VERSION ""

NS_ :

BS_:

BU_: PowertrainControlModule AtmosphericSensor SafetyRestraintSystem2 Aftertreatment_2_GasOutlet Aftertreatment_2_GasIntake DieselParticulateFilterControl Turbocharger SafetyRestraintSystem1 CabDisplay2 Aftertreatment_1_GasOutlet Aftertreatment_1_GasIntake OnBoardDataLogger OffBoardDiagnosticTool2 OffBoardDiagnosticTool1 FileServer ParkingBrakeController SeatController2 FanDriveController SteeringColumnUnit CommunicationUnitRadio CommunicationUnitSatellite CommunicationUnitCellular PropulsionBatteryCharger ChassisController2 ChassisController1 EngineValveControl AuxiliaryHeater2 AuxiliaryHeater1 ClutchUnit RampControl InformationSystem1 SuspensionSystemController2 OilSensor VehicleDynamicStability ExhaustEmissionController TransmissionDisplay2 TransmissionDisplay1 ClimateControl2 WaterPumpController RearAxleSteeringController LightingOperatorControl SeatController1 IgnitionController2 IgnitionController1 TirePressureController CabController2 CabController1 PneumaticSystemController SuspensionSystemController1 HydraulicPumpController EnduranceBrakingSystem RetarderExhaustEngine2 OnBoardDiagnosticUnit HeadwayController RetarderExhaustEngine1 CabDisplay1 ManagementComputer VirtualTerminal OffVehicleGateway PowerTakeOffFront HitchControl AuxiliaryValveControl BodyController TractorTrailerBridge1 StarterSystem ElectricalSystem VehicleSecurity VehicleNavigation AerodynamicControl ElectricalChargingSystem ClimateControl1 TripRecorder InstrumentCluster SuspensionDriveAxle2 SuspensionDriveAxle1 SuspensionSteerAxle SteeringController FuelSystem CruiseControl RetarderDriveline RetarderEngine BrakesDriveAxle2 BrakesDriveAxle1 BrakesSystemController BrakesSteerAxle AxleDrive2 AxleDrive1 AxleSteering PowerTakeOff ShiftConsoleSecondary ShiftConsolePrimary Transmission2 Transmission1 Engine2 Engine1

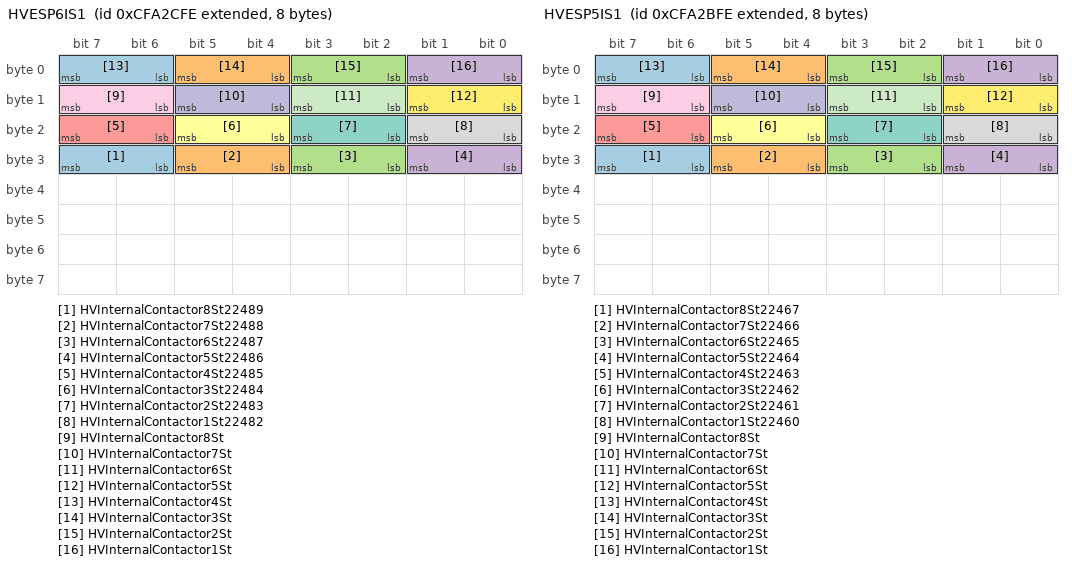
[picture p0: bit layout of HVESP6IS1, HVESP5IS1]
BO_ 2365205758 HVESP6IS1: 8 Vector__XXX
 SG_ HVInternalContactor8St22489 : 30|2@1+ (1,0) [0|3] "" Vector__XXX
 SG_ HVInternalContactor7St22488 : 28|2@1+ (1,0) [0|3] "" Vector__XXX
 SG_ HVInternalContactor6St22487 : 26|2@1+ (1,0) [0|3] "" Vector__XXX
 SG_ HVInternalContactor5St22486 : 24|2@1+ (1,0) [0|3] "" Vector__XXX
 SG_ HVInternalContactor4St22485 : 22|2@1+ (1,0) [0|3] "" Vector__XXX
 SG_ HVInternalContactor3St22484 : 20|2@1+ (1,0) [0|3] "" Vector__XXX
 SG_ HVInternalContactor2St22483 : 18|2@1+ (1,0) [0|3] "" Vector__XXX
 SG_ HVInternalContactor1St22482 : 16|2@1+ (1,0) [0|3] "" Vector__XXX
 SG_ HVInternalContactor8St : 14|2@1+ (1,0) [0|3] "" Vector__XXX
 SG_ HVInternalContactor7St : 12|2@1+ (1,0) [0|3] "" Vector__XXX
 SG_ HVInternalContactor6St : 10|2@1+ (1,0) [0|3] "" Vector__XXX
 SG_ HVInternalContactor5St : 8|2@1+ (1,0) [0|3] "" Vector__XXX
 SG_ HVInternalContactor4St : 6|2@1+ (1,0) [0|3] "" Vector__XXX
 SG_ HVInternalContactor3St : 4|2@1+ (1,0) [0|3] "" Vector__XXX
 SG_ HVInternalContactor2St : 2|2@1+ (1,0) [0|3] "" Vector__XXX
 SG_ HVInternalContactor1St : 0|2@1+ (1,0) [0|3] "" Vector__XXX

BO_ 2365205502 HVESP5IS1: 8 Vector__XXX
 SG_ HVInternalContactor8St22467 : 30|2@1+ (1,0) [0|3] "" Vector__XXX
 SG_ HVInternalContactor7St22466 : 28|2@1+ (1,0) [0|3] "" Vector__XXX
 SG_ HVInternalContactor6St22465 : 26|2@1+ (1,0) [0|3] "" Vector__XXX
 SG_ HVInternalContactor5St22464 : 24|2@1+ (1,0) [0|3] "" Vector__XXX
 SG_ HVInternalContactor4St22463 : 22|2@1+ (1,0) [0|3] "" Vector__XXX
 SG_ HVInternalContactor3St22462 : 20|2@1+ (1,0) [0|3] "" Vector__XXX
 SG_ HVInternalContactor2St22461 : 18|2@1+ (1,0) [0|3] "" Vector__XXX
 SG_ HVInternalContactor1St22460 : 16|2@1+ (1,0) [0|3] "" Vector__XXX
 SG_ HVInternalContactor8St : 14|2@1+ (1,0) [0|3] "" Vector__XXX
 SG_ HVInternalContactor7St : 12|2@1+ (1,0) [0|3] "" Vector__XXX
 SG_ HVInternalContactor6St : 10|2@1+ (1,0) [0|3] "" Vector__XXX
 SG_ HVInternalContactor5St : 8|2@1+ (1,0) [0|3] "" Vector__XXX
 SG_ HVInternalContactor4St : 6|2@1+ (1,0) [0|3] "" Vector__XXX
 SG_ HVInternalContactor3St : 4|2@1+ (1,0) [0|3] "" Vector__XXX
 SG_ HVInternalContactor2St : 2|2@1+ (1,0) [0|3] "" Vector__XXX
 SG_ HVInternalContactor1St : 0|2@1+ (1,0) [0|3] "" Vector__XXX

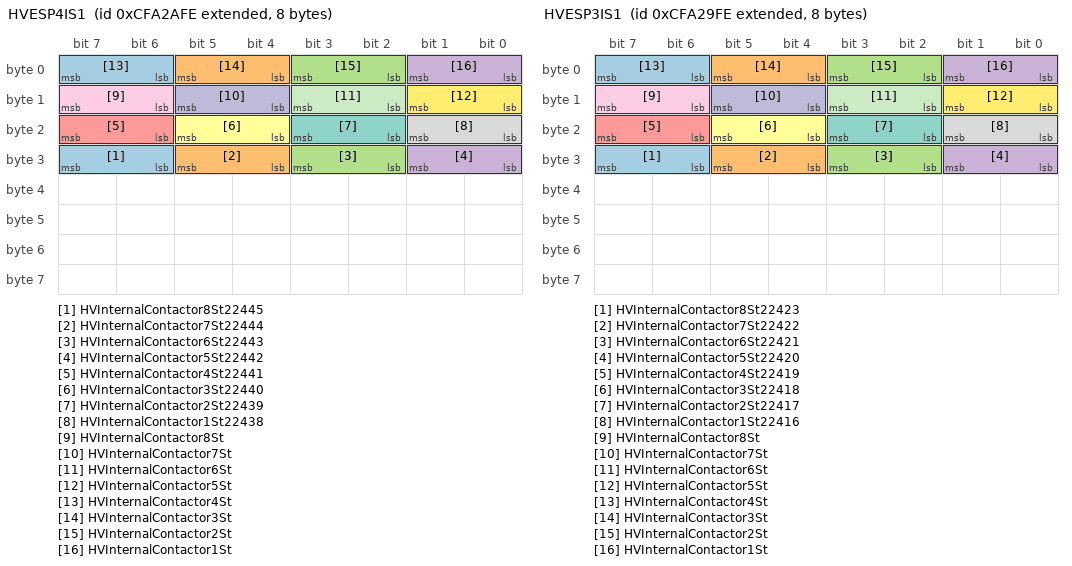
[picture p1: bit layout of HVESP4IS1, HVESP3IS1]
BO_ 2365205246 HVESP4IS1: 8 Vector__XXX
 SG_ HVInternalContactor8St22445 : 30|2@1+ (1,0) [0|3] "" Vector__XXX
 SG_ HVInternalContactor7St22444 : 28|2@1+ (1,0) [0|3] "" Vector__XXX
 SG_ HVInternalContactor6St22443 : 26|2@1+ (1,0) [0|3] "" Vector__XXX
 SG_ HVInternalContactor5St22442 : 24|2@1+ (1,0) [0|3] "" Vector__XXX
 SG_ HVInternalContactor4St22441 : 22|2@1+ (1,0) [0|3] "" Vector__XXX
 SG_ HVInternalContactor3St22440 : 20|2@1+ (1,0) [0|3] "" Vector__XXX
 SG_ HVInternalContactor2St22439 : 18|2@1+ (1,0) [0|3] "" Vector__XXX
 SG_ HVInternalContactor1St22438 : 16|2@1+ (1,0) [0|3] "" Vector__XXX
 SG_ HVInternalContactor8St : 14|2@1+ (1,0) [0|3] "" Vector__XXX
 SG_ HVInternalContactor7St : 12|2@1+ (1,0) [0|3] "" Vector__XXX
 SG_ HVInternalContactor6St : 10|2@1+ (1,0) [0|3] "" Vector__XXX
 SG_ HVInternalContactor5St : 8|2@1+ (1,0) [0|3] "" Vector__XXX
 SG_ HVInternalContactor4St : 6|2@1+ (1,0) [0|3] "" Vector__XXX
 SG_ HVInternalContactor3St : 4|2@1+ (1,0) [0|3] "" Vector__XXX
 SG_ HVInternalContactor2St : 2|2@1+ (1,0) [0|3] "" Vector__XXX
 SG_ HVInternalContactor1St : 0|2@1+ (1,0) [0|3] "" Vector__XXX

BO_ 2365204990 HVESP3IS1: 8 Vector__XXX
 SG_ HVInternalContactor8St22423 : 30|2@1+ (1,0) [0|3] "" Vector__XXX
 SG_ HVInternalContactor7St22422 : 28|2@1+ (1,0) [0|3] "" Vector__XXX
 SG_ HVInternalContactor6St22421 : 26|2@1+ (1,0) [0|3] "" Vector__XXX
 SG_ HVInternalContactor5St22420 : 24|2@1+ (1,0) [0|3] "" Vector__XXX
 SG_ HVInternalContactor4St22419 : 22|2@1+ (1,0) [0|3] "" Vector__XXX
 SG_ HVInternalContactor3St22418 : 20|2@1+ (1,0) [0|3] "" Vector__XXX
 SG_ HVInternalContactor2St22417 : 18|2@1+ (1,0) [0|3] "" Vector__XXX
 SG_ HVInternalContactor1St22416 : 16|2@1+ (1,0) [0|3] "" Vector__XXX
 SG_ HVInternalContactor8St : 14|2@1+ (1,0) [0|3] "" Vector__XXX
 SG_ HVInternalContactor7St : 12|2@1+ (1,0) [0|3] "" Vector__XXX
 SG_ HVInternalContactor6St : 10|2@1+ (1,0) [0|3] "" Vector__XXX
 SG_ HVInternalContactor5St : 8|2@1+ (1,0) [0|3] "" Vector__XXX
 SG_ HVInternalContactor4St : 6|2@1+ (1,0) [0|3] "" Vector__XXX
 SG_ HVInternalContactor3St : 4|2@1+ (1,0) [0|3] "" Vector__XXX
 SG_ HVInternalContactor2St : 2|2@1+ (1,0) [0|3] "" Vector__XXX
 SG_ HVInternalContactor1St : 0|2@1+ (1,0) [0|3] "" Vector__XXX

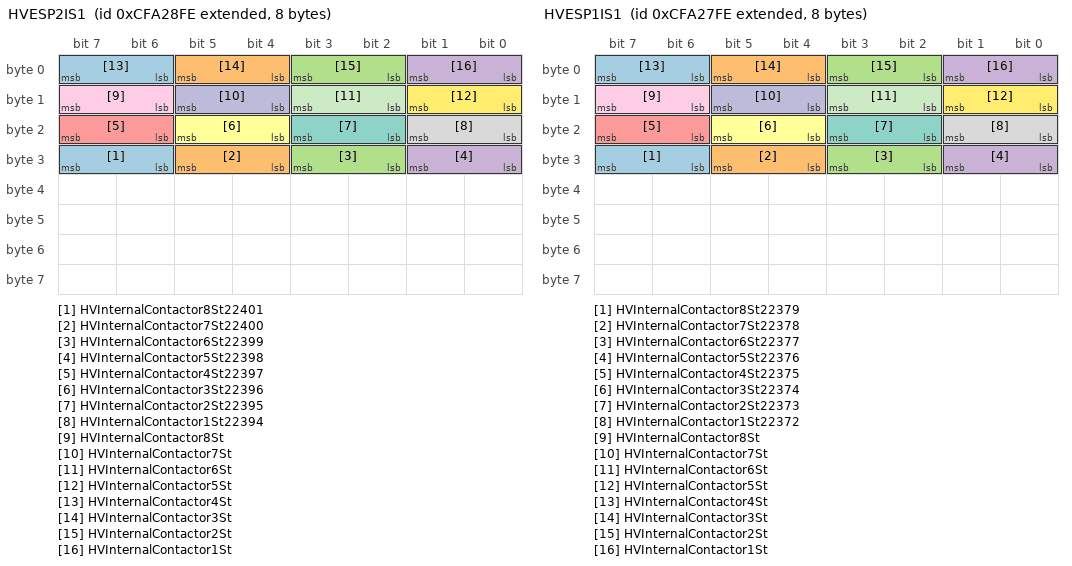
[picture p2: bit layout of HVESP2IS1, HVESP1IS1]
BO_ 2365204734 HVESP2IS1: 8 Vector__XXX
 SG_ HVInternalContactor8St22401 : 30|2@1+ (1,0) [0|3] "" Vector__XXX
 SG_ HVInternalContactor7St22400 : 28|2@1+ (1,0) [0|3] "" Vector__XXX
 SG_ HVInternalContactor6St22399 : 26|2@1+ (1,0) [0|3] "" Vector__XXX
 SG_ HVInternalContactor5St22398 : 24|2@1+ (1,0) [0|3] "" Vector__XXX
 SG_ HVInternalContactor4St22397 : 22|2@1+ (1,0) [0|3] "" Vector__XXX
 SG_ HVInternalContactor3St22396 : 20|2@1+ (1,0) [0|3] "" Vector__XXX
 SG_ HVInternalContactor2St22395 : 18|2@1+ (1,0) [0|3] "" Vector__XXX
 SG_ HVInternalContactor1St22394 : 16|2@1+ (1,0) [0|3] "" Vector__XXX
 SG_ HVInternalContactor8St : 14|2@1+ (1,0) [0|3] "" Vector__XXX
 SG_ HVInternalContactor7St : 12|2@1+ (1,0) [0|3] "" Vector__XXX
 SG_ HVInternalContactor6St : 10|2@1+ (1,0) [0|3] "" Vector__XXX
 SG_ HVInternalContactor5St : 8|2@1+ (1,0) [0|3] "" Vector__XXX
 SG_ HVInternalContactor4St : 6|2@1+ (1,0) [0|3] "" Vector__XXX
 SG_ HVInternalContactor3St : 4|2@1+ (1,0) [0|3] "" Vector__XXX
 SG_ HVInternalContactor2St : 2|2@1+ (1,0) [0|3] "" Vector__XXX
 SG_ HVInternalContactor1St : 0|2@1+ (1,0) [0|3] "" Vector__XXX

BO_ 2365204478 HVESP1IS1: 8 Vector__XXX
 SG_ HVInternalContactor8St22379 : 30|2@1+ (1,0) [0|3] "" Vector__XXX
 SG_ HVInternalContactor7St22378 : 28|2@1+ (1,0) [0|3] "" Vector__XXX
 SG_ HVInternalContactor6St22377 : 26|2@1+ (1,0) [0|3] "" Vector__XXX
 SG_ HVInternalContactor5St22376 : 24|2@1+ (1,0) [0|3] "" Vector__XXX
 SG_ HVInternalContactor4St22375 : 22|2@1+ (1,0) [0|3] "" Vector__XXX
 SG_ HVInternalContactor3St22374 : 20|2@1+ (1,0) [0|3] "" Vector__XXX
 SG_ HVInternalContactor2St22373 : 18|2@1+ (1,0) [0|3] "" Vector__XXX
 SG_ HVInternalContactor1St22372 : 16|2@1+ (1,0) [0|3] "" Vector__XXX
 SG_ HVInternalContactor8St : 14|2@1+ (1,0) [0|3] "" Vector__XXX
 SG_ HVInternalContactor7St : 12|2@1+ (1,0) [0|3] "" Vector__XXX
 SG_ HVInternalContactor6St : 10|2@1+ (1,0) [0|3] "" Vector__XXX
 SG_ HVInternalContactor5St : 8|2@1+ (1,0) [0|3] "" Vector__XXX
 SG_ HVInternalContactor4St : 6|2@1+ (1,0) [0|3] "" Vector__XXX
 SG_ HVInternalContactor3St : 4|2@1+ (1,0) [0|3] "" Vector__XXX
 SG_ HVInternalContactor2St : 2|2@1+ (1,0) [0|3] "" Vector__XXX
 SG_ HVInternalContactor1St : 0|2@1+ (1,0) [0|3] "" Vector__XXX

BO_ 2365204222 HVESSD14: 8 Vector__XXX
 SG_ BusV : 32|16@1+ (0.125,0) [0|8031.875] "V" Vector__XXX
 SG_ MaxCurChargeCurLmt : 16|16@1+ (0.125,-4000) [0|4031.875] "A" Vector__XXX
 SG_ MaxCurDisCurLmt : 0|16@1+ (0.125,-4000) [-4000|0] "A" Vector__XXX

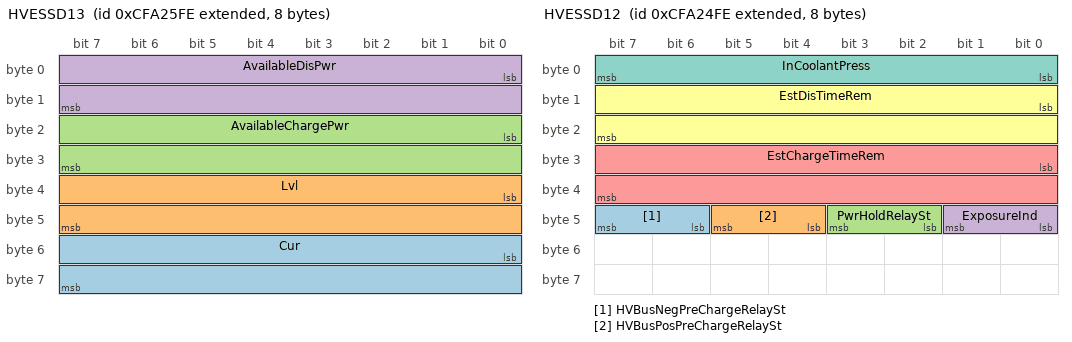
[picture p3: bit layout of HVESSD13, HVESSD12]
BO_ 2365203966 HVESSD13: 8 Vector__XXX
 SG_ Cur : 48|16@1+ (0.125,-4000) [-4000|4031.875] "A" Vector__XXX
 SG_ Lvl : 32|16@1+ (0.125,0) [0|8031.875] "V" Vector__XXX
 SG_ AvailableChargePwr : 16|16@1+ (0.25,0) [0|16063.75] "kW" Vector__XXX
 SG_ AvailableDisPwr : 0|16@1+ (0.25,0) [0|16063.75] "kW" Vector__XXX

BO_ 2365203710 HVESSD12: 8 Vector__XXX
 SG_ HVBusNegPreChargeRelaySt : 46|2@1+ (1,0) [0|3] "" Vector__XXX
 SG_ HVBusPosPreChargeRelaySt : 44|2@1+ (1,0) [0|3] "" Vector__XXX
 SG_ PwrHoldRelaySt : 42|2@1+ (1,0) [0|3] "" Vector__XXX
 SG_ ExposureInd : 40|2@1+ (1,0) [0|3] "" Vector__XXX
 SG_ EstChargeTimeRem : 24|16@1+ (0.1,0) [0|6425.5] "min" Vector__XXX
 SG_ EstDisTimeRem : 8|16@1+ (0.1,0) [0|6425.5] "min" Vector__XXX
 SG_ InCoolantPress : 0|8@1+ (2,0) [0|500] "kPa" Vector__XXX

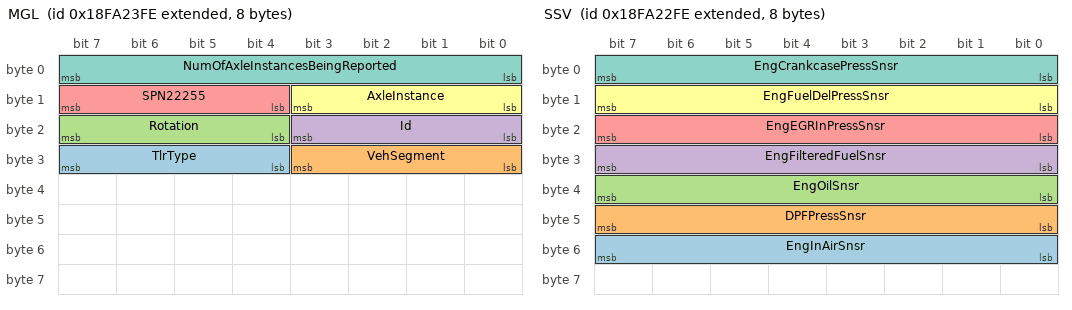
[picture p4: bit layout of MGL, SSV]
BO_ 2566530046 MGL: 8 Vector__XXX
 SG_ TlrType : 28|4@1+ (1,0) [0|15] "" Vector__XXX
 SG_ VehSegment : 24|4@1+ (1,0) [0|15] "" Vector__XXX
 SG_ Rotation : 20|4@1+ (1,0) [0|15] "" Vector__XXX
 SG_ Id : 16|4@1+ (1,0) [0|15] "" Vector__XXX
 SG_ SPN22255 : 12|4@1+ (1,0) [0|15] "" Vector__XXX
 SG_ AxleInstance : 8|4@1+ (1,0) [0|15] "" Vector__XXX
 SG_ NumOfAxleInstancesBeingReported : 0|8@1+ (1,0) [0|255] "" Vector__XXX

BO_ 2566529790 SSV: 8 Vector__XXX
 SG_ EngInAirSnsr : 48|8@1+ (0.05,0) [0|12.5] "V" Vector__XXX
 SG_ DPFPressSnsr : 40|8@1+ (0.05,0) [0|12.5] "V" Vector__XXX
 SG_ EngOilSnsr : 32|8@1+ (0.05,0) [0|12.5] "V" Vector__XXX
 SG_ EngFilteredFuelSnsr : 24|8@1+ (0.05,0) [0|12.5] "V" Vector__XXX
 SG_ EngEGRInPressSnsr : 16|8@1+ (0.05,0) [0|12.5] "V" Vector__XXX
 SG_ EngFuelDelPressSnsr : 8|8@1+ (0.05,0) [0|12.5] "V" Vector__XXX
 SG_ EngCrankcasePressSnsr : 0|8@1+ (0.05,0) [0|12.5] "V" Vector__XXX

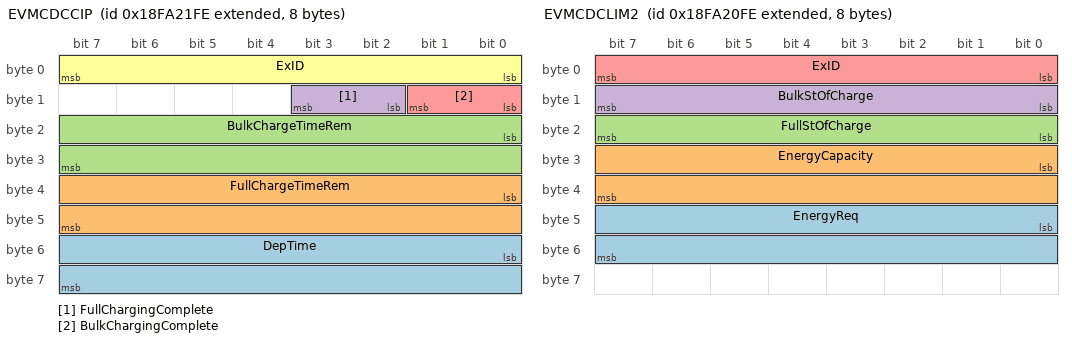
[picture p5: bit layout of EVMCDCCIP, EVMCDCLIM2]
BO_ 2566529534 EVMCDCCIP: 8 Vector__XXX
 SG_ DepTime : 48|16@1+ (10,0) [0|642550] "s" Vector__XXX
 SG_ FullChargeTimeRem : 32|16@1+ (10,0) [0|642550] "s" Vector__XXX
 SG_ BulkChargeTimeRem : 16|16@1+ (10,0) [0|642550] "s" Vector__XXX
 SG_ FullChargingComplete : 10|2@1+ (1,0) [0|3] "" Vector__XXX
 SG_ BulkChargingComplete : 8|2@1+ (1,0) [0|3] "" Vector__XXX
 SG_ ExID : 0|8@1+ (1,0) [0|255] "" Vector__XXX

BO_ 2566529278 EVMCDCLIM2: 8 Vector__XXX
 SG_ EnergyReq : 40|16@1+ (1,0) [0|64255] "kWh" Vector__XXX
 SG_ EnergyCapacity : 24|16@1+ (1,0) [0|64255] "kWh" Vector__XXX
 SG_ FullStOfCharge : 16|8@1+ (0.5,0) [0|125] "%" Vector__XXX
 SG_ BulkStOfCharge : 8|8@1+ (0.5,0) [0|125] "%" Vector__XXX
 SG_ ExID : 0|8@1+ (1,0) [0|255] "" Vector__XXX

BO_ 2633637886 ASI6: 8 Vector__XXX
 SG_ TwoDEFDosingMode : 0|8@1+ (1,0) [0|250] "" Vector__XXX

BO_ 2365202174 HVBCS: 8 Vector__XXX
 SG_ CRC : 56|8@1+ (1,0) [0|255] "" Vector__XXX
 SG_ Counter : 52|4@1+ (1,0) [0|15] "" Vector__XXX
 SG_ EmbeddedIntegritySupport : 50|2@1+ (1,0) [0|3] "" Vector__XXX
 SG_ HVBusInterface8NegContactorSt : 30|2@1+ (1,0) [0|3] "" Vector__XXX
 SG_ HVBusInterface8PosContactorSt : 28|2@1+ (1,0) [0|3] "" Vector__XXX
 SG_ HVBusInterface7NegContactorSt : 26|2@1+ (1,0) [0|3] "" Vector__XXX
 SG_ HVBusInterface7PosContactorSt : 24|2@1+ (1,0) [0|3] "" Vector__XXX
 SG_ HVBusInterface6NegContactorSt : 22|2@1+ (1,0) [0|3] "" Vector__XXX
 SG_ HVBusInterface6PosContactorSt : 20|2@1+ (1,0) [0|3] "" Vector__XXX
 SG_ HVBusInterface5NegContactorSt : 18|2@1+ (1,0) [0|3] "" Vector__XXX
 SG_ HVBusInterface5PosContactorSt : 16|2@1+ (1,0) [0|3] "" Vector__XXX
 SG_ HVBusInterface4NegContactorSt : 14|2@1+ (1,0) [0|3] "" Vector__XXX
 SG_ HVBusInterface4PosContactorSt : 12|2@1+ (1,0) [0|3] "" Vector__XXX
 SG_ HVBusInterface3NegContactorSt : 10|2@1+ (1,0) [0|3] "" Vector__XXX
 SG_ HVBusInterface3PosContactorSt : 8|2@1+ (1,0) [0|3] "" Vector__XXX
 SG_ HVBusInterface2NegContactorSt : 6|2@1+ (1,0) [0|3] "" Vector__XXX
 SG_ HVBusInterface2PosContactorSt : 4|2@1+ (1,0) [0|3] "" Vector__XXX
 SG_ HVBusInterface1NegContactorSt : 2|2@1+ (1,0) [0|3] "" Vector__XXX
 SG_ HVBusInterface1PosContactorSt : 0|2@1+ (1,0) [0|3] "" Vector__XXX

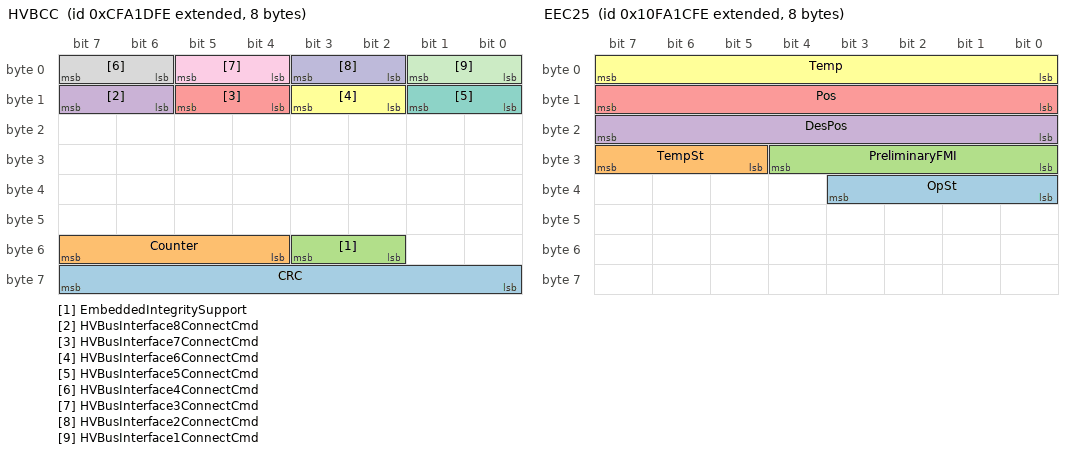
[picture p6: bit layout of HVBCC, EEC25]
BO_ 2365201918 HVBCC: 8 Vector__XXX
 SG_ CRC : 56|8@1+ (1,0) [0|255] "" Vector__XXX
 SG_ Counter : 52|4@1+ (1,0) [0|15] "" Vector__XXX
 SG_ EmbeddedIntegritySupport : 50|2@1+ (1,0) [0|3] "" Vector__XXX
 SG_ HVBusInterface8ConnectCmd : 14|2@1+ (1,0) [0|3] "" Vector__XXX
 SG_ HVBusInterface7ConnectCmd : 12|2@1+ (1,0) [0|3] "" Vector__XXX
 SG_ HVBusInterface6ConnectCmd : 10|2@1+ (1,0) [0|3] "" Vector__XXX
 SG_ HVBusInterface5ConnectCmd : 8|2@1+ (1,0) [0|3] "" Vector__XXX
 SG_ HVBusInterface4ConnectCmd : 6|2@1+ (1,0) [0|3] "" Vector__XXX
 SG_ HVBusInterface3ConnectCmd : 4|2@1+ (1,0) [0|3] "" Vector__XXX
 SG_ HVBusInterface2ConnectCmd : 2|2@1+ (1,0) [0|3] "" Vector__XXX
 SG_ HVBusInterface1ConnectCmd : 0|2@1+ (1,0) [0|3] "" Vector__XXX

BO_ 2432310526 EEC25: 8 Vector__XXX
 SG_ OpSt : 32|4@1+ (1,0) [0|15] "" Vector__XXX
 SG_ TempSt : 29|3@1+ (1,0) [0|7] "" Vector__XXX
 SG_ PreliminaryFMI : 24|5@1+ (1,0) [0|31] "" Vector__XXX
 SG_ DesPos : 16|8@1+ (0.4,0) [0|100] "%" Vector__XXX
 SG_ Pos : 8|8@1+ (0.4,0) [0|100] "%" Vector__XXX
 SG_ Temp : 0|8@1+ (1,-40) [-40|210] "°C" Vector__XXX

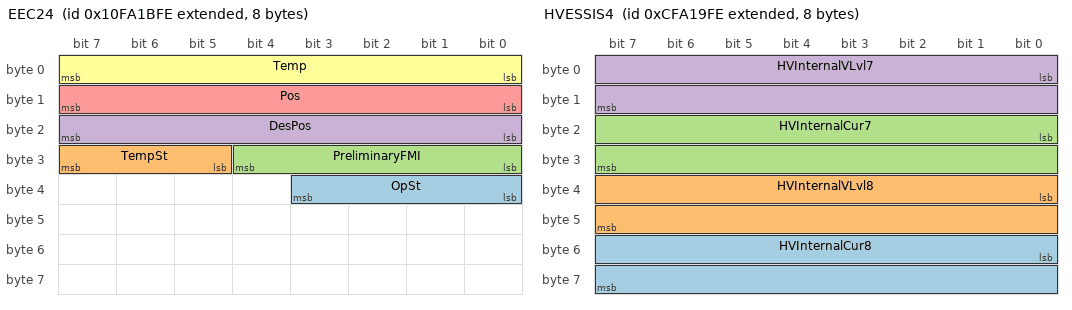
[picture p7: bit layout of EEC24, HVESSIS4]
BO_ 2432310270 EEC24: 8 Vector__XXX
 SG_ OpSt : 32|4@1+ (1,0) [0|15] "" Vector__XXX
 SG_ TempSt : 29|3@1+ (1,0) [0|7] "" Vector__XXX
 SG_ PreliminaryFMI : 24|5@1+ (1,0) [0|31] "" Vector__XXX
 SG_ DesPos : 16|8@1+ (0.4,0) [0|100] "%" Vector__XXX
 SG_ Pos : 8|8@1+ (0.4,0) [0|100] "%" Vector__XXX
 SG_ Temp : 0|8@1+ (1,-40) [-40|210] "°C" Vector__XXX

BO_ 2432310014 EEC23: 8 Vector__XXX
 SG_ Cmd2 : 16|16@1+ (0.0025,0) [0|160.6375] "%" Vector__XXX
 SG_ Cmd1 : 0|16@1+ (0.0025,0) [0|160.6375] "%" Vector__XXX

BO_ 2365200894 HVESSIS4: 8 Vector__XXX
 SG_ HVInternalCur8 : 48|16@1+ (0.125,-4000) [-4000|4031.875] "A" Vector__XXX
 SG_ HVInternalVLvl8 : 32|16@1+ (0.125,0) [0|8031.875] "V" Vector__XXX
 SG_ HVInternalCur7 : 16|16@1+ (0.125,-4000) [-4000|4031.875] "A" Vector__XXX
 SG_ HVInternalVLvl7 : 0|16@1+ (0.125,0) [0|8031.875] "V" Vector__XXX

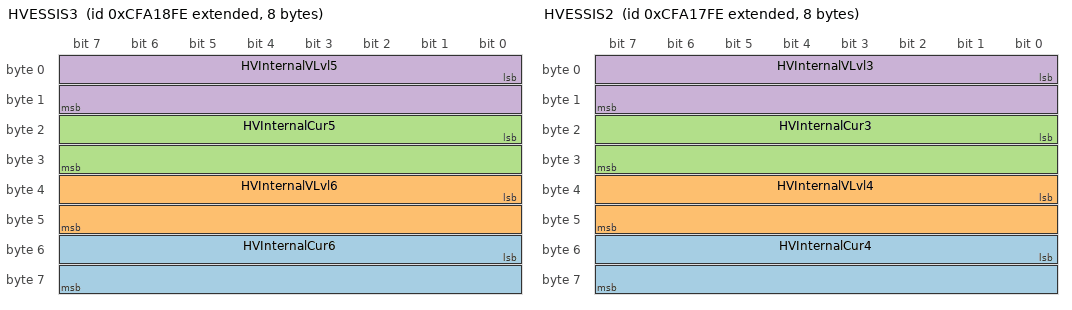
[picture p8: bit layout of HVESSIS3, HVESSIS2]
BO_ 2365200638 HVESSIS3: 8 Vector__XXX
 SG_ HVInternalCur6 : 48|16@1+ (0.125,-4000) [-4000|4031.875] "A" Vector__XXX
 SG_ HVInternalVLvl6 : 32|16@1+ (0.125,0) [0|8031.875] "V" Vector__XXX
 SG_ HVInternalCur5 : 16|16@1+ (0.125,-4000) [-4000|4031.875] "A" Vector__XXX
 SG_ HVInternalVLvl5 : 0|16@1+ (0.125,0) [0|8031.875] "V" Vector__XXX

BO_ 2365200382 HVESSIS2: 8 Vector__XXX
 SG_ HVInternalCur4 : 48|16@1+ (0.125,-4000) [-4000|4031.875] "A" Vector__XXX
 SG_ HVInternalVLvl4 : 32|16@1+ (0.125,0) [0|8031.875] "V" Vector__XXX
 SG_ HVInternalCur3 : 16|16@1+ (0.125,-4000) [-4000|4031.875] "A" Vector__XXX
 SG_ HVInternalVLvl3 : 0|16@1+ (0.125,0) [0|8031.875] "V" Vector__XXX

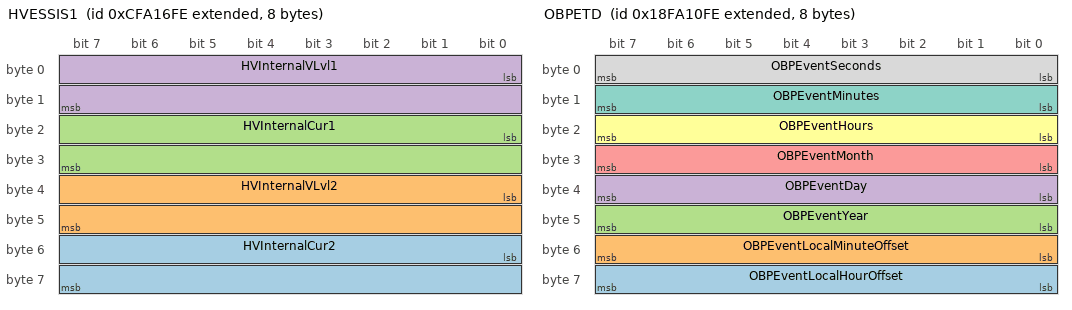
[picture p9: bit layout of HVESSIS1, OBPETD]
BO_ 2365200126 HVESSIS1: 8 Vector__XXX
 SG_ HVInternalCur2 : 48|16@1+ (0.125,-4000) [-4000|4031.875] "A" Vector__XXX
 SG_ HVInternalVLvl2 : 32|16@1+ (0.125,0) [0|8031.875] "V" Vector__XXX
 SG_ HVInternalCur1 : 16|16@1+ (0.125,-4000) [-4000|4031.875] "A" Vector__XXX
 SG_ HVInternalVLvl1 : 0|16@1+ (0.125,0) [0|8031.875] "V" Vector__XXX

BO_ 2499417598 GSF: 8 Vector__XXX
 SG_ GenSimulatedUtilFreqDeactTimer : 16|16@1+ (0.01,0) [0|642.55] "ms" Vector__XXX
 SG_ GenSimulatedUtilFreqResult : 0|16@1+ (0.01,-321.28) [-321.28|321.27] "Hz" Vector__XXX

BO_ 2566526206 CSERSA: 20 Vector__XXX
 SG_ AvgTimeUntilCatColdStartTrkTemp : 144|16@1+ (1,0) [0|64255] "s" Vector__XXX
 SG_ AvgTimeUntilEngOutput : 128|16@1+ (1,0) [0|64255] "s" Vector__XXX
 SG_ AvgEGRMassUntilFtpTemp : 112|16@1+ (5,0) [0|321275] "g" Vector__XXX
 SG_ AvgEGRMassAtEngOutput : 96|16@1+ (5,0) [0|321275] "g" Vector__XXX
 SG_ AvgEGRMassAtColdStart : 80|16@1+ (5,0) [0|321275] "g" Vector__XXX
 SG_ EngEtilCatTempThld : 64|16@1+ (5,0) [0|321275] "kJ" Vector__XXX
 SG_ EngEtilColdStart : 48|16@1+ (5,0) [0|321275] "kJ" Vector__XXX
 SG_ CatEtilCatTempThld : 32|16@1+ (1,0) [0|64255] "kJ" Vector__XXX
 SG_ CatEtilEngOutput : 16|16@1+ (1,0) [0|64255] "kJ" Vector__XXX
 SG_ CatEtilColdStart : 0|16@1+ (1,0) [0|64255] "kJ" Vector__XXX

BO_ 2566525950 CSERSC: 20 Vector__XXX
 SG_ TimeUntilCatTempThld : 144|16@1+ (1,0) [0|64255] "s" Vector__XXX
 SG_ TimeUntilEngOutput : 128|16@1+ (1,0) [0|64255] "s" Vector__XXX
 SG_ EgrMassUntilCatTempThld : 112|16@1+ (5,0) [0|321275] "g" Vector__XXX
 SG_ EgrMassUntilEngOutput : 96|16@1+ (5,0) [0|321275] "g" Vector__XXX
 SG_ EgrMassUntilColdStart : 80|16@1+ (5,0) [0|321275] "g" Vector__XXX
 SG_ EngOutEnergyUntilCatTempThld : 64|16@1+ (5,0) [0|321275] "kJ" Vector__XXX
 SG_ EngOutEnergyUntilColdStart : 48|16@1+ (5,0) [0|321275] "kJ" Vector__XXX
 SG_ CatHeatEnergyUntilCatTempThld : 32|16@1+ (1,0) [0|64255] "kJ" Vector__XXX
 SG_ CatHeatEnergyUntilEngOutput : 16|16@1+ (1,0) [0|64255] "kJ" Vector__XXX
 SG_ CatHeatEnergyUntilColdStart : 0|16@1+ (1,0) [0|64255] "kJ" Vector__XXX

BO_ 2566525694 MGLE: 8 Vector__XXX
 SG_ VehSegment_4 : 192|4@1+ (1,0) [0|15] "" Vector__XXX
 SG_ TrailerType_4 : 196|4@1+ (1,0) [0|15] "" Vector__XXX
 SG_ MotGenRotation_4 : 188|4@1+ (1,0) [0|15] "" Vector__XXX
 SG_ MotGenLocation_4 : 180|4@1+ (1,0) [0|15] "" Vector__XXX
 SG_ MotGenIdentification_4 : 184|4@1+ (1,0) [0|15] "" Vector__XXX
 SG_ AxleInstance_4 : 176|4@1+ (1,0) [0|15] "" Vector__XXX
 SG_ VehSegment_3 : 136|4@1+ (1,0) [0|15] "" Vector__XXX
 SG_ TrailerType_3 : 140|4@1+ (1,0) [0|15] "" Vector__XXX
 SG_ MotGenRotation_3 : 132|4@1+ (1,0) [0|15] "" Vector__XXX
 SG_ MotGenLocation_3 : 124|4@1+ (1,0) [0|15] "" Vector__XXX
 SG_ MotGenIdentification_3 : 128|4@1+ (1,0) [0|15] "" Vector__XXX
 SG_ AxleInstance_3 : 120|4@1+ (1,0) [0|15] "" Vector__XXX
 SG_ VehSegment_2 : 80|4@1+ (1,0) [0|15] "" Vector__XXX
 SG_ TrailerType_2 : 84|4@1+ (1,0) [0|15] "" Vector__XXX
 SG_ MotGenRotation_2 : 76|4@1+ (1,0) [0|15] "" Vector__XXX
 SG_ MotGenLocation_2 : 68|4@1+ (1,0) [0|15] "" Vector__XXX
 SG_ MotGenIdentification_2 : 72|4@1+ (1,0) [0|15] "" Vector__XXX
 SG_ AxleInstance_2 : 64|4@1+ (1,0) [0|15] "" Vector__XXX
 SG_ SA_4 : 200|8@1+ (1,0) [0|255] "" Vector__XXX
 SG_ SA_3 : 144|8@1+ (1,0) [0|255] "" Vector__XXX
 SG_ SA_2 : 88|8@1+ (1,0) [0|255] "" Vector__XXX
 SG_ SA_1 : 32|8@1+ (1,0) [0|255] "" Vector__XXX
 SG_ TrailerType_1 : 28|4@1+ (1,0) [0|15] "" Vector__XXX
 SG_ VehSegment_1 : 24|4@1+ (1,0) [0|15] "" Vector__XXX
 SG_ MotGenRotation_1 : 20|4@1+ (1,0) [0|15] "" Vector__XXX
 SG_ MotGenIdentification_1 : 16|4@1+ (1,0) [0|15] "" Vector__XXX
 SG_ MotGenLocation_1 : 12|4@1+ (1,0) [0|15] "" Vector__XXX
 SG_ AxleInstance_1 : 8|4@1+ (1,0) [0|15] "" Vector__XXX
 SG_ NumOfAxleInstancesBeingReported : 0|8@1+ (1,0) [0|255] "" Vector__XXX

BO_ 2566525438 A1LOSCRSI1: 8 Vector__XXX
 SG_ TripLightOffSCRDEF : 32|32@1+ (0.05,0) [0|210554060.75] "l" Vector__XXX
 SG_ TotalLightOffSCRDEFUsed : 0|32@1+ (0.05,0) [0|210554060.75] "l" Vector__XXX

BO_ 2566525182 OBPETD: 8 Vector__XXX
 SG_ OBPEventLocalHourOffset : 56|8@1+ (1,-125) [-23|23] "h" Vector__XXX
 SG_ OBPEventLocalMinuteOffset : 48|8@1+ (1,-125) [-59|59] "min" Vector__XXX
 SG_ OBPEventYear : 40|8@1+ (1,1985) [1985|2235] "year" Vector__XXX
 SG_ OBPEventDay : 32|8@1+ (0.25,0) [0.25|31.75] "days" Vector__XXX
 SG_ OBPEventMonth : 24|8@1+ (1,0) [1|12] "month" Vector__XXX
 SG_ OBPEventHours : 16|8@1+ (1,0) [0|23] "h" Vector__XXX
 SG_ OBPEventMinutes : 8|8@1+ (1,0) [0|59] "min" Vector__XXX
 SG_ OBPEventSeconds : 0|8@1+ (0.25,0) [0|59.75] "s" Vector__XXX

BO_ 2566524926 MG6TPS: 8 Vector__XXX
 SG_ CapLmt : 8|8@1+ (0.4,0) [0|100] "%" Vector__XXX
 SG_ CapUsed : 0|8@1+ (0.4,0) [0|100] "%" Vector__XXX

BO_ 2566524670 MG5TPS: 8 Vector__XXX
 SG_ CapLmt : 8|8@1+ (0.4,0) [0|100] "%" Vector__XXX
 SG_ CapUsed : 0|8@1+ (0.4,0) [0|100] "%" Vector__XXX

BO_ 2566524414 MG4TPS: 8 Vector__XXX
 SG_ CapLmt : 8|8@1+ (0.4,0) [0|100] "%" Vector__XXX
 SG_ CapUsed : 0|8@1+ (0.4,0) [0|100] "%" Vector__XXX

BO_ 2566524158 MG3TPS: 8 Vector__XXX
 SG_ CapLmt : 8|8@1+ (0.4,0) [0|100] "%" Vector__XXX
 SG_ CapUsed : 0|8@1+ (0.4,0) [0|100] "%" Vector__XXX

BO_ 2566523902 MG2TPS: 8 Vector__XXX
 SG_ CapLmt : 8|8@1+ (0.4,0) [0|100] "%" Vector__XXX
 SG_ CapUsed : 0|8@1+ (0.4,0) [0|100] "%" Vector__XXX

BO_ 2566523646 MG1TPS: 8 Vector__XXX
 SG_ CapLmt : 8|8@1+ (0.4,0) [0|100] "%" Vector__XXX
 SG_ CapUsed : 0|8@1+ (0.4,0) [0|100] "%" Vector__XXX

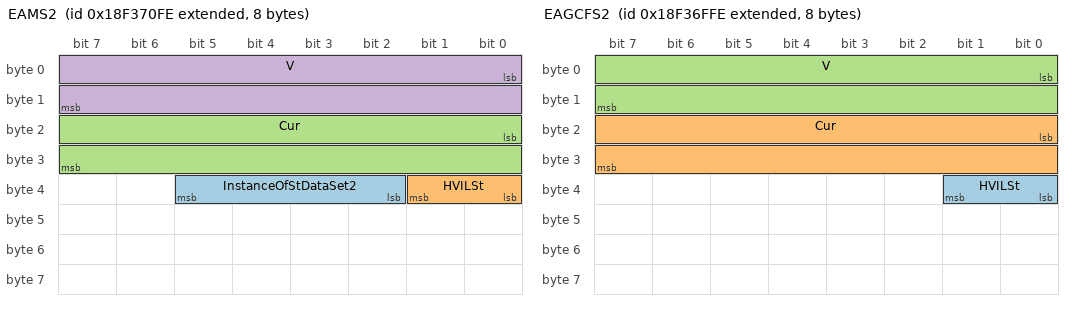
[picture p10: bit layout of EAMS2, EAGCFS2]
BO_ 2566091006 EAMS2: 8 Vector__XXX
 SG_ InstanceOfStDataSet2 : 34|4@1+ (1,0) [0|15] "" Vector__XXX
 SG_ HVILSt : 32|2@1+ (1,0) [0|3] "" Vector__XXX
 SG_ Cur : 16|16@1+ (0.05,-1600) [-1600|1612.75] "A" Vector__XXX
 SG_ V : 0|16@1+ (0.05,0) [0|3212.75] "V" Vector__XXX

BO_ 2566090750 EAGCFS2: 8 Vector__XXX
 SG_ HVILSt : 32|2@1+ (1,0) [0|3] "" Vector__XXX
 SG_ Cur : 16|16@1+ (0.05,-1600) [-1600|1612.75] "A" Vector__XXX
 SG_ V : 0|16@1+ (0.05,0) [0|3212.75] "V" Vector__XXX

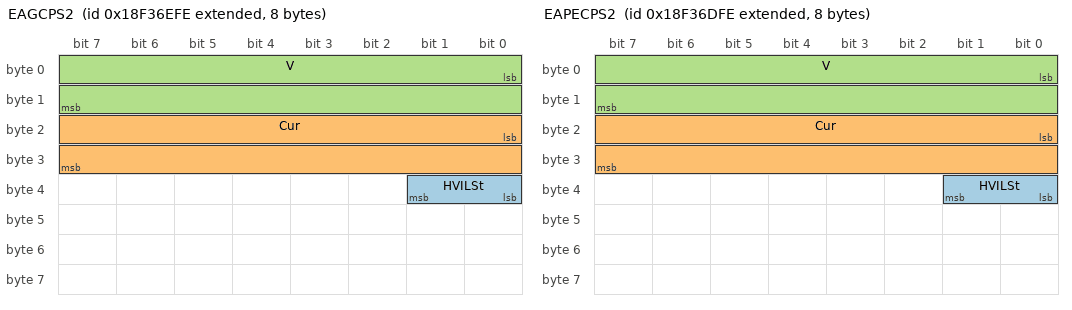
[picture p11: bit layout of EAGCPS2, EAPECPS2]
BO_ 2566090494 EAGCPS2: 8 Vector__XXX
 SG_ HVILSt : 32|2@1+ (1,0) [0|3] "" Vector__XXX
 SG_ Cur : 16|16@1+ (0.05,-1600) [-1600|1612.75] "A" Vector__XXX
 SG_ V : 0|16@1+ (0.05,0) [0|3212.75] "V" Vector__XXX

BO_ 2566090238 EAPECPS2: 8 Vector__XXX
 SG_ HVILSt : 32|2@1+ (1,0) [0|3] "" Vector__XXX
 SG_ Cur : 16|16@1+ (0.05,-1600) [-1600|1612.75] "A" Vector__XXX
 SG_ V : 0|16@1+ (0.05,0) [0|3212.75] "V" Vector__XXX

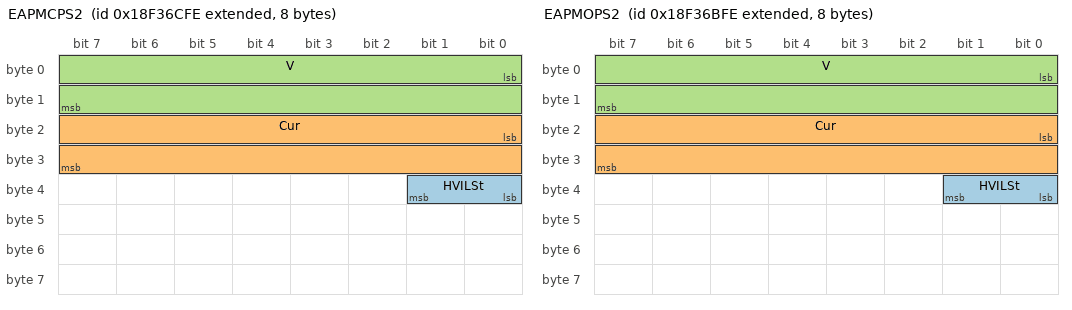
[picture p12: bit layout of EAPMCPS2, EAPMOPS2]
BO_ 2566089982 EAPMCPS2: 8 Vector__XXX
 SG_ HVILSt : 32|2@1+ (1,0) [0|3] "" Vector__XXX
 SG_ Cur : 16|16@1+ (0.05,-1600) [-1600|1612.75] "A" Vector__XXX
 SG_ V : 0|16@1+ (0.05,0) [0|3212.75] "V" Vector__XXX

BO_ 2566089726 EAPMOPS2: 8 Vector__XXX
 SG_ HVILSt : 32|2@1+ (1,0) [0|3] "" Vector__XXX
 SG_ Cur : 16|16@1+ (0.05,-1600) [-1600|1612.75] "A" Vector__XXX
 SG_ V : 0|16@1+ (0.05,0) [0|3212.75] "V" Vector__XXX

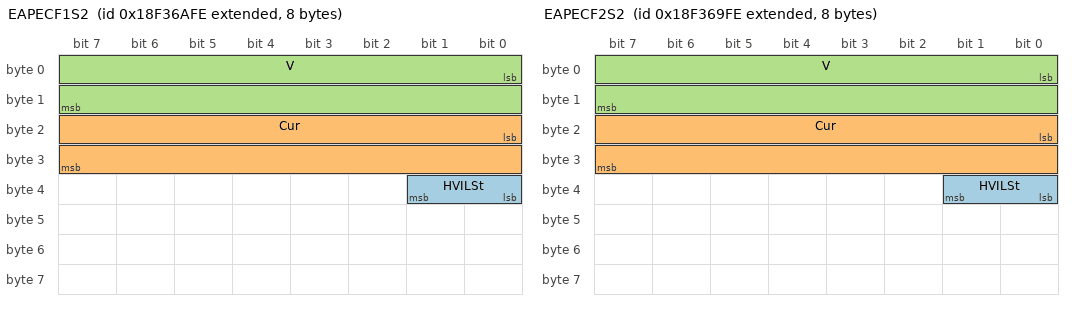
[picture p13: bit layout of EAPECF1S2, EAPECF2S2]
BO_ 2566089470 EAPECF1S2: 8 Vector__XXX
 SG_ HVILSt : 32|2@1+ (1,0) [0|3] "" Vector__XXX
 SG_ Cur : 16|16@1+ (0.05,-1600) [-1600|1612.75] "A" Vector__XXX
 SG_ V : 0|16@1+ (0.05,0) [0|3212.75] "V" Vector__XXX

BO_ 2566089214 EAPECF2S2: 8 Vector__XXX
 SG_ HVILSt : 32|2@1+ (1,0) [0|3] "" Vector__XXX
 SG_ Cur : 16|16@1+ (0.05,-1600) [-1600|1612.75] "A" Vector__XXX
 SG_ V : 0|16@1+ (0.05,0) [0|3212.75] "V" Vector__XXX

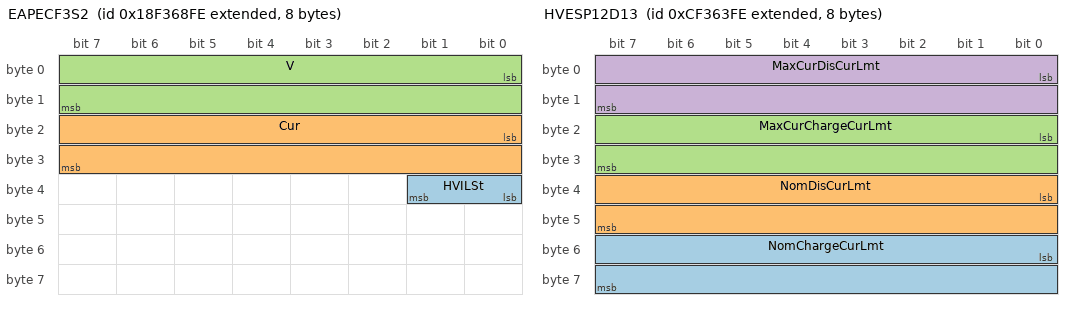
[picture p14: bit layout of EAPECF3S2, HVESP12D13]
BO_ 2566088958 EAPECF3S2: 8 Vector__XXX
 SG_ HVILSt : 32|2@1+ (1,0) [0|3] "" Vector__XXX
 SG_ Cur : 16|16@1+ (0.05,-1600) [-1600|1612.75] "A" Vector__XXX
 SG_ V : 0|16@1+ (0.05,0) [0|3212.75] "V" Vector__XXX

BO_ 2566088702 EAPMCF1S2: 8 Vector__XXX
 SG_ HVILSt : 32|2@1+ (1,0) [0|3] "" Vector__XXX
 SG_ Cur : 16|16@1+ (0.05,-1600) [-1600|1612.75] "A" Vector__XXX
 SG_ V : 0|16@1+ (0.05,0) [0|3212.75] "V" Vector__XXX

BO_ 2566088446 EAPMCF2S2: 8 Vector__XXX
 SG_ HVILSt : 32|2@1+ (1,0) [0|3] "" Vector__XXX
 SG_ Cur : 16|16@1+ (0.05,-1600) [-1600|1612.75] "A" Vector__XXX
 SG_ V : 0|16@1+ (0.05,0) [0|3212.75] "V" Vector__XXX

BO_ 2566088190 EAPMCF3S2: 8 Vector__XXX
 SG_ HVILSt : 32|2@1+ (1,0) [0|3] "" Vector__XXX
 SG_ Cur : 16|16@1+ (0.05,-1600) [-1600|1612.75] "A" Vector__XXX
 SG_ V : 0|16@1+ (0.05,0) [0|3212.75] "V" Vector__XXX

BO_ 2364761342 TVD: 8 Vector__XXX
 SG_ RightTransOutShaftDirSpd : 16|16@1+ (0.25,-8031.75) [-8031.75|8032] "rpm" Vector__XXX
 SG_ LeftTransOutShaftDirSpd : 0|16@1+ (0.25,-8031.75) [-8031.75|8032] "rpm" Vector__XXX

BO_ 2364761086 HVESP12D13: 8 Vector__XXX
 SG_ NomChargeCurLmt : 48|16@1+ (0.125,-4000) [0|4031.875] "A" Vector__XXX
 SG_ NomDisCurLmt : 32|16@1+ (0.125,-4000) [-4000|0] "A" Vector__XXX
 SG_ MaxCurChargeCurLmt : 16|16@1+ (0.125,-4000) [0|4031.875] "A" Vector__XXX
 SG_ MaxCurDisCurLmt : 0|16@1+ (0.125,-4000) [-4000|0] "A" Vector__XXX

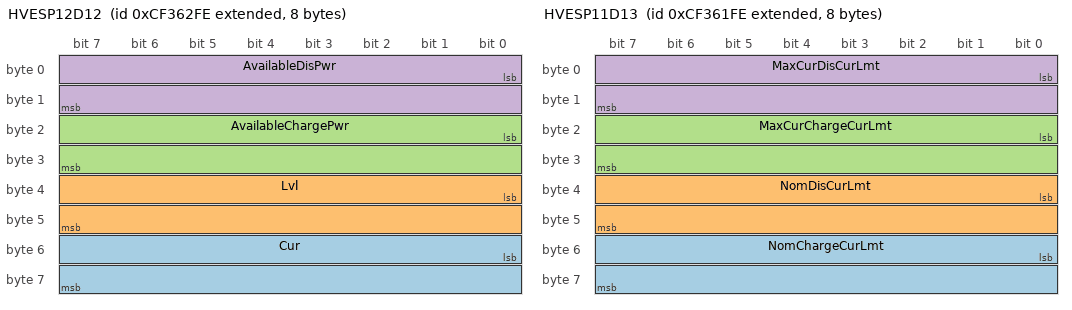
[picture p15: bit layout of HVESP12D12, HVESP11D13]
BO_ 2364760830 HVESP12D12: 8 Vector__XXX
 SG_ Cur : 48|16@1+ (0.125,-4000) [-4000|4031.875] "A" Vector__XXX
 SG_ Lvl : 32|16@1+ (0.125,0) [0|8031.875] "V" Vector__XXX
 SG_ AvailableChargePwr : 16|16@1+ (0.25,0) [0|16063.75] "kW" Vector__XXX
 SG_ AvailableDisPwr : 0|16@1+ (0.25,0) [0|16063.75] "kW" Vector__XXX

BO_ 2364760574 HVESP11D13: 8 Vector__XXX
 SG_ NomChargeCurLmt : 48|16@1+ (0.125,-4000) [0|4031.875] "A" Vector__XXX
 SG_ NomDisCurLmt : 32|16@1+ (0.125,-4000) [-4000|0] "A" Vector__XXX
 SG_ MaxCurChargeCurLmt : 16|16@1+ (0.125,-4000) [0|4031.875] "A" Vector__XXX
 SG_ MaxCurDisCurLmt : 0|16@1+ (0.125,-4000) [-4000|0] "A" Vector__XXX

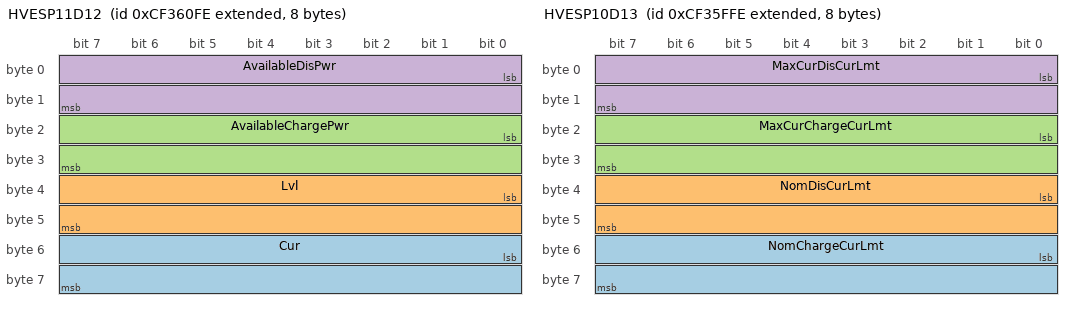
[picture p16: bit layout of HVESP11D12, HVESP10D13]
BO_ 2364760318 HVESP11D12: 8 Vector__XXX
 SG_ Cur : 48|16@1+ (0.125,-4000) [-4000|4031.875] "A" Vector__XXX
 SG_ Lvl : 32|16@1+ (0.125,0) [0|8031.875] "V" Vector__XXX
 SG_ AvailableChargePwr : 16|16@1+ (0.25,0) [0|16063.75] "kW" Vector__XXX
 SG_ AvailableDisPwr : 0|16@1+ (0.25,0) [0|16063.75] "kW" Vector__XXX

BO_ 2364760062 HVESP10D13: 8 Vector__XXX
 SG_ NomChargeCurLmt : 48|16@1+ (0.125,-4000) [0|4031.875] "A" Vector__XXX
 SG_ NomDisCurLmt : 32|16@1+ (0.125,-4000) [-4000|0] "A" Vector__XXX
 SG_ MaxCurChargeCurLmt : 16|16@1+ (0.125,-4000) [0|4031.875] "A" Vector__XXX
 SG_ MaxCurDisCurLmt : 0|16@1+ (0.125,-4000) [-4000|0] "A" Vector__XXX

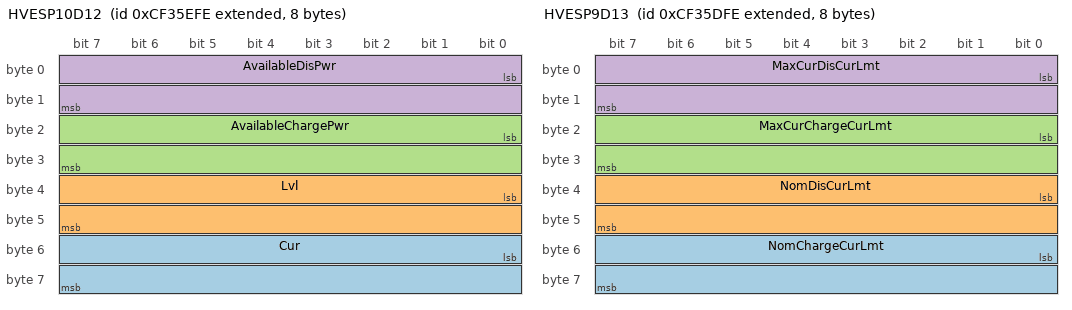
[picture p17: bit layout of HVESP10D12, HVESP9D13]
BO_ 2364759806 HVESP10D12: 8 Vector__XXX
 SG_ Cur : 48|16@1+ (0.125,-4000) [-4000|4031.875] "A" Vector__XXX
 SG_ Lvl : 32|16@1+ (0.125,0) [0|8031.875] "V" Vector__XXX
 SG_ AvailableChargePwr : 16|16@1+ (0.25,0) [0|16063.75] "kW" Vector__XXX
 SG_ AvailableDisPwr : 0|16@1+ (0.25,0) [0|16063.75] "kW" Vector__XXX

BO_ 2364759550 HVESP9D13: 8 Vector__XXX
 SG_ NomChargeCurLmt : 48|16@1+ (0.125,-4000) [0|4031.875] "A" Vector__XXX
 SG_ NomDisCurLmt : 32|16@1+ (0.125,-4000) [-4000|0] "A" Vector__XXX
 SG_ MaxCurChargeCurLmt : 16|16@1+ (0.125,-4000) [0|4031.875] "A" Vector__XXX
 SG_ MaxCurDisCurLmt : 0|16@1+ (0.125,-4000) [-4000|0] "A" Vector__XXX

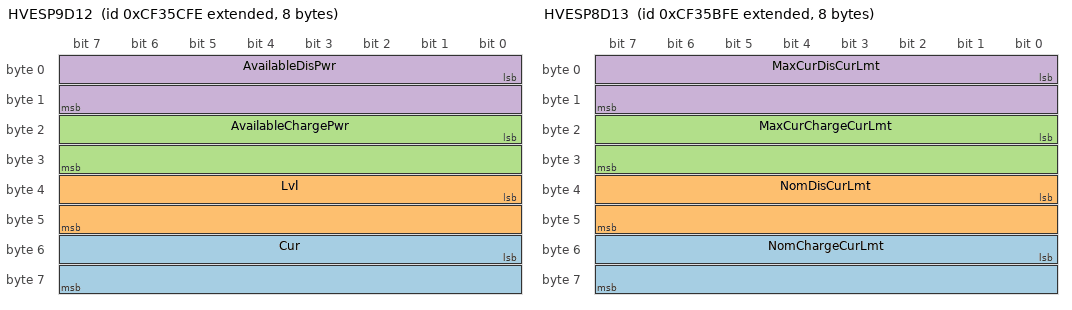
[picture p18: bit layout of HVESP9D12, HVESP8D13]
BO_ 2364759294 HVESP9D12: 8 Vector__XXX
 SG_ Cur : 48|16@1+ (0.125,-4000) [-4000|4031.875] "A" Vector__XXX
 SG_ Lvl : 32|16@1+ (0.125,0) [0|8031.875] "V" Vector__XXX
 SG_ AvailableChargePwr : 16|16@1+ (0.25,0) [0|16063.75] "kW" Vector__XXX
 SG_ AvailableDisPwr : 0|16@1+ (0.25,0) [0|16063.75] "kW" Vector__XXX

BO_ 2364759038 HVESP8D13: 8 Vector__XXX
 SG_ NomChargeCurLmt : 48|16@1+ (0.125,-4000) [0|4031.875] "A" Vector__XXX
 SG_ NomDisCurLmt : 32|16@1+ (0.125,-4000) [-4000|0] "A" Vector__XXX
 SG_ MaxCurChargeCurLmt : 16|16@1+ (0.125,-4000) [0|4031.875] "A" Vector__XXX
 SG_ MaxCurDisCurLmt : 0|16@1+ (0.125,-4000) [-4000|0] "A" Vector__XXX

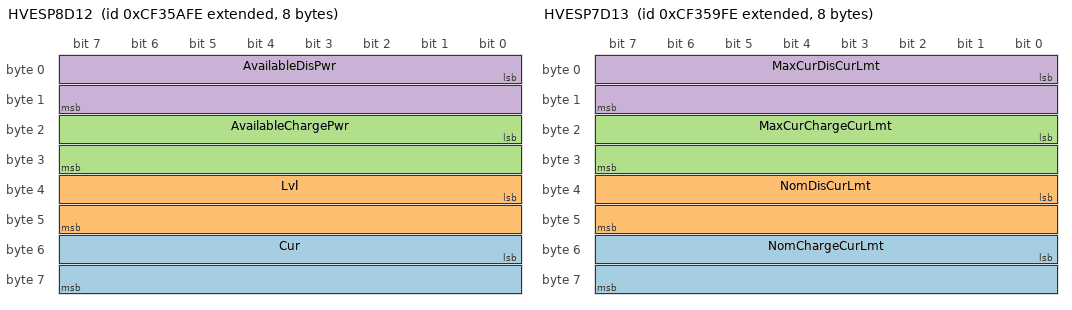
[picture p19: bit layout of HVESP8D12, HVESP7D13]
BO_ 2364758782 HVESP8D12: 8 Vector__XXX
 SG_ Cur : 48|16@1+ (0.125,-4000) [-4000|4031.875] "A" Vector__XXX
 SG_ Lvl : 32|16@1+ (0.125,0) [0|8031.875] "V" Vector__XXX
 SG_ AvailableChargePwr : 16|16@1+ (0.25,0) [0|16063.75] "kW" Vector__XXX
 SG_ AvailableDisPwr : 0|16@1+ (0.25,0) [0|16063.75] "kW" Vector__XXX

BO_ 2364758526 HVESP7D13: 8 Vector__XXX
 SG_ NomChargeCurLmt : 48|16@1+ (0.125,-4000) [0|4031.875] "A" Vector__XXX
 SG_ NomDisCurLmt : 32|16@1+ (0.125,-4000) [-4000|0] "A" Vector__XXX
 SG_ MaxCurChargeCurLmt : 16|16@1+ (0.125,-4000) [0|4031.875] "A" Vector__XXX
 SG_ MaxCurDisCurLmt : 0|16@1+ (0.125,-4000) [-4000|0] "A" Vector__XXX

CM_ BO_ 2365205758 "High Voltage Energy Storage Pack 6 Internal Status 1
Internal status data set 1 for High Voltage Energy Storage Pack 6.
The purpose of this PG is to assist in High Voltage Energy Storage Packs that require additional measurement and contactor ...";
CM_ SG_ 2365205758 HVInternalContactor8St22489 "Position of the High Voltage Energy Storage Pack 6 Internal 8 positive side bus contactor.
Refer to PGN description for usage of this SPN

00b = Contactor Open
01b = Contactor Closed
10b = Error
11b = Not Available";
CM_ SG_ 2365205758 HVInternalContactor7St22488 "Position of the High Voltage Energy Storage Pack 6 Internal 7 positive side bus contactor.
Refer to PGN description for usage of this SPN

00b = Contactor Open
01b = Contactor Closed
10b = Error
11b = Not Available";
CM_ SG_ 2365205758 HVInternalContactor6St22487 "Position of the High Voltage Energy Storage Pack 6 Internal 6 positive side bus contactor.
Refer to PGN description for usage of this SPN

00b = Contactor Open
01b = Contactor Closed
10b = Error
11b = Not Available";
CM_ SG_ 2365205758 HVInternalContactor5St22486 "Position of the High Voltage Energy Storage Pack 6 Internal 5 positive side bus contactor.
Refer to PGN description for usage of this SPN

00b = Contactor Open
01b = Contactor Closed
10b = Error
11b = Not Available";
CM_ SG_ 2365205758 HVInternalContactor4St22485 "Position of the High Voltage Energy Storage Pack 6 Internal 4 positive side bus contactor.
Refer to PGN description for usage of this SPN

00b = Contactor Open
01b = Contactor Closed
10b = Error
11b = Not Available";
CM_ SG_ 2365205758 HVInternalContactor3St22484 "Position of the High Voltage Energy Storage Pack 6 Internal 3 positive side bus contactor.
Refer to PGN description for usage of this SPN

00b = Contactor Open
01b = Contactor Closed
10b = Error
11b = Not Available";
CM_ SG_ 2365205758 HVInternalContactor2St22483 "Position of the High Voltage Energy Storage Pack 6 Internal 2 positive side bus contactor.
Refer to PGN description for usage of this SPN

00b = Contactor Open
01b = Contactor Closed
10b = Error
11b = Not Available";
CM_ SG_ 2365205758 HVInternalContactor1St22482 "Position of the High Voltage Energy Storage Pack 6 Internal 1 positive side bus contactor.
Refer to PGN description for usage of this SPN

00b = Contactor Open
01b = Contactor Closed
10b = Error
11b = Not Available";
CM_ SG_ 2365205758 HVInternalContactor8St "Position of the High Voltage Energy Storage  Pack 6 Internal 8 negative side bus contactor. 
Refer to PGN description for usage of this SPN

00b = Contactor Open
01b = Contactor Closed
10b = Error
11b = Not Available";
CM_ SG_ 2365205758 HVInternalContactor7St "Position of the High Voltage Energy Storage  Pack 6 Internal 7 negative side bus contactor. 
Refer to PGN description for usage of this SPN

00b = Contactor Open
01b = Contactor Closed
10b = Error
11b = Not Available";
CM_ SG_ 2365205758 HVInternalContactor6St "Position of the High Voltage Energy Storage  Pack 6 Internal 6 negative side bus contactor. 
Refer to PGN description for usage of this SPN

00b = Contactor Open
01b = Contactor Closed
10b = Error
11b = Not Available";
CM_ SG_ 2365205758 HVInternalContactor5St "Position of the High Voltage Energy Storage  Pack 6 Internal 5 negative side bus contactor. 
Refer to PGN description for usage of this SPN

00b = Contactor Open
01b = Contactor Closed
10b = Error
11b = Not Available";
CM_ SG_ 2365205758 HVInternalContactor4St "Position of the High Voltage Energy Storage  Pack 6 Internal 4 negative side bus contactor. 
Refer to PGN description for usage of this SPN

00b = Contactor Open
01b = Contactor Closed
10b = Error
11b = Not Available";
CM_ SG_ 2365205758 HVInternalContactor3St "Position of the High Voltage Energy Storage  Pack 6 Internal 3 negative side bus contactor. 
Refer to PGN description for usage of this SPN

00b = Contactor Open
01b = Contactor Closed
10b = Error
11b = Not Available";
CM_ SG_ 2365205758 HVInternalContactor2St "Position of the High Voltage Energy Storage  Pack 6 Internal 2 negative side bus contactor. 
Refer to PGN description for usage of this SPN

00b = Contactor Open
01b = Contactor Closed
10b = Error
11b = Not Available";
CM_ SG_ 2365205758 HVInternalContactor1St "Position of the High Voltage Energy Storage  Pack 6 Internal 1 negative side bus contactor. 
Refer to PGN description for usage of this SPN

00b = Contactor Open
01b = Contactor Closed
10b = Error
11b = Not Available";
CM_ BO_ 2365205502 "High Voltage Energy Storage Pack 5 Internal Status 1
Internal status data set 1 for High Voltage Energy Storage Pack 5.
The purpose of this PG is to assist in High Voltage Energy Storage Packs that require additional measurement and contactor ...";
CM_ SG_ 2365205502 HVInternalContactor8St22467 "Position of the High Voltage Energy Storage Pack 5 Internal 8 positive side bus contactor.
Refer to PGN description for usage of this SPN

00b = Contactor Open
01b = Contactor Closed
10b = Error
11b = Not Available";
CM_ SG_ 2365205502 HVInternalContactor7St22466 "Position of the High Voltage Energy Storage Pack 5 Internal 7 positive side bus contactor.
Refer to PGN description for usage of this SPN

00b = Contactor Open
01b = Contactor Closed
10b = Error
11b = Not Available";
CM_ SG_ 2365205502 HVInternalContactor6St22465 "Position of the High Voltage Energy Storage Pack 5 Internal 6 positive side bus contactor.
Refer to PGN description for usage of this SPN

00b = Contactor Open
01b = Contactor Closed
10b = Error
11b = Not Available";
CM_ SG_ 2365205502 HVInternalContactor5St22464 "Position of the High Voltage Energy Storage Pack 5 Internal 5 positive side bus contactor.
Refer to PGN description for usage of this SPN

00b = Contactor Open
01b = Contactor Closed
10b = Error
11b = Not Available";
CM_ SG_ 2365205502 HVInternalContactor4St22463 "Position of the High Voltage Energy Storage Pack 5 Internal 4 positive side bus contactor.
Refer to PGN description for usage of this SPN

00b = Contactor Open
01b = Contactor Closed
10b = Error
11b = Not Available";
CM_ SG_ 2365205502 HVInternalContactor3St22462 "Position of the High Voltage Energy Storage Pack 5 Internal 3 positive side bus contactor.
Refer to PGN description for usage of this SPN

00b = Contactor Open
01b = Contactor Closed
10b = Error
11b = Not Available";
CM_ SG_ 2365205502 HVInternalContactor2St22461 "Position of the High Voltage Energy Storage Pack 5 Internal 2 positive side bus contactor.
Refer to PGN description for usage of this SPN

00b = Contactor Open
01b = Contactor Closed
10b = Error
11b = Not Available";
CM_ SG_ 2365205502 HVInternalContactor1St22460 "Position of the High Voltage Energy Storage Pack 5 Internal 1 positive side bus contactor.
Refer to PGN description for usage of this SPN

00b = Contactor Open
01b = Contactor Closed
10b = Error
11b = Not Available";
CM_ SG_ 2365205502 HVInternalContactor8St "Position of the High Voltage Energy Storage  Pack 5 Internal 8 negative side bus contactor. 
Refer to PGN description for usage of this SPN

00b = Contactor Open
01b = Contactor Closed
10b = Error
11b = Not Available";
CM_ SG_ 2365205502 HVInternalContactor7St "Position of the High Voltage Energy Storage  Pack 5 Internal 7 negative side bus contactor. 
Refer to PGN description for usage of this SPN

00b = Contactor Open
01b = Contactor Closed
10b = Error
11b = Not Available";
CM_ SG_ 2365205502 HVInternalContactor6St "Position of the High Voltage Energy Storage  Pack 5 Internal 6 negative side bus contactor. 
Refer to PGN description for usage of this SPN

00b = Contactor Open
01b = Contactor Closed
10b = Error
11b = Not Available";
CM_ SG_ 2365205502 HVInternalContactor5St "Position of the High Voltage Energy Storage  Pack 5 Internal 5 negative side bus contactor. 
Refer to PGN description for usage of this SPN

00b = Contactor Open
01b = Contactor Closed
10b = Error
11b = Not Available";
CM_ SG_ 2365205502 HVInternalContactor4St "Position of the High Voltage Energy Storage  Pack 5 Internal 4 negative side bus contactor. 
Refer to PGN description for usage of this SPN

00b = Contactor Open
01b = Contactor Closed
10b = Error
11b = Not Available";
CM_ SG_ 2365205502 HVInternalContactor3St "Position of the High Voltage Energy Storage  Pack 5 Internal 3 negative side bus contactor. 
Refer to PGN description for usage of this SPN

00b = Contactor Open
01b = Contactor Closed
10b = Error
11b = Not Available";
CM_ SG_ 2365205502 HVInternalContactor2St "Position of the High Voltage Energy Storage  Pack 5 Internal 2 negative side bus contactor. 
Refer to PGN description for usage of this SPN

00b = Contactor Open
01b = Contactor Closed
10b = Error
11b = Not Available";
CM_ SG_ 2365205502 HVInternalContactor1St "Position of the High Voltage Energy Storage  Pack 5 Internal 1 negative side bus contactor. 
Refer to PGN description for usage of this SPN

00b = Contactor Open
01b = Contactor Closed
10b = Error
11b = Not Available";
CM_ BO_ 2365205246 "High Voltage Energy Storage Pack 4 Internal Status 1
Internal status data set 1 for High Voltage Energy Storage Pack 4.
The purpose of this PG is to assist in High Voltage Energy Storage Packs that require additional measurement and contactor ...";
CM_ SG_ 2365205246 HVInternalContactor8St22445 "Position of the High Voltage Energy Storage Pack 4 Internal 8 positive side bus contactor.
Refer to PGN description for usage of this SPN

00b = Contactor Open
01b = Contactor Closed
10b = Error
11b = Not Available";
CM_ SG_ 2365205246 HVInternalContactor7St22444 "Position of the High Voltage Energy Storage Pack 4 Internal 7 positive side bus contactor.
Refer to PGN description for usage of this SPN

00b = Contactor Open
01b = Contactor Closed
10b = Error
11b = Not Available";
CM_ SG_ 2365205246 HVInternalContactor6St22443 "Position of the High Voltage Energy Storage Pack 4 Internal 6 positive side bus contactor.
Refer to PGN description for usage of this SPN

00b = Contactor Open
01b = Contactor Closed
10b = Error
11b = Not Available";
CM_ SG_ 2365205246 HVInternalContactor5St22442 "Position of the High Voltage Energy Storage Pack 4 Internal 5 positive side bus contactor.
Refer to PGN description for usage of this SPN

00b = Contactor Open
01b = Contactor Closed
10b = Error
11b = Not Available";
CM_ SG_ 2365205246 HVInternalContactor4St22441 "Position of the High Voltage Energy Storage Pack 4 Internal 4 positive side bus contactor.
Refer to PGN description for usage of this SPN

00b = Contactor Open
01b = Contactor Closed
10b = Error
11b = Not Available";
CM_ SG_ 2365205246 HVInternalContactor3St22440 "Position of the High Voltage Energy Storage Pack 4 Internal 3 positive side bus contactor.
Refer to PGN description for usage of this SPN

00b = Contactor Open
01b = Contactor Closed
10b = Error
11b = Not Available";
CM_ SG_ 2365205246 HVInternalContactor2St22439 "Position of the High Voltage Energy Storage Pack 4 Internal 2 positive side bus contactor.
Refer to PGN description for usage of this SPN

00b = Contactor Open
01b = Contactor Closed
10b = Error
11b = Not Available";
CM_ SG_ 2365205246 HVInternalContactor1St22438 "Position of the High Voltage Energy Storage Pack 4 Internal 1 positive side bus contactor.
Refer to PGN description for usage of this SPN

00b = Contactor Open
01b = Contactor Closed
10b = Error
11b = Not Available";
CM_ SG_ 2365205246 HVInternalContactor8St "Position of the High Voltage Energy Storage  Pack 4 Internal 8 negative side bus contactor. 
Refer to PGN description for usage of this SPN

00b = Contactor Open
01b = Contactor Closed
10b = Error
11b = Not Available";
CM_ SG_ 2365205246 HVInternalContactor7St "Position of the High Voltage Energy Storage  Pack 4 Internal 7 negative side bus contactor. 
Refer to PGN description for usage of this SPN

00b = Contactor Open
01b = Contactor Closed
10b = Error
11b = Not Available";
CM_ SG_ 2365205246 HVInternalContactor6St "Position of the High Voltage Energy Storage  Pack 4 Internal 6 negative side bus contactor. 
Refer to PGN description for usage of this SPN

00b = Contactor Open
01b = Contactor Closed
10b = Error
11b = Not Available";
CM_ SG_ 2365205246 HVInternalContactor5St "Position of the High Voltage Energy Storage  Pack 4 Internal 5 negative side bus contactor. 
Refer to PGN description for usage of this SPN

00b = Contactor Open
01b = Contactor Closed
10b = Error
11b = Not Available";
CM_ SG_ 2365205246 HVInternalContactor4St "Position of the High Voltage Energy Storage  Pack 4 Internal 4 negative side bus contactor. 
Refer to PGN description for usage of this SPN

00b = Contactor Open
01b = Contactor Closed
10b = Error
11b = Not Available";
CM_ SG_ 2365205246 HVInternalContactor3St "Position of the High Voltage Energy Storage  Pack 4 Internal 3 negative side bus contactor. 
Refer to PGN description for usage of this SPN

00b = Contactor Open
01b = Contactor Closed
10b = Error
11b = Not Available";
CM_ SG_ 2365205246 HVInternalContactor2St "Position of the High Voltage Energy Storage  Pack 4 Internal 2 negative side bus contactor. 
Refer to PGN description for usage of this SPN

00b = Contactor Open
01b = Contactor Closed
10b = Error
11b = Not Available";
CM_ SG_ 2365205246 HVInternalContactor1St "Position of the High Voltage Energy Storage  Pack 4 Internal 1 negative side bus contactor. 
Refer to PGN description for usage of this SPN

00b = Contactor Open
01b = Contactor Closed
10b = Error
11b = Not Available";
CM_ BO_ 2365204990 "High Voltage Energy Storage Pack 3 Internal Status 1
Internal status data set 1 for High Voltage Energy Storage Pack 3.
The purpose of this PG is to assist in High Voltage Energy Storage Packs that require additional measurement and contactor ...";
CM_ SG_ 2365204990 HVInternalContactor8St22423 "Position of the High Voltage Energy Storage Pack 3 Internal 8 positive side bus contactor.
Refer to PGN description for usage of this SPN

00b = Contactor Open
01b = Contactor Closed
10b = Error
11b = Not Available";
CM_ SG_ 2365204990 HVInternalContactor7St22422 "Position of the High Voltage Energy Storage Pack 3 Internal 7 positive side bus contactor.
Refer to PGN description for usage of this SPN

00b = Contactor Open
01b = Contactor Closed
10b = Error
11b = Not Available";
CM_ SG_ 2365204990 HVInternalContactor6St22421 "Position of the High Voltage Energy Storage Pack 3 Internal 6 positive side bus contactor.
Refer to PGN description for usage of this SPN

00b = Contactor Open
01b = Contactor Closed
10b = Error
11b = Not Available";
CM_ SG_ 2365204990 HVInternalContactor5St22420 "Position of the High Voltage Energy Storage Pack 3 Internal 5 positive side bus contactor.
Refer to PGN description for usage of this SPN

00b = Contactor Open
01b = Contactor Closed
10b = Error
11b = Not Available";
CM_ SG_ 2365204990 HVInternalContactor4St22419 "Position of the High Voltage Energy Storage Pack 3 Internal 4 positive side bus contactor.
Refer to PGN description for usage of this SPN

00b = Contactor Open
01b = Contactor Closed
10b = Error
11b = Not Available";
CM_ SG_ 2365204990 HVInternalContactor3St22418 "Position of the High Voltage Energy Storage Pack 3 Internal 3 positive side bus contactor.
Refer to PGN description for usage of this SPN

00b = Contactor Open
01b = Contactor Closed
10b = Error
11b = Not Available";
CM_ SG_ 2365204990 HVInternalContactor2St22417 "Position of the High Voltage Energy Storage Pack 3 Internal 2 positive side bus contactor.
Refer to PGN description for usage of this SPN

00b = Contactor Open
01b = Contactor Closed
10b = Error
11b = Not Available";
CM_ SG_ 2365204990 HVInternalContactor1St22416 "Position of the High Voltage Energy Storage Pack 3 Internal 1 positive side bus contactor.
Refer to PGN description for usage of this SPN

00b = Contactor Open
01b = Contactor Closed
10b = Error
11b = Not Available";
CM_ SG_ 2365204990 HVInternalContactor8St "Position of the High Voltage Energy Storage  Pack 3 Internal 8 negative side bus contactor. 
Refer to PGN description for usage of this SPN

00b = Contactor Open
01b = Contactor Closed
10b = Error
11b = Not Available";
CM_ SG_ 2365204990 HVInternalContactor7St "Position of the High Voltage Energy Storage  Pack 3 Internal 7 negative side bus contactor. 
Refer to PGN description for usage of this SPN

00b = Contactor Open
01b = Contactor Closed
10b = Error
11b = Not Available";
CM_ SG_ 2365204990 HVInternalContactor6St "Position of the High Voltage Energy Storage  Pack 3 Internal 6 negative side bus contactor. 
Refer to PGN description for usage of this SPN

00b = Contactor Open
01b = Contactor Closed
10b = Error
11b = Not Available";
CM_ SG_ 2365204990 HVInternalContactor5St "Position of the High Voltage Energy Storage  Pack 3 Internal 5 negative side bus contactor. 
Refer to PGN description for usage of this SPN

00b = Contactor Open
01b = Contactor Closed
10b = Error
11b = Not Available";
CM_ SG_ 2365204990 HVInternalContactor4St "Position of the High Voltage Energy Storage  Pack 3 Internal 4 negative side bus contactor. 
Refer to PGN description for usage of this SPN

00b = Contactor Open
01b = Contactor Closed
10b = Error
11b = Not Available";
CM_ SG_ 2365204990 HVInternalContactor3St "Position of the High Voltage Energy Storage  Pack 3 Internal 3 negative side bus contactor. 
Refer to PGN description for usage of this SPN

00b = Contactor Open
01b = Contactor Closed
10b = Error
11b = Not Available";
CM_ SG_ 2365204990 HVInternalContactor2St "Position of the High Voltage Energy Storage  Pack 3 Internal 2 negative side bus contactor. 
Refer to PGN description for usage of this SPN

00b = Contactor Open
01b = Contactor Closed
10b = Error
11b = Not Available";
CM_ SG_ 2365204990 HVInternalContactor1St "Position of the High Voltage Energy Storage  Pack 3 Internal 1 negative side bus contactor. 
Refer to PGN description for usage of this SPN

00b = Contactor Open
01b = Contactor Closed
10b = Error
11b = Not Available";
CM_ BO_ 2365204734 "High Voltage Energy Storage Pack 2 Internal Status 1
Internal status data set 1 for High Voltage Energy Storage Pack 2.
The purpose of this PG is to assist in High Voltage Energy Storage Packs that require additional measurement and contactor ...";
CM_ SG_ 2365204734 HVInternalContactor8St22401 "Position of the High Voltage Energy Storage Pack 2 Internal 8 positive side bus contactor.
Refer to PGN description for usage of this SPN

00b = Contactor Open
01b = Contactor Closed
10b = Error
11b = Not Available";
CM_ SG_ 2365204734 HVInternalContactor7St22400 "Position of the High Voltage Energy Storage Pack 2 Internal 7 positive side bus contactor.
Refer to PGN description for usage of this SPN

00b = Contactor Open
01b = Contactor Closed
10b = Error
11b = Not Available";
CM_ SG_ 2365204734 HVInternalContactor6St22399 "Position of the High Voltage Energy Storage Pack 2 Internal 6 positive side bus contactor.
Refer to PGN description for usage of this SPN

00b = Contactor Open
01b = Contactor Closed
10b = Error
11b = Not Available";
CM_ SG_ 2365204734 HVInternalContactor5St22398 "Position of the High Voltage Energy Storage Pack 2 Internal 5 positive side bus contactor.
Refer to PGN description for usage of this SPN

00b = Contactor Open
01b = Contactor Closed
10b = Error
11b = Not Available";
CM_ SG_ 2365204734 HVInternalContactor4St22397 "Position of the High Voltage Energy Storage Pack 2 Internal 4 positive side bus contactor.
Refer to PGN description for usage of this SPN

00b = Contactor Open
01b = Contactor Closed
10b = Error
11b = Not Available";
CM_ SG_ 2365204734 HVInternalContactor3St22396 "Position of the High Voltage Energy Storage Pack 2 Internal 3 positive side bus contactor.
Refer to PGN description for usage of this SPN

00b = Contactor Open
01b = Contactor Closed
10b = Error
11b = Not Available";
CM_ SG_ 2365204734 HVInternalContactor2St22395 "Position of the High Voltage Energy Storage Pack 2 Internal 2 positive side bus contactor.
Refer to PGN description for usage of this SPN

00b = Contactor Open
01b = Contactor Closed
10b = Error
11b = Not Available";
CM_ SG_ 2365204734 HVInternalContactor1St22394 "Position of the High Voltage Energy Storage Pack 2 Internal 1 positive side bus contactor.
Refer to PGN description for usage of this SPN

00b = Contactor Open
01b = Contactor Closed
10b = Error
11b = Not Available";
CM_ SG_ 2365204734 HVInternalContactor8St "Position of the High Voltage Energy Storage  Pack 2 Internal 8 negative side bus contactor. 
Refer to PGN description for usage of this SPN

00b = Contactor Open
01b = Contactor Closed
10b = Error
11b = Not Available";
CM_ SG_ 2365204734 HVInternalContactor7St "Position of the High Voltage Energy Storage  Pack 2 Internal 7 negative side bus contactor. 
Refer to PGN description for usage of this SPN

00b = Contactor Open
01b = Contactor Closed
10b = Error
11b = Not Available";
CM_ SG_ 2365204734 HVInternalContactor6St "Position of the High Voltage Energy Storage  Pack 2 Internal 6 negative side bus contactor. 
Refer to PGN description for usage of this SPN

00b = Contactor Open
01b = Contactor Closed
10b = Error
11b = Not Available";
CM_ SG_ 2365204734 HVInternalContactor5St "Position of the High Voltage Energy Storage  Pack 2 Internal 5 negative side bus contactor. 
Refer to PGN description for usage of this SPN

00b = Contactor Open
01b = Contactor Closed
10b = Error
11b = Not Available";
CM_ SG_ 2365204734 HVInternalContactor4St "Position of the High Voltage Energy Storage  Pack 2 Internal 4 negative side bus contactor. 
Refer to PGN description for usage of this SPN

00b = Contactor Open
01b = Contactor Closed
10b = Error
11b = Not Available";
CM_ SG_ 2365204734 HVInternalContactor3St "Position of the High Voltage Energy Storage  Pack 2 Internal 3 negative side bus contactor. 
Refer to PGN description for usage of this SPN

00b = Contactor Open
01b = Contactor Closed
10b = Error
11b = Not Available";
CM_ SG_ 2365204734 HVInternalContactor2St "Position of the High Voltage Energy Storage  Pack 2 Internal 2 negative side bus contactor. 
Refer to PGN description for usage of this SPN

00b = Contactor Open
01b = Contactor Closed
10b = Error
11b = Not Available";
CM_ SG_ 2365204734 HVInternalContactor1St "Position of the High Voltage Energy Storage  Pack 2 Internal 1 negative side bus contactor. 
Refer to PGN description for usage of this SPN

00b = Contactor Open
01b = Contactor Closed
10b = Error
11b = Not Available";
CM_ BO_ 2365204478 "High Voltage Energy Storage Pack 1 Internal Status 1
Internal status data set 1 for High Voltage Energy Storage Pack 1.
The purpose of this PG is to assist in High Voltage Energy Storage Packs that require additional measurement and contactor ...";
CM_ SG_ 2365204478 HVInternalContactor8St22379 "Position of the High Voltage Energy Storage Pack 1 Internal 8 positive side bus contactor.
Refer to PGN description for usage of this SPN

00b = Contactor Open
01b = Contactor Closed
10b = Error
11b = Not Available";
CM_ SG_ 2365204478 HVInternalContactor7St22378 "Position of the High Voltage Energy Storage Pack 1 Internal 7 positive side bus contactor.
Refer to PGN description for usage of this SPN

00b = Contactor Open
01b = Contactor Closed
10b = Error
11b = Not Available";
CM_ SG_ 2365204478 HVInternalContactor6St22377 "Position of the High Voltage Energy Storage Pack 1 Internal 6 positive side bus contactor.
Refer to PGN description for usage of this SPN

00b = Contactor Open
01b = Contactor Closed
10b = Error
11b = Not Available";
CM_ SG_ 2365204478 HVInternalContactor5St22376 "Position of the High Voltage Energy Storage Pack 1 Internal 5 positive side bus contactor.
Refer to PGN description for usage of this SPN

00b = Contactor Open
01b = Contactor Closed
10b = Error
11b = Not Available";
CM_ SG_ 2365204478 HVInternalContactor4St22375 "Position of the High Voltage Energy Storage Pack 1 Internal 4 positive side bus contactor.
Refer to PGN description for usage of this SPN

00b = Contactor Open
01b = Contactor Closed
10b = Error
11b = Not Available";
CM_ SG_ 2365204478 HVInternalContactor3St22374 "Position of the High Voltage Energy Storage Pack 1 Internal 3 positive side bus contactor.
Refer to PGN description for usage of this SPN

00b = Contactor Open
01b = Contactor Closed
10b = Error
11b = Not Available";
CM_ SG_ 2365204478 HVInternalContactor2St22373 "Position of the High Voltage Energy Storage Pack 1 Internal 2 positive side bus contactor.
Refer to PGN description for usage of this SPN

00b = Contactor Open
01b = Contactor Closed
10b = Error
11b = Not Available";
CM_ SG_ 2365204478 HVInternalContactor1St22372 "Position of the High Voltage Energy Storage Pack 1 Internal 1 positive side bus contactor.
Refer to PGN description for usage of this SPN

00b = Contactor Open
01b = Contactor Closed
10b = Error
11b = Not Available";
CM_ SG_ 2365204478 HVInternalContactor8St "Position of the High Voltage Energy Storage  Pack 1 Internal 8 negative side bus contactor. 
Refer to PGN description for usage of this SPN

00b = Contactor Open
01b = Contactor Closed
10b = Error
11b = Not Available";
CM_ SG_ 2365204478 HVInternalContactor7St "Position of the High Voltage Energy Storage  Pack 1 Internal 7 negative side bus contactor. 
Refer to PGN description for usage of this SPN

00b = Contactor Open
01b = Contactor Closed
10b = Error
11b = Not Available";
CM_ SG_ 2365204478 HVInternalContactor6St "Position of the High Voltage Energy Storage  Pack 1 Internal 6 negative side bus contactor. 
Refer to PGN description for usage of this SPN

00b = Contactor Open
01b = Contactor Closed
10b = Error
11b = Not Available";
CM_ SG_ 2365204478 HVInternalContactor5St "Position of the High Voltage Energy Storage  Pack 1 Internal 5 negative side bus contactor. 
Refer to PGN description for usage of this SPN

00b = Contactor Open
01b = Contactor Closed
10b = Error
11b = Not Available";
CM_ SG_ 2365204478 HVInternalContactor4St "Position of the High Voltage Energy Storage  Pack 1 Internal 4 negative side bus contactor. 
Refer to PGN description for usage of this SPN

00b = Contactor Open
01b = Contactor Closed
10b = Error
11b = Not Available";
CM_ SG_ 2365204478 HVInternalContactor3St "Position of the High Voltage Energy Storage  Pack 1 Internal 3 negative side bus contactor. 
Refer to PGN description for usage of this SPN

00b = Contactor Open
01b = Contactor Closed
10b = Error
11b = Not Available";
CM_ SG_ 2365204478 HVInternalContactor2St "Position of the High Voltage Energy Storage  Pack 1 Internal 2 negative side bus contactor. 
Refer to PGN description for usage of this SPN

00b = Contactor Open
01b = Contactor Closed
10b = Error
11b = Not Available";
CM_ SG_ 2365204478 HVInternalContactor1St "Position of the High Voltage Energy Storage  Pack 1 Internal 1 negative side bus contactor. 
Refer to PGN description for usage of this SPN

00b = Contactor Open
01b = Contactor Closed
10b = Error
11b = Not Available";
CM_ BO_ 2365204222 "High Voltage Energy Storage System Data 14
Data set 14 (electrical data) for High Voltage Energy Storage System (or Pack 1 in systems with only one pack).";
CM_ SG_ 2365204222 BusV "The voltage level of the high voltage bus, as measured by the High Voltage Energy Storage System (or Pack 1 in systems with only one pack) on the bus side (not the battery side) of its contactors.
This parameter provides HVES system level ...";
CM_ SG_ 2365204222 MaxCurChargeCurLmt "The maximum instantaneous current flow limit into the High Voltage Energy Storage System (or Pack 1 in systems with only one pack). This parameter is defined from the high voltage energy storage system's point of view and should reflect the ...";
CM_ SG_ 2365204222 MaxCurDisCurLmt "The maximum instantaneous current flow limit out of the High Voltage Energy Storage System (or Pack 1 in systems with only one pack). This parameter is defined from the high voltage energy storage system's point of view and should reflect the ...";
CM_ BO_ 2365203966 "High Voltage Energy Storage System Data 13
Data set 13 (electrical data) for High Voltage Energy Storage System (or Pack 1 in systems with only one pack).";
CM_ SG_ 2365203966 Cur "The current in or out of the High Voltage Energy Storage System (or Pack 1 in systems with only one pack). This parameter should be synchronized with SPN 22352 (HVESS Voltage Level (Extended Range)) such that a realized power value can be ...";
CM_ SG_ 2365203966 Lvl "The voltage level of the High Voltage Energy Storage System (or Pack 1 in systems with only one pack). This parameter should be synchronized with SPN 22351 (HVESS Current (Extended Range)) such that a realized power value can be calculated. If the ...";
CM_ SG_ 2365203966 AvailableChargePwr "The rate at which the High Voltage Energy Storage System (or Pack 1 in systems with only one
pack) can currently receive energy from a regenerative or recharging system.
This parameter provides HVES system level information. If there are multiple ...";
CM_ SG_ 2365203966 AvailableDisPwr "The rate at which the High Voltage Energy Storage System (or Pack 1 in systems with only one
pack) can currently provide energy for propulsion or other uses.
This parameter provides HVES system level information. If there are multiple packs in the ...";
CM_ BO_ 2365203710 "High Voltage Energy Storage System Data 12
Data set 12 (electrical data) for High Voltage Energy Storage System (or Pack 1 in systems with only one pack).";
CM_ SG_ 2365203710 HVBusNegPreChargeRelaySt "Position of the high-voltage bus contactor negative pre-charge relay. When this relay is closed, the High Voltage Energy Storage System (or Pack 1 in systems with only one pack) is bringing the high-voltage bus up to its operating level when the ...";
CM_ SG_ 2365203710 HVBusPosPreChargeRelaySt "Position of the high-voltage bus contactor positive pre-charge relay. When this relay is closed, the High Voltage Energy Storage System (or Pack 1 in systems with only one pack) is bringing the high-voltage bus up to its operating level when the ...";
CM_ SG_ 2365203710 PwrHoldRelaySt "Status of the relay for keep alive power in the HVESS independent of the enable input to the HVESS.  For example, this could allow continued device operation after the keyswitch has turned off.

00b = Off
01b = On
10b = Error
11b = Not Available";
CM_ SG_ 2365203710 ExposureInd "This signal indicates the condition and state of the HVESS high voltage exposure detection system (e.g. High Voltage Interlock Loop [HVIL], welded contactor etc.,). The high voltage exposure detection system is used to detect situations on a vehicle ...";
CM_ SG_ 2365203710 EstChargeTimeRem "The HVESS charge time remaining with the current battery state of charge and the average charging of the HVESS.";
CM_ SG_ 2365203710 EstDisTimeRem "The HVESS discharge time remaining with the current battery state of charge and the average usage of the HVESS.";
CM_ SG_ 2365203710 InCoolantPress "Gage pressure of coolant entering as it enters the High Voltage Energy Storage System.";
CM_ BO_ 2566530046 "Motor/Generator Location (obsolete, use PGN 64018)
This message captures the instances and locations of electric motors on the towing vehicle and associated trailer(s) in the vehicle system. The number of axles and Motor/Generator instances will ...";
CM_ SG_ 2566530046 TlrType "Describes the axle topology of a given trailer segment. These types of trailers are taken from ISO7641 and ISO13052. See Appendix D for additional information on trailer types
0000b = Not applicable; segment is not a trailer
0001b = Semi (e.g ...";
CM_ SG_ 2566530046 VehSegment "Conveys the vehicle segment where the given axle is located. The definition of the trailer (i.e. Trailer 1, Trailer 2,3,4,5) follows the ISO11992-2 specification (Section 6.3 Address Assignment) for the order of the trailer assigment.
0000b = ...";
CM_ SG_ 2566530046 Rotation "Direction of Motor/Generator (MG) rotation with respect to forward gear and forward vehicle direction. Positive and negative speeds directly correlate with the signs of the speed used to control, or as reported from, a Motor/Generator, e.g. MG1IC ...";
CM_ SG_ 2566530046 Id "Identifies the Motor/Generator instance assigned to a given axle and location. The instance number correlates to the Motor/Generator (MG) messages being used, e.g. MG1IC, MG2IC, MG3IC, MG4IC, MG5IC, MG6IC, etc.
0000b = No Motor/Generator
0001b = ...";
CM_ SG_ 2566530046 SPN22255 "For the given SPN 22628 (Axle Instance), this is the location of a given Motor/Generator (MG) instance on that axle.
0000b = Not Driven
0001b = Left Side - MG located on the left side of the axle when facing forward in the driver’s seat. Includes ...";
CM_ SG_ 2566530046 AxleInstance "Number of the axle instances being reported on from this controller application for this vehicle segment. Axle 1 is at the front of the vehicle segment and the count will increase towards the rear. If the parameter is No Axle this indicates that the ...";
CM_ SG_ 2566530046 NumOfAxleInstancesBeingReported "The number of axles being reported on by this controller.";
CM_ BO_ 2566529790 "Sensor Supply Voltage
Voltage supplies for sensors";
CM_ SG_ 2566529790 EngInAirSnsr "Indicates the voltage being supplied to the intake air sensor module on the engine.";
CM_ SG_ 2566529790 DPFPressSnsr "Indicates the voltage being supplied to the diesel particulate filter pressure sensor module.";
CM_ SG_ 2566529790 EngOilSnsr "Indicates the voltage being supplied to the oil sensor module on the engine.";
CM_ SG_ 2566529790 EngFilteredFuelSnsr "Indicates the voltage being supplied to fuel sensor module on the engine after the pressure side fuel filter.";
CM_ SG_ 2566529790 EngEGRInPressSnsr "Indicates the voltage being supplied to exhaust gas recirculation intake pressure sensor module on the engine.";
CM_ SG_ 2566529790 EngFuelDelPressSnsr "Indicates the voltage being supplied to fuel delivery pressure sensor module on the engine";
CM_ SG_ 2566529790 EngCrankcasePressSnsr "Indicates the voltage being supplied to the crankcase pressure sensor module on the engine.";
CM_ BO_ 2566529534 "EV Multi-Connection Charging In Progress
Optional information on the present charge cycle that may be sent to the EVSE from the EV for display purposes.
The extended Id in this PDU2 PG can be used to indicate that the data contained is only ...";
CM_ SG_ 2566529534 DepTime "Time remaining until the vehicle's expected departure.

See ISO 15118-2/Figure 92 Ref. V2G2-371";
CM_ SG_ 2566529534 FullChargeTimeRem "Remaining time to complete full charging for this connection.

See SAE J2847-2 201504 Sect 4.2.77";
CM_ SG_ 2566529534 BulkChargeTimeRem "Remaining time to complete bulk charging for this connection.

See SAE J2847-2 201504 Sect 4.2.76";
CM_ SG_ 2566529534 FullChargingComplete "For EVSE display purposes, this parameter indicates if full charging is complete for this connection.

00b = Full charging not complete
01b = Full charging complete
10b = Error
11b = Not available

See SAE J2847-2 201504 Sect 4.2.5";
CM_ SG_ 2566529534 BulkChargingComplete "Optional, for EVSE display purposes, this parameter indicates if bulk charging is complete for this connection.

00b = Bulk charging not complete
01b = Bulk charging complete
10b = Error
11b = Not available

See SAE J2847-2 201504 Sect 4.2.2";
CM_ SG_ 2566529534 ExID "Single byte extended ID for this PG.
It is used to identify the contents of this PG as being specific to a particular EVCC /  EVSE connection.
Its numeric value shall be the same as the intended EVCC's J1939 bus address.
If a value of 255 is ...";
CM_ BO_ 2566529278 "EV Multi-Connection DC Charging Limits 2
Optional data used by the EVCC when initializing a new connection with an EVSE that supports DC charging.
The extended Id in this PDU2 PG can be used to indicate that the data contained is only applicable ...";
CM_ SG_ 2566529278 EnergyReq "Amount of energy the EV requests from the EVSE on this connection.

See SAE J2847-2 201504 Sect 4.2.25";
CM_ SG_ 2566529278 EnergyCapacity "Maximum energy capacity supported by the EV for this connection.

See SAE J2847-2 201504 Sect 4.2.24";
CM_ SG_ 2566529278 FullStOfCharge "State of charge value, as indicated by SPN 22710 (EV Multi-Connection State of Charge), where charging is considered to be complete. (Typically 100%)

See SAE J2847-2 201504 Sect. 4.2.57";
CM_ SG_ 2566529278 BulkStOfCharge "State of charge value, as indicated by SPN 22710 (EV Multi-Connection State of Charge), where \"bulk\" charging is considered to be complete. (For example 80%)

See SAE J2847-2 201504 Sect. 4.2.3";
CM_ SG_ 2566529278 ExID "Single byte extended ID for this PG.
It is used to identify the contents of this PG as being specific to a particular EVCC /  EVSE connection.
Its numeric value shall be the same as the intended EVCC's J1939 bus address.
If a value of 255 is ...";
CM_ BO_ 2633637886 "Aftertreatment System Information 6
The state of the aftertreatment system.";
CM_ SG_ 2633637886 TwoDEFDosingMode "The present operating state of the DEF doser for aftertreatment 2 (exhaust bank 2) as described by the appropriate regulatory body with the manufacturer.
00h = Off, not dosing
01h - FAh = Manufacturer Defined, assign from 1 up or from 250 down.
 ...";
CM_ BO_ 2365202174 "High Voltage Bus Contactor Status
Conveys the status of contactors that connect the main high-voltage bus to high-voltage device(s) or a sub-bus in an electric or hybrid vehicle.";
CM_ SG_ 2365202174 CRC "The CRC is defined as follows:
• Length: 8 bits
• Polynomial: x^8+x^5+x^3+x^2+x+1
• Initial Value: FFh
• Input Data Reflection: Not reflected
• Result Data Reflection: Not reflected
• XOR value: FFh
SAE makes no claim of the functional safety ...";
CM_ SG_ 2365202174 Counter "The message counter is used to detect situations where the transmitting ECU malfunction repeats the same frame all the time. The receiver of the information may use the counter parameter to detect this situation. The transmitting device will ...";
CM_ SG_ 2365202174 EmbeddedIntegritySupport "Indicates SPN 22788 (HVBCS CRC) and SPN 22787 (HVBCS Counter) are supported by the sender.
00b = HVBCS embedded CRC and Counter are supported by the sender
01b = HVBCS protection is supported using J1939-76 SHM
10b = Reserved
11b = HVBCS CRC and ...";
CM_ SG_ 2365202174 HVBusInterface8NegContactorSt "Negative contactor state for this High Voltage Bus (HV Bus) Interface instance.

00b = Contactor Open
01b = Contactor Closed
10b = Error
11b = Not Available";
CM_ SG_ 2365202174 HVBusInterface8PosContactorSt "Positive contactor state for this High Voltage Bus (HV Bus) Interface instance.

00b = Contactor Open
01b = Contactor Closed
10b = Error
11b = Not Available";
CM_ SG_ 2365202174 HVBusInterface7NegContactorSt "Negative contactor state for this High Voltage Bus (HV Bus) Interface instance.

00b = Contactor Open
01b = Contactor Closed
10b = Error
11b = Not Available";
CM_ SG_ 2365202174 HVBusInterface7PosContactorSt "Positive contactor state for this High Voltage Bus (HV Bus) Interface instance.

00b = Contactor Open
01b = Contactor Closed
10b = Error
11b = Not Available";
CM_ SG_ 2365202174 HVBusInterface6NegContactorSt "Negative contactor state for this High Voltage Bus (HV Bus) Interface instance.

00b = Contactor Open
01b = Contactor Closed
10b = Error
11b = Not Available";
CM_ SG_ 2365202174 HVBusInterface6PosContactorSt "Positive contactor state for this High Voltage Bus (HV Bus) Interface instance.

00b = Contactor Open
01b = Contactor Closed
10b = Error
11b = Not Available";
CM_ SG_ 2365202174 HVBusInterface5NegContactorSt "Negative contactor state for this High Voltage Bus (HV Bus) Interface instance.

00b = Contactor Open
01b = Contactor Closed
10b = Error
11b = Not Available";
CM_ SG_ 2365202174 HVBusInterface5PosContactorSt "Positive contactor state for this High Voltage Bus (HV Bus) Interface instance.

00b = Contactor Open
01b = Contactor Closed
10b = Error
11b = Not Available";
CM_ SG_ 2365202174 HVBusInterface4NegContactorSt "Negative contactor state for this High Voltage Bus (HV Bus) Interface instance.

00b = Contactor Open
01b = Contactor Closed
10b = Error
11b = Not Available";
CM_ SG_ 2365202174 HVBusInterface4PosContactorSt "Positive contactor state for this High Voltage Bus (HV Bus) Interface instance.

00b = Contactor Open
01b = Contactor Closed
10b = Error
11b = Not Available";
CM_ SG_ 2365202174 HVBusInterface3NegContactorSt "Negative contactor state for this High Voltage Bus (HV Bus) Interface instance.

00b = Contactor Open
01b = Contactor Closed
10b = Error
11b = Not Available";
CM_ SG_ 2365202174 HVBusInterface3PosContactorSt "Positive contactor state for this High Voltage Bus (HV Bus) Interface instance.

00b = Contactor Open
01b = Contactor Closed
10b = Error
11b = Not Available";
CM_ SG_ 2365202174 HVBusInterface2NegContactorSt "Negative contactor state for this High Voltage Bus (HV Bus) Interface instance.

00b = Contactor Open
01b = Contactor Closed
10b = Error
11b = Not Available";
CM_ SG_ 2365202174 HVBusInterface2PosContactorSt "Positive contactor state for this High Voltage Bus (HV Bus) Interface instance.

00b = Contactor Open
01b = Contactor Closed
10b = Error
11b = Not Available";
CM_ SG_ 2365202174 HVBusInterface1NegContactorSt "Negative contactor state for this High Voltage Bus (HV Bus) Interface instance.

00b = Contactor Open
01b = Contactor Closed
10b = Error
11b = Not Available";
CM_ SG_ 2365202174 HVBusInterface1PosContactorSt "Positive contactor state for this High Voltage Bus (HV Bus) Interface instance.

00b = Contactor Open
01b = Contactor Closed
10b = Error
11b = Not Available";
CM_ BO_ 2365201918 "High Voltage Bus Connection Command
Request opening or closing of contactors that connect the main high-voltage bus to high-voltage device(s) or a sub-bus in an electric or hybrid vehicle.";
CM_ SG_ 2365201918 CRC "The CRC is defined as follows:
• Length: 8 bits
• Polynomial: x^8+x^5+x^3+x^2+x+1
• Initial Value: FFh
• Input Data Reflection: Not reflected
• Result Data Reflection: Not reflected
• XOR value: FFh
SAE makes no claim of the functional safety ...";
CM_ SG_ 2365201918 Counter "The message counter is used to detect situations where the transmitting ECU malfunction repeats the same frame all the time. The receiver of the information may use the counter parameter to detect this situation. The transmitting device will ...";
CM_ SG_ 2365201918 EmbeddedIntegritySupport "Indicates SPN 22785 (HVBCC CRC) and SPN 22784 (HVBCC Counter) are supported by the sender.
00b = HVBCC embedded CRC and Counter are supported by the sender
01b = HVBCC protection is supported using J1939-76 SHM
10b = Reserved
11b = HVBCC CRC and ...";
CM_ SG_ 2365201918 HVBusInterface8ConnectCmd "Command to connect the main high-voltage bus to this high-voltage bus interface instance.  

00b = Open Contactor; Disconnect from high-voltage bus
01b = Close Contactor; Connect to high-voltage bus
10b = Reserved
11b = Don't care / Take no action";
CM_ SG_ 2365201918 HVBusInterface7ConnectCmd "Command to connect the main high-voltage bus to this high-voltage bus interface instance.  

00b = Open Contactor; Disconnect from high-voltage bus
01b = Close Contactor; Connect to high-voltage bus
10b = Reserved
11b = Don't care / Take no action";
CM_ SG_ 2365201918 HVBusInterface6ConnectCmd "Command to connect the main high-voltage bus to this high-voltage bus interface instance.  

00b = Open Contactor; Disconnect from high-voltage bus
01b = Close Contactor; Connect to high-voltage bus
10b = Reserved
11b = Don't care / Take no action";
CM_ SG_ 2365201918 HVBusInterface5ConnectCmd "Command to connect the main high-voltage bus to this high-voltage bus interface instance.  

00b = Open Contactor; Disconnect from high-voltage bus
01b = Close Contactor; Connect to high-voltage bus
10b = Reserved
11b = Don't care / Take no action";
CM_ SG_ 2365201918 HVBusInterface4ConnectCmd "Command to connect the main high-voltage bus to this high-voltage bus interface instance.  

00b = Open Contactor; Disconnect from high-voltage bus
01b = Close Contactor; Connect to high-voltage bus
10b = Reserved
11b = Don't care / Take no action";
CM_ SG_ 2365201918 HVBusInterface3ConnectCmd "Command to connect the main high-voltage bus to this high-voltage bus interface instance.  

00b = Open Contactor; Disconnect from high-voltage bus
01b = Close Contactor; Connect to high-voltage bus
10b = Reserved
11b = Don't care / Take no action";
CM_ SG_ 2365201918 HVBusInterface2ConnectCmd "Command to connect the main high-voltage bus to this high-voltage bus interface instance.  

00b = Open Contactor; Disconnect from high-voltage bus
01b = Close Contactor; Connect to high-voltage bus
10b = Reserved
11b = Don't care / Take no action";
CM_ SG_ 2365201918 HVBusInterface1ConnectCmd "Command to connect the main high-voltage bus to this high-voltage bus interface instance.  

00b = Open Contactor; Disconnect from high-voltage bus
01b = Close Contactor; Connect to high-voltage bus
10b = Reserved
11b = Don't care / Take no action";
CM_ BO_ 2432310526 "Electronic Engine Controller 25
Engine related parameters";
CM_ SG_ 2432310526 OpSt "Used to identify the status of engine crankcase pressure control Actuator 2.
0000b = Normal
0001b = Alarm (fully operational but needs service)
0010b = Alarm High Severity (functional but transient performance may be reduced)
0011b = Derate ...";
CM_ SG_ 2432310526 TempSt "Used to identify the status of the crankcase pressure control actuator 2 drive circuitry temperature.  Temperature excursions may affect the torque output.
000b = High Most severe
001b = High Least severe
010b = In Range
011b = Low Least severe
 ...";
CM_ SG_ 2432310526 PreliminaryFMI "Used to identify the applicable J1939-73 FMI detected in the crankcase pressure control actuator 2 by the manufacturers software. When there is multiple failures, the most severe is transmitted.
A value of 31 is sent to indicate that no failure has ...";
CM_ SG_ 2432310526 DesPos "The requested position of the Engine Crankcase Pressure Control Actuator 2 by the engine ECU, where 0% represents bypass fully closed and 100% represents bypass fully open. This is the position that the device is attempting to achieve.";
CM_ SG_ 2432310526 Pos "Measures the position of the engine crankcase pressure control actuator 2, where 0% represents actuator is fully closed and 100% represents actuator is fully open.";
CM_ SG_ 2432310526 Temp "Temperature of the engine crankcase pressure control actuator 2 drive circuitry.";
CM_ BO_ 2432310270 "Electronic Engine Controller 24
Engine related parameters";
CM_ SG_ 2432310270 OpSt "Used to identify the status of engine crankcase pressure control Actuator 1.
0000b = Normal
0001b = Alarm (fully operational but needs service)
0010b = Alarm High Severity (functional but transient performance may be reduced)
0011b = Derate ...";
CM_ SG_ 2432310270 TempSt "Used to identify the status of the crankcase pressure control actuator 1 drive circuitry temperature.  Temperature excursions may affect the torque output.
000b = High Most severe
001b = High Least severe
010b = In Range
011b = Low Least severe
 ...";
CM_ SG_ 2432310270 PreliminaryFMI "Used to identify the applicable J1939-73 FMI detected in the crankcase pressure control actuator 1 by the manufacturers software. When there is multiple failures, the most severe is transmitted.
A value of 31 is sent to indicate that no failure has ...";
CM_ SG_ 2432310270 DesPos "The requested position of the Engine Crankcase Pressure Control Actuator 1 by the engine ECU, where 0% represents bypass fully closed and 100% represents bypass fully open. This is the position that the device is attempting to achieve.";
CM_ SG_ 2432310270 Pos "Measures the position of the engine crankcase pressure control actuator 1, where 0% represents actuator is fully closed and 100% represents actuator is fully open.";
CM_ SG_ 2432310270 Temp "Temperature of the engine crankcase pressure control actuator 1 drive circuitry.";
CM_ BO_ 2432310014 "Electronic Engine Controller 23
Engine related parameters";
CM_ SG_ 2432310014 Cmd2 "The command to a crankcase pressure control actuator 2 on an engine, normalized to percent, where 0% nominally represents fully closed and 100% represents fully open.";
CM_ SG_ 2432310014 Cmd1 "The command to a crankcase pressure control actuator 1 on an engine, normalized to percent, where 0% nominally represents fully closed and 100% represents fully open.";
CM_ BO_ 2365200894 "High Voltage Energy Storage System Internal Status 4
Internal status data set 4 for High Voltage Energy Storage System.
The purpose of this PG is to assist in High Voltage Energy Storage System that require additional measurement and contactor ...";
CM_ SG_ 2365200894 HVInternalCur8 "The current in or out of the High Voltage Energy Storage System Internal Circuit 8 (or Pack 1 in systems with only one pack). This parameter should be synchronized with SPN 22929 (HVESS High-Voltage Internal Voltage Level 8) such that a realized ...";
CM_ SG_ 2365200894 HVInternalVLvl8 "The voltage level of the High Voltage Energy Storage System Internal circuit 8 (or Pack 1 in systems with only one pack). This parameter should be synchronized with SPN 22930 (HVESS High-Voltage Internal Current 8) such that a realized power value ...";
CM_ SG_ 2365200894 HVInternalCur7 "The current in or out of the High Voltage Energy Storage System Internal Circuit 7 (or Pack 1 in systems with only one pack). This parameter should be synchronized with SPN 22927 (HVESS High-Voltage Internal Voltage Level 7) such that a realized ...";
CM_ SG_ 2365200894 HVInternalVLvl7 "The voltage level of the High Voltage Energy Storage System Internal circuit 7 (or Pack 1 in systems with only one pack). This parameter should be synchronized with SPN 22928 (HVESS High-Voltage Internal Current 7) such that a realized power value ...";
CM_ BO_ 2365200638 "High Voltage Energy Storage System Internal Status 3
Internal status data set 3 for High Voltage Energy Storage System.
The purpose of this PG is to assist in High Voltage Energy Storage System that require additional measurement and contactor ...";
CM_ SG_ 2365200638 HVInternalCur6 "The current in or out of the High Voltage Energy Storage System Internal Circuit 6 (or Pack 1 in systems with only one pack). This parameter should be synchronized with SPN 22925 (HVESS High-Voltage Internal Voltage Level 6) such that a realized ...";
CM_ SG_ 2365200638 HVInternalVLvl6 "The voltage level of the High Voltage Energy Storage System Internal circuit 6 (or Pack 1 in systems with only one pack). This parameter should be synchronized with SPN 22926 (HVESS High-Voltage Internal Current 6) such that a realized power value ...";
CM_ SG_ 2365200638 HVInternalCur5 "The current in or out of the High Voltage Energy Storage System Internal Circuit 5 (or Pack 1 in systems with only one pack). This parameter should be synchronized with SPN 22923 (HVESS High-Voltage Internal Voltage Level 5) such that a realized ...";
CM_ SG_ 2365200638 HVInternalVLvl5 "The voltage level of the High Voltage Energy Storage System Internal circuit 5 (or Pack 1 in systems with only one pack). This parameter should be synchronized with SPN 22924 (HVESS High-Voltage Internal Current 5) such that a realized power value ...";
CM_ BO_ 2365200382 "High Voltage Energy Storage System Internal Status 2
Internal status data set 2 for High Voltage Energy Storage System.
The purpose of this PG is to assist in High Voltage Energy Storage System that require additional measurement and contactor ...";
CM_ SG_ 2365200382 HVInternalCur4 "The current in or out of the High Voltage Energy Storage System Internal Circuit 4 (or Pack 1 in systems with only one pack). This parameter should be synchronized with SPN 22921 (HVESS High-Voltage Internal Voltage Level 4) such that a realized ...";
CM_ SG_ 2365200382 HVInternalVLvl4 "The voltage level of the High Voltage Energy Storage System Internal circuit 4 (or Pack 1 in systems with only one pack). This parameter should be synchronized with SPN 22922 (HVESS High-Voltage Internal Current 4) such that a realized power value ...";
CM_ SG_ 2365200382 HVInternalCur3 "The current in or out of the High Voltage Energy Storage System Internal Circuit 3 (or Pack 1 in systems with only one pack). This parameter should be synchronized with SPN 22919 (HVESS High-Voltage Internal Voltage Level 3) such that a realized ...";
CM_ SG_ 2365200382 HVInternalVLvl3 "The voltage level of the High Voltage Energy Storage System Internal circuit 3 (or Pack 1 in systems with only one pack). This parameter should be synchronized with SPN 22920 (HVESS High-Voltage Internal Current 3) such that a realized power value ...";
CM_ BO_ 2365200126 "High Voltage Energy Storage System Internal Status 1 
Internal status data set 1 for High Voltage Energy Storage System.
The purpose of this PG is to assist in High Voltage Energy Storage System that require additional measurement and contactor ...";
CM_ SG_ 2365200126 HVInternalCur2 "The current in or out of the High Voltage Energy Storage System Internal Circuit 2 (or Pack 1 in systems with only one pack). This parameter should be synchronized with SPN 22917 (HVESS High-Voltage Internal Voltage Level 2) such that a realized ...";
CM_ SG_ 2365200126 HVInternalVLvl2 "The voltage level of the High Voltage Energy Storage System Internal circuit 2 (or Pack 1 in systems with only one pack). This parameter should be synchronized with SPN 22918 (HVESS High-Voltage Internal Current 2) such that a realized power value ...";
CM_ SG_ 2365200126 HVInternalCur1 "The current in or out of the High Voltage Energy Storage System Internal Circuit 1 (or Pack 1 in systems with only one pack). This parameter should be synchronized with SPN 22915 (HVESS High-Voltage Internal Voltage Level 1) such that a realized ...";
CM_ SG_ 2365200126 HVInternalVLvl1 "The voltage level of the High Voltage Energy Storage System Internal Circuit 1 (or Pack 1 in systems with only one pack). This parameter should be synchronized with SPN 22916 (HVESS High-Voltage Internal Current 1) such that a realized power value ...";
CM_ BO_ 2499417598 "Genset Supporting Functions
Contains control information for the status and supporting functions for generator grid code control functions.
These parameters are intended for stationary Generator/Engine components, not mobile applications.  See ...";
CM_ SG_ 2499417598 GenSimulatedUtilFreqDeactTimer "A timer after which the simulated utility frequency function will be deactivated.";
CM_ SG_ 2499417598 GenSimulatedUtilFreqResult "Simulated utility frequency result for test functionality for Grid Code functions. The simulated frequency result contains of the simulated frequency offset and the offset target.";
CM_ BO_ 2566526206 "Cold Start Emissions Reduction Strategy Average Data
Provides Cold Start Emissions Reduction Strategy (CSERS) Tracking Average Data";
CM_ SG_ 2566526206 AvgTimeUntilCatColdStartTrkTemp "Moving weighted average of (SPN 22236) Time until the catalyst cold start tracking temperature threshold, as defined in 13 CCR 1971.1 (h)(5.9.1)(A), is achieved. See 13 CCR 1971.1 (h)(5.9.3)(B) and (h)(5.9.2)(J) Timer #2 catalyst cold start tracking ...";
CM_ SG_ 2566526206 AvgTimeUntilEngOutput "Moving weighted average of (SPN 22235) Time until the specified FTP engine output energy, as defined in 13 CCR 1971.1 (h)(5.9.1)(D), is achieved. See 13 CCR 1971.1 (h)(5.9.3)(B) and (h)(5.9.2)(I) Timer #1 engine energy output accumulated time.";
CM_ SG_ 2566526206 AvgEGRMassUntilFtpTemp "Moving weighted average of (SPN 22234) EGR mass until the FTP catalyst cold start tracking temperature, as defined in 13 CCR 1971.1 (h)(5.9.1)(A), is achieved. See 13 CCR 1971.1 (h)(5.9.3)(B) and (h)(5.9.2)(H) EGR mass flow tracker #3.";
CM_ SG_ 2566526206 AvgEGRMassAtEngOutput "Moving weighted average of (SPN 22233) EGR mass until the specified FTP engine output energy, as defined in 13 CCR 1971.1 (h)(5.9.1)(D), is achieved. See 13 CCR 1971.1 (h)(5.9.3)(B) and (h)(5.9.2)(G) EGR mass flow tracker #2.";
CM_ SG_ 2566526206 AvgEGRMassAtColdStart "Moving weighted average of (SPN 22232) EGR mass until the FTP catalyst cold start tracking time, as defined in 13 CCR 1971.1 (h)(5.9.1)(B), is achieved. See 13 CCR 1971.1 (h)(5.9.3)(B) and (h)(5.9.2)(F) EGR mass flow tracker #1.";
CM_ SG_ 2566526206 EngEtilCatTempThld "Moving weighted average of (SPN 22231) Engine output energy until the catalyst cold start tracking temperature threshold, as defined in 13 CCR 1971.1 (h)(5.9.1)(A), is achieved. See 13 CCR 1971.1 (h)(5.9.3)(B) and (h)(5.9.2)(E) Engine output energy ...";
CM_ SG_ 2566526206 EngEtilColdStart "Moving weighted average of (SPN 22230) Engine output energy until the FTP catalyst cold start tracking time, as defined in 13 CCR 1971.1 (h)(5.9.1)(B), is achieved. See 13 CCR 1971.1 (h)(5.9.3)(B) and (h)(5.9.2)(D) Engine output energy tracker #1.";
CM_ SG_ 2566526206 CatEtilCatTempThld "Moving weighted average of (SPN 22229) Pre-SCR heat energy until the catalyst cold start tracking temperature threshold, as defined in 13 CCR 1971.1 (h)(5.9.1)(A), is achieved. See 13 CCR 1971.1 (h)(5.9.3)(B) and (h)(5.9.2)(C) Heat energy release ...";
CM_ SG_ 2566526206 CatEtilEngOutput "Moving weighted average of (SPN 22228) Pre-SCR heat energy until the specified FTP engine output energy, as defined in 13 CCR 1971.1 (h)(5.9.1)(D) is achieved. See 13 CCR 1971.1 (h)(5.9.3)(B) and (h)(5.9.2)(B) Engine output energy tracker #2.";
CM_ SG_ 2566526206 CatEtilColdStart "Moving weighted average of (SPN 22227) Pre-SCR heat energy (in units of kJ) until the FTP catalyst cold start tracking time, as defined in 13 CCR 1971.1 (h)(5.9.1)(B), is achieved. See 13 CCR 1971.1 (h)(5.9.3)(B) and (h)(5.9.2)(A) Heat energy ...";
CM_ BO_ 2566525950 "Cold Start Emissions Reduction Strategy Current Operating Cycle Data
Provides Cold Start Emissions Reduction Strategy (CSERS) Tracking Current Operating Cycle Data";
CM_ SG_ 2566525950 TimeUntilCatTempThld "Time until the catalyst cold start tracking temperature threshold, as defined in 13 CCR 1971.1 (h)(5.9.1)(A), is achieved for the current operating cycle. See 13 CCR 1971.1 (h)(5.9.2)(J) Timer #2 catalyst cold start tracking accumulated time ...";
CM_ SG_ 2566525950 TimeUntilEngOutput "Time until the specified FTP engine output energy, as defined in 13 CCR 1971.1 (h)(5.9.1)(D), is achieved for the current operating cycle. See 13 CCR 1971.1 (h)(5.9.2)(I) Timer #1 engine energy output accumulated time.";
CM_ SG_ 2566525950 EgrMassUntilCatTempThld "EGR mass until the catalyst cold start tracking temperature threshold, as defined in 13 CCR 1971.1 (h)(5.9.1)(A), is achieved for the current operating cycle. See 13 CCR 1971.1 (h)(5.9.2)(H) EGR mass flow tracker #3.";
CM_ SG_ 2566525950 EgrMassUntilEngOutput "EGR mass until the specified FTP engine output energy, as defined in 13 CCR 1971.1 (h)(5.9.1)(D), is achieved for the current operating cycle.  See 13 CCR 1971.1 (h)(5.9.2)(G) EGR mass flow tracker #2.";
CM_ SG_ 2566525950 EgrMassUntilColdStart "EGR mass until the FTP catalyst cold start tracking time, as defined in 13 CCR 1971.1 (h)(5.9.1)(B), is achieved for the current operating cycle. See 13 CCR 1971.1 (h)(5.9.2)(F) EGR mass flow tracker #1.";
CM_ SG_ 2566525950 EngOutEnergyUntilCatTempThld "Engine output energy until the catalyst cold start tracking light off temperature threshold, as defined in 13 CCR 1971.1 (h)(5.9.1)(A), is achieved for the current operating cycle. See 13 CCR 1971.1 (h)(5.9.2)(E) Engine output energy tracker #2.";
CM_ SG_ 2566525950 EngOutEnergyUntilColdStart "Engine output energy until the FTP catalyst cold start tracking time, as defined in 13 CCR 1971.1 (h)(5.9.1)(B), is achieved for the current operating cycle. See 13 CCR 1971.1 (h)(5.9.2)(D) Engine output energy tracker #1.";
CM_ SG_ 2566525950 CatHeatEnergyUntilCatTempThld "Pre-SCR heat energy until the catalyst cold start tracking temperature threshold, as defined in 13 CCR 1971.1 (h)(5.9.1)(A), is achieved. See 13 CCR 1971.1 (h)(5.9.2)(C) Heat energy release tracker #3.";
CM_ SG_ 2566525950 CatHeatEnergyUntilEngOutput "Pre-SCR heat energy until the specified FTP engine output energy, as defined in 13 CCR 1971.1 (h)(5.9.1)(D), is achieved for the current operating cycle. See 13 CCR 1971.1 (h)(5.9.2)(B) Heat energy release tracker #2.";
CM_ SG_ 2566525950 CatHeatEnergyUntilColdStart "Pre-SCR heat energy (in units of kJ) until the FTP catalyst cold start tracking time, as defined in 13 CCR 1971.1 (h)(5.9.1)(B), is achieved for the current operating cycle. See 13 CCR 1971.1 (h)(5.9.2)(A) Heat energy release tracker #1.";
CM_ BO_ 2566525694 "Motor/Generator Location Extended
This message captures the instances and locations of electric motors on the towing vehicle and associated trailer(s) in the vehicle system. The number of axles and Motor/Generator instances will vary as trailers ...";
CM_ SG_ 2566525694 VehSegment_4 "Conveys the vehicle segment where the given axle is located. The definition of the trailer (i.e. Trailer 1, Trailer 2,3,4,5) follows the ISO11992-2 specification (Section 6.3 Address Assignment) for the order of the trailer assigment.
0000b = ...";
CM_ SG_ 2566525694 TrailerType_4 "Describes the axle topology of a given trailer segment. These types of trailers are taken from ISO7641 and ISO13052. See Appendix D for additional information on trailer types
0000b = Not applicable; segment is not a trailer
0001b = Semi (e.g ...";
CM_ SG_ 2566525694 MotGenRotation_4 "Direction of Motor/Generator (MG) rotation with respect to forward gear and forward vehicle direction. Positive and negative speeds directly correlate with the signs of the speed used to control, or as reported from, a Motor/Generator, e.g. MG1IC ...";
CM_ SG_ 2566525694 MotGenLocation_4 "For the given SPN 22254 (Axle Instance), this is the location of a given Motor/Generator (MG) instance on that axle.
0000b = Not Driven
0001b = Left Side - MG located on the left side of the axle when facing forward in the driver’s seat. Includes ...";
CM_ SG_ 2566525694 MotGenIdentification_4 "Identifies the Motor/Generator instance assigned to a given axle and location. The instance number correlates to the Motor/Generator (MG) messages being used, e.g. MG1IC, MG2IC, MG3IC, MG4IC, MG5IC, MG6IC, etc.
0000b = No Motor/Generator
0001b = ...";
CM_ SG_ 2566525694 AxleInstance_4 "Number of the axle instances being reported on from this controller application for this vehicle segment. Axle 1 is at the front of the vehicle segment and the count will increase towards the rear. If the parameter is No Axle this indicates that the ...";
CM_ SG_ 2566525694 VehSegment_3 "Conveys the vehicle segment where the given axle is located. The definition of the trailer (i.e. Trailer 1, Trailer 2,3,4,5) follows the ISO11992-2 specification (Section 6.3 Address Assignment) for the order of the trailer assigment.
0000b = ...";
CM_ SG_ 2566525694 TrailerType_3 "Describes the axle topology of a given trailer segment. These types of trailers are taken from ISO7641 and ISO13052. See Appendix D for additional information on trailer types
0000b = Not applicable; segment is not a trailer
0001b = Semi (e.g ...";
CM_ SG_ 2566525694 MotGenRotation_3 "Direction of Motor/Generator (MG) rotation with respect to forward gear and forward vehicle direction. Positive and negative speeds directly correlate with the signs of the speed used to control, or as reported from, a Motor/Generator, e.g. MG1IC ...";
CM_ SG_ 2566525694 MotGenLocation_3 "For the given SPN 22254 (Axle Instance), this is the location of a given Motor/Generator (MG) instance on that axle.
0000b = Not Driven
0001b = Left Side - MG located on the left side of the axle when facing forward in the driver’s seat. Includes ...";
CM_ SG_ 2566525694 MotGenIdentification_3 "Identifies the Motor/Generator instance assigned to a given axle and location. The instance number correlates to the Motor/Generator (MG) messages being used, e.g. MG1IC, MG2IC, MG3IC, MG4IC, MG5IC, MG6IC, etc.
0000b = No Motor/Generator
0001b = ...";
CM_ SG_ 2566525694 AxleInstance_3 "Number of the axle instances being reported on from this controller application for this vehicle segment. Axle 1 is at the front of the vehicle segment and the count will increase towards the rear. If the parameter is No Axle this indicates that the ...";
CM_ SG_ 2566525694 VehSegment_2 "Conveys the vehicle segment where the given axle is located. The definition of the trailer (i.e. Trailer 1, Trailer 2,3,4,5) follows the ISO11992-2 specification (Section 6.3 Address Assignment) for the order of the trailer assigment.
0000b = ...";
CM_ SG_ 2566525694 TrailerType_2 "Describes the axle topology of a given trailer segment. These types of trailers are taken from ISO7641 and ISO13052. See Appendix D for additional information on trailer types
0000b = Not applicable; segment is not a trailer
0001b = Semi (e.g ...";
CM_ SG_ 2566525694 MotGenRotation_2 "Direction of Motor/Generator (MG) rotation with respect to forward gear and forward vehicle direction. Positive and negative speeds directly correlate with the signs of the speed used to control, or as reported from, a Motor/Generator, e.g. MG1IC ...";
CM_ SG_ 2566525694 MotGenLocation_2 "For the given SPN 22254 (Axle Instance), this is the location of a given Motor/Generator (MG) instance on that axle.
0000b = Not Driven
0001b = Left Side - MG located on the left side of the axle when facing forward in the driver’s seat. Includes ...";
CM_ SG_ 2566525694 MotGenIdentification_2 "Identifies the Motor/Generator instance assigned to a given axle and location. The instance number correlates to the Motor/Generator (MG) messages being used, e.g. MG1IC, MG2IC, MG3IC, MG4IC, MG5IC, MG6IC, etc.
0000b = No Motor/Generator
0001b = ...";
CM_ SG_ 2566525694 AxleInstance_2 "Number of the axle instances being reported on from this controller application for this vehicle segment. Axle 1 is at the front of the vehicle segment and the count will increase towards the rear. If the parameter is No Axle this indicates that the ...";
CM_ SG_ 2566525694 SA_4 "Indicates the source address of the Motor/Generator (MG) 

255 (FFh) indicates this parameter is not supported such as when there is no MG present on the given axle instance. I.e. SPN 22256 (Motor/Generator Identification) = 0000b.";
CM_ SG_ 2566525694 SA_3 "Indicates the source address of the Motor/Generator (MG) 

255 (FFh) indicates this parameter is not supported such as when there is no MG present on the given axle instance. I.e. SPN 22256 (Motor/Generator Identification) = 0000b.";
CM_ SG_ 2566525694 SA_2 "Indicates the source address of the Motor/Generator (MG) 

255 (FFh) indicates this parameter is not supported such as when there is no MG present on the given axle instance. I.e. SPN 22256 (Motor/Generator Identification) = 0000b.";
CM_ SG_ 2566525694 SA_1 "Indicates the source address of the Motor/Generator (MG) 

255 (FFh) indicates this parameter is not supported such as when there is no MG present on the given axle instance. I.e. SPN 22256 (Motor/Generator Identification) = 0000b.";
CM_ SG_ 2566525694 TrailerType_1 "Describes the axle topology of a given trailer segment. These types of trailers are taken from ISO7641 and ISO13052. See Appendix D for additional information on trailer types
0000b = Not applicable; segment is not a trailer
0001b = Semi (e.g ...";
CM_ SG_ 2566525694 VehSegment_1 "Conveys the vehicle segment where the given axle is located. The definition of the trailer (i.e. Trailer 1, Trailer 2,3,4,5) follows the ISO11992-2 specification (Section 6.3 Address Assignment) for the order of the trailer assigment.
0000b = ...";
CM_ SG_ 2566525694 MotGenRotation_1 "Direction of Motor/Generator (MG) rotation with respect to forward gear and forward vehicle direction. Positive and negative speeds directly correlate with the signs of the speed used to control, or as reported from, a Motor/Generator, e.g. MG1IC ...";
CM_ SG_ 2566525694 MotGenIdentification_1 "Identifies the Motor/Generator instance assigned to a given axle and location. The instance number correlates to the Motor/Generator (MG) messages being used, e.g. MG1IC, MG2IC, MG3IC, MG4IC, MG5IC, MG6IC, etc.
0000b = No Motor/Generator
0001b = ...";
CM_ SG_ 2566525694 MotGenLocation_1 "For the given SPN 22254 (Axle Instance), this is the location of a given Motor/Generator (MG) instance on that axle.
0000b = Not Driven
0001b = Left Side - MG located on the left side of the axle when facing forward in the driver’s seat. Includes ...";
CM_ SG_ 2566525694 AxleInstance_1 "Number of the axle instances being reported on from this controller application for this vehicle segment. Axle 1 is at the front of the vehicle segment and the count will increase towards the rear. If the parameter is No Axle this indicates that the ...";
CM_ SG_ 2566525694 NumOfAxleInstancesBeingReported "The number of axles being reported on by this controller.";
CM_ BO_ 2566525438 "Aftertreatment 1 Light Off SCR Service Information 1
This message contains Light Off SCR service information for aftertreatment system 1 (or bank 1).";
CM_ SG_ 2566525438 TripLightOffSCRDEF "DEF consumed by the light-off SCR device during all or part of a journey.

See SPN 6563 (Aftertreatment Trip Diesel Exhaust Fluid) for the accumulation of all DEF used.";
CM_ SG_ 2566525438 TotalLightOffSCRDEFUsed "Total amount of DEF used by the light off SCR device over the lifetime of the device.

See SPN 5963 (Aftertreatment 1 Total Diesel Exhaust Fluid Used) for the accumulation of all DEF used.";
CM_ BO_ 2566525182 "On Board Programming Event Time/Date 
On Board Programming Event Time and Date. This is the time when the target ECU will have its software updated.";
CM_ SG_ 2566525182 OBPEventLocalHourOffset "The hour component of the offset between the UTC (Universal Time Coordinate) time and date and a local time zone time and date.  This is the number of hours to add to UTC, a.k.a. GMT, time and date to convert to the time and date in the local time ...";
CM_ SG_ 2566525182 OBPEventLocalMinuteOffset "The minute component of the offset between the UTC time and date and a local time zone time and date.  This is the number of minutes to add to UTC (Universal Time Coordinate) time and date to convert to the time and date in the local time zone  ...";
CM_ SG_ 2566525182 OBPEventYear "The year component of the On Board Programming event date.  This should be reported as the year component of the On Board Programming event date at UTC (Universal Time Coordinate), a.k.a. GMT; however, it may be reported as the year component of the ...";
CM_ SG_ 2566525182 OBPEventDay "The day component of the On Board Programming event calendar date.  This should be reported as the day component of the On Board Programming event date at UTC (Universal Time Coordinate), a.k.a. GMT; however, it may be reported as the day component ...";
CM_ SG_ 2566525182 OBPEventMonth "The month component of the On Board Programming event calendar date. This should be reported as the month component of the On Board Programming event date at UTC (Universal Time Coordinate), a.k.a. GMT; however, it may be reported as the month ...";
CM_ SG_ 2566525182 OBPEventHours "The hour component of the On Board Programming event time. This should be reported as the hour component of the On Board Programming event time at UTC (Universal Time Coordinate), a.k.a. GMT; however, it may be reported as the hour component of the ...";
CM_ SG_ 2566525182 OBPEventMinutes "The minutes component of the On Board Programming event time. This should be reported as the minutes component of the On Board Programming event time at UTC (Universal Time Coordinate), a.k.a. GMT; however, it may be reported as the minutes ...";
CM_ SG_ 2566525182 OBPEventSeconds "The seconds component of the On Board Programming event time. This should be reported as the seconds component of the On Board Programming event time at UTC (Universal Time Coordinate), a.k.a. GMT; however, it may be reported as the seconds ...";
CM_ BO_ 2566524926 "Motor/Generator 6 Thermal Performance Status  
Motor Thermal Performance Status Information";
CM_ SG_ 2566524926 CapLmt "A manufacturer defined thermal threshold beyond which product life may be reduced. 
See also SPN 22963 (Motor/Generator 6 Thermal Capability Used).
Detailed description is attached in Appendix D figure SPNxxx_A.";
CM_ SG_ 2566524926 CapUsed "Thermal Capability Used of this Motor/Generator instance. The calculation method must be defined by the manufacturer.
Thermal Capability is an indicator of available motor power capability in relation to thermal conditions.
Detailed description is ...";
CM_ BO_ 2566524670 "Motor/Generator 5 Thermal Performance Status  
Motor Thermal Performance Status Information";
CM_ SG_ 2566524670 CapLmt "A manufacturer defined thermal threshold beyond which product life may be reduced. 
See also SPN 22959 (Motor/Generator 5 Thermal Capability Used).
Detailed description is attached in Appendix D figure SPNxxx_A.";
CM_ SG_ 2566524670 CapUsed "Thermal Capability Used of this Motor/Generator instance. The calculation method must be defined by the manufacturer.
Thermal Capability is an indicator of available motor power capability in relation to thermal conditions.
Detailed description is ...";
CM_ BO_ 2566524414 "Motor/Generator 4 Thermal Performance Status  
Motor Thermal Performance Status Information";
CM_ SG_ 2566524414 CapLmt "A manufacturer defined thermal threshold beyond which product life may be reduced. 
See also SPN 22955 (Motor/Generator 4 Thermal Capability Used).
Detailed description is attached in Appendix D figure SPNxxx_A.";
CM_ SG_ 2566524414 CapUsed "Thermal Capability Used of this Motor/Generator instance. The calculation method must be defined by the manufacturer.
Thermal Capability is an indicator of available motor power capability in relation to thermal conditions.
Detailed description is ...";
CM_ BO_ 2566524158 "Motor/Generator 3 Thermal Performance Status  
Motor Thermal Performance Status Information";
CM_ SG_ 2566524158 CapLmt "A manufacturer defined thermal threshold beyond which product life may be reduced. 
See also SPN 22951 (Motor/Generator 3 Thermal Capability Used).
Detailed description is attached in Appendix D figure SPNxxx_A.";
CM_ SG_ 2566524158 CapUsed "Thermal Capability Used of this Motor/Generator instance. The calculation method must be defined by the manufacturer.
Thermal Capability is an indicator of available motor power capability in relation to thermal conditions.
Detailed description is ...";
CM_ BO_ 2566523902 "Motor/Generator 2 Thermal Performance Status  
Motor Thermal Performance Status Information";
CM_ SG_ 2566523902 CapLmt "A manufacturer defined thermal threshold beyond which product life may be reduced. 
See also SPN 22947 (Motor/Generator 2 Thermal Capability Used).
Detailed description is attached in Appendix D figure SPNxxx_A.";
CM_ SG_ 2566523902 CapUsed "Thermal Capability Used of this Motor/Generator instance. The calculation method must be defined by the manufacturer.
Thermal Capability is an indicator of available motor power capability in relation to thermal conditions.
Detailed description is ...";
CM_ BO_ 2566523646 "Motor/Generator 1 Thermal Performance Status  
Motor Thermal Performance Status Information";
CM_ SG_ 2566523646 CapLmt "A manufacturer defined thermal threshold beyond which product life may be reduced. See also SPN 22943 (Motor/Generator 1 Thermal Capability Used). Detailed description is attached in Appendix D figure SPNxxx_A.";
CM_ SG_ 2566523646 CapUsed "Thermal Capability Used of this Motor/Generator instance. The calculation method must be defined by the manufacturer. Thermal Capability is an indicator of the available motor power capability in relation to thermal conditions. Detailed description ...";
CM_ BO_ 2566091006 "Electrified Accessory Motor Status 2
Status data set 2 of electrified Accessory Motor controller.   See PGN 32000 for the corresponding command message.  This PG should only be used in a case where the specific PG for the Electrified Accessory is ...";
CM_ SG_ 2566091006 InstanceOfStDataSet2 "Indicates the electrified accessory instance that is providing status data set 2.
0000b = Instance 1
0001b = Instance 2
0010b = Instance 3
0011b = Instance 4
0100b = Instance 5
0101b = Instance 6
0110b = Instance 7
0111b = Instance 8
1000b ...";
CM_ SG_ 2566091006 HVILSt "High Voltage Interlock Loop (HVIL) state, as measured by this device.

00b = HVIL Closed
01b = HVIL Open
10b = Error
11b = Not Available";
CM_ SG_ 2566091006 Cur "The current in or out of this device with respect to the electrical bus that is utilized by this device as the power source/sink for generating motor torque.  This parameter should be synchronized with SPN 22674 (Electrified Accessory Motor Voltage) ...";
CM_ SG_ 2566091006 V "The voltage level of the electrical bus that is utilized by this device as the power source/sink for generating motor torque, as measured at the input of this device.  Note that one design alternative for this device utilizes a first electrical bus ...";
CM_ BO_ 2566090750 "Electrified Accessory Generator Coolant Fan Status 2
Status data set 2 of electrified accessory: Generator Coolant Fan.  See PGN 26368 for the corresponding command message.";
CM_ SG_ 2566090750 HVILSt "High Voltage Interlock Loop (HVIL) state, as measured by this device.

00b = HVIL Closed
01b = HVIL Open
10b = Error
11b = Not Available";
CM_ SG_ 2566090750 Cur "The current in or out of this device with respect to the electrical bus that is utilized by this device as the power source/sink for generating motor torque.  This parameter should be synchronized with SPN 22671 (Generator Coolant Fan Voltage) such ...";
CM_ SG_ 2566090750 V "The voltage level of the electrical bus that is utilized by this device as the power source/sink for generating motor torque, as measured at the input of this device.  Note that one design alternative for this device utilizes a first electrical bus ...";
CM_ BO_ 2566090494 "Electrified Accessory Generator Coolant Pump Status 2
Status data set 2 of electrified accessory: Generator Coolant Pump.  See PGN 26112 for the corresponding command message.";
CM_ SG_ 2566090494 HVILSt "High Voltage Interlock Loop (HVIL) state, as measured by this device.

00b = HVIL Closed
01b = HVIL Open
10b = Error
11b = Not Available";
CM_ SG_ 2566090494 Cur "The current in or out of this device with respect to the electrical bus that is utilized by this device as the power source/sink for generating motor torque.  This parameter should be synchronized with SPN 22668 (Generator Coolant Pump Voltage) such ...";
CM_ SG_ 2566090494 V "The voltage level of the electrical bus that is utilized by this device as the power source/sink for generating motor torque, as measured at the input of this device.  Note that one design alternative for this device utilizes a first electrical bus ...";
CM_ BO_ 2566090238 "Electrified Accessory Power Electronics Coolant Pump Status 2
Status data set 2 of electrified Accessory: Power Electronics Coolant Pump.   See PGN 31488 for the corresponding command message.";
CM_ SG_ 2566090238 HVILSt "High Voltage Interlock Loop (HVIL) state, as measured by this device.

00b = HVIL Closed
01b = HVIL Open
10b = Error
11b = Not Available";
CM_ SG_ 2566090238 Cur "The current in or out of this device with respect to the electrical bus that is utilized by this device as the power source/sink for generating motor torque.  This parameter should be synchronized with SPN 22665 (Power Electronics Coolant Pump ...";
CM_ SG_ 2566090238 V "The voltage level of the electrical bus that is utilized by this device as the power source/sink for generating motor torque, as measured at the input of this device.  Note that one design alternative for this device utilizes a first electrical bus ...";
CM_ BO_ 2566089982 "Electrified Accessory Propulsion Motor Coolant Pump Status 2
Status data set 2 of electrified Accessory: Propulsion Motor Coolant Pump.   See PGN 31232 for the corresponding command message.";
CM_ SG_ 2566089982 HVILSt "High Voltage Interlock Loop (HVIL) state, as measured by this device.

00b = HVIL Closed
01b = HVIL Open
10b = Error
11b = Not Available";
CM_ SG_ 2566089982 Cur "The current in or out of this device with respect to the electrical bus that is utilized by this device as the power source/sink for generating motor torque.  This parameter should be synchronized with SPN 22662 (Propulsion Motor Coolant Pump ...";
CM_ SG_ 2566089982 V "The voltage level of the electrical bus that is utilized by this device as the power source/sink for generating motor torque, as measured at the input of this device.  Note that one design alternative for this device utilizes a first electrical bus ...";
CM_ BO_ 2566089726 "Electrified Accessory Propulsion Motor Oil Pump Status 2
Status data set 2 of electrified Accessory: Propulsion Motor Oil Pump.   See PGN 30976 for the corresponding command message.";
CM_ SG_ 2566089726 HVILSt "High Voltage Interlock Loop (HVIL) state, as measured by this device.

00b = HVIL Closed
01b = HVIL Open
10b = Error
11b = Not Available";
CM_ SG_ 2566089726 Cur "The current in or out of this device with respect to the electrical bus that is utilized by this device as the power source/sink for generating motor torque.  This parameter should be synchronized with SPN 22659 (Propulsion Motor Oil Pump Voltage) ...";
CM_ SG_ 2566089726 V "The voltage level of the electrical bus that is utilized by this device as the power source/sink for generating motor torque, as measured at the input of this device.  Note that one design alternative for this device utilizes a first electrical bus ...";
CM_ BO_ 2566089470 "Electrified Accessory Power Electronics Coolant Fan 1 Status 2
Status data set 2 of electrified Accessory: Power Electronics Coolant Fan 1.   See PGN 30720 for the corresponding command message.";
CM_ SG_ 2566089470 HVILSt "High Voltage Interlock Loop (HVIL) state, as measured by this device.

00b = HVIL Closed
01b = HVIL Open
10b = Error
11b = Not Available";
CM_ SG_ 2566089470 Cur "The current in or out of this device with respect to the electrical bus that is utilized by this device as the power source/sink for generating motor torque.  This parameter should be synchronized with SPN 22656 (Power Electronics Coolant Fan 1 ...";
CM_ SG_ 2566089470 V "The voltage level of the electrical bus that is utilized by this device as the power source/sink for generating motor torque, as measured at the input of this device.  Note that one design alternative for this device utilizes a first electrical bus ...";
CM_ BO_ 2566089214 "Electrified Accessory Power Electronics Coolant Fan 2 Status 2
Status data set 2 of electrified Accessory: Power Electronics Coolant Fan 2.   See PGN 30464 for the corresponding command message.";
CM_ SG_ 2566089214 HVILSt "High Voltage Interlock Loop (HVIL) state, as measured by this device.

00b = HVIL Closed
01b = HVIL Open
10b = Error
11b = Not Available";
CM_ SG_ 2566089214 Cur "The current in or out of this device with respect to the electrical bus that is utilized by this device as the power source/sink for generating motor torque.  This parameter should be synchronized with SPN 22653 (Power Electronics Coolant Fan 2 ...";
CM_ SG_ 2566089214 V "The voltage level of the electrical bus that is utilized by this device as the power source/sink for generating motor torque, as measured at the input of this device.  Note that one design alternative for this device utilizes a first electrical bus ...";
CM_ BO_ 2566088958 "Electrified Accessory Power Electronics Coolant Fan 3 Status 2
Status data set 2 of electrified Accessory: Power Electronics Coolant Fan 3.   See PGN 30208 for the corresponding command message.";
CM_ SG_ 2566088958 HVILSt "High Voltage Interlock Loop (HVIL) state, as measured by this device.

00b = HVIL Closed
01b = HVIL Open
10b = Error
11b = Not Available";
CM_ SG_ 2566088958 Cur "The current in or out of this device with respect to the electrical bus that is utilized by this device as the power source/sink for generating motor torque.  This parameter should be synchronized with SPN 22650 (Power Electronics Coolant Fan 3 ...";
CM_ SG_ 2566088958 V "The voltage level of the electrical bus that is utilized by this device as the power source/sink for generating motor torque, as measured at the input of this device.  Note that one design alternative for this device utilizes a first electrical bus ...";
CM_ BO_ 2566088702 "Electrified Accessory Propulsion Motor Coolant Fan 1 Status 2
Status data set 2 of electrified Accessory: Propulsion Motor Coolant Fan 1.   See PGN 29952 for the corresponding command message.";
CM_ SG_ 2566088702 HVILSt "High Voltage Interlock Loop (HVIL) state, as measured by this device.

00b = HVIL Closed
01b = HVIL Open
10b = Error
11b = Not Available";
CM_ SG_ 2566088702 Cur "The current in or out of this device with respect to the electrical bus that is utilized by this device as the power source/sink for generating motor torque.  This parameter should be synchronized with SPN 22647 (Propulsion Motor Coolant Fan 1 ...";
CM_ SG_ 2566088702 V "The voltage level of the electrical bus that is utilized by this device as the power source/sink for generating motor torque, as measured at the input of this device.  Note that one design alternative for this device utilizes a first electrical bus ...";
CM_ BO_ 2566088446 "Electrified Accessory Propulsion Motor Coolant Fan 2 Status 2
Status data set 2 of electrified Accessory: Propulsion Motor Coolant Fan 2.   See PGN 29696 for the corresponding command message.";
CM_ SG_ 2566088446 HVILSt "High Voltage Interlock Loop (HVIL) state, as measured by this device.

00b = HVIL Closed
01b = HVIL Open
10b = Error
11b = Not Available";
CM_ SG_ 2566088446 Cur "The current in or out of this device with respect to the electrical bus that is utilized by this device as the power source/sink for generating motor torque.  This parameter should be synchronized with SPN 22644 (Propulsion Motor Coolant Fan 2 ...";
CM_ SG_ 2566088446 V "The voltage level of the electrical bus that is utilized by this device as the power source/sink for generating motor torque, as measured at the input of this device.  Note that one design alternative for this device utilizes a first electrical bus ...";
CM_ BO_ 2566088190 "Electrified Accessory Propulsion Motor Coolant Fan 3 Status 2
Status data set 2 of electrified Accessory: Propulsion Motor Coolant Fan 3.   See PGN 29440 for the corresponding command message.";
CM_ SG_ 2566088190 HVILSt "High Voltage Interlock Loop (HVIL) state, as measured by this device.

00b = HVIL Closed
01b = HVIL Open
10b = Error
11b = Not Available";
CM_ SG_ 2566088190 Cur "The current in or out of this device with respect to the electrical bus that is utilized by this device as the power source/sink for generating motor torque.  This parameter should be synchronized with SPN 22641 (Propulsion Motor Coolant Fan 3 ...";
CM_ SG_ 2566088190 V "The voltage level of the electrical bus that is utilized by this device as the power source/sink for generating motor torque, as measured at the input of this device.  Note that one design alternative for this device utilizes a first electrical bus ...";
CM_ BO_ 2364761342 "Tracked Vehicle Data
Contains data pertaining specifically to tracked vehicles, such as a tank or bulldozer.";
CM_ SG_ 2364761342 RightTransOutShaftDirSpd "Rotational speed of the right-side output shaft. The right side of the vehicle is to the operator's right during normal forward operation. Positive output shaft rotation occurs when the right side of the vehicle moves forward.";
CM_ SG_ 2364761342 LeftTransOutShaftDirSpd "Rotational speed of the left-side output shaft. The left side of the vehicle is to the operator's left during normal forward operation. Positive output shaft rotation occurs when the left side of the vehicle moves forward.";
CM_ BO_ 2364761086 "High Voltage Energy Storage Pack 12 Data 13
Data set 13 (electrical data) for High Voltage Energy Storage Pack 12.";
CM_ SG_ 2364761086 NomChargeCurLmt "The nominal current flow limit into the High Voltage Energy Storage Pack instance. This limit is a preferred boundary for normal operation.  Operating within this limit reduces negative impacts on battery life or battery health, but should not ...";
CM_ SG_ 2364761086 NomDisCurLmt "The nominal current flow limit out of the High Voltage Energy Storage Pack instance. This limit is a preferred boundary for normal operation.  Operating within this limit reduces negative impacts on battery life or battery health, but should not ...";
CM_ SG_ 2364761086 MaxCurChargeCurLmt "The maximum instantaneous current flow limit into this High Voltage Energy Storage Pack instance. This parameter is defined from the high voltage energy storage pack's point of view and should reflect the instantaneous capability of the pack.  The ...";
CM_ SG_ 2364761086 MaxCurDisCurLmt "The maximum instantaneous current flow limit out of this High Voltage Energy Storage Pack instance. This parameter is defined from the high voltage energy storage pack's point of view and should reflect the instantaneous capability of the pack.  The ...";
CM_ BO_ 2364760830 "High Voltage Energy Storage Pack 12 Data 12
Data set 12 (electrical data) for High Voltage Energy Storage Pack 12.";
CM_ SG_ 2364760830 Cur "The current in or out of this High Voltage Energy Storage Pack instance. This parameter should be synchronized with SPN 22602 (HVESP12 Voltage Level (Extended Range)) such that a realized power value can be calculated. This parameter is defined from ...";
CM_ SG_ 2364760830 Lvl "The voltage level of this High Voltage Energy Storage Pack instance. This parameter should be synchronized with SPN 22603 (HVESP12 Current (Extended Range)) such that a realized power value can be calculated. If the HVES component physically ...";
CM_ SG_ 2364760830 AvailableChargePwr "The rate at which this High Voltage Energy Storage Pack instance can currently receive energy from a regenerative or recharging system.
This parameter is for one of multiple packs in an HVESS. If there is only one pack in the system, the HVESS ...";
CM_ SG_ 2364760830 AvailableDisPwr "The rate at which this High Voltage Energy Storage Pack instance can currently provide energy for propulsion or other uses.
This parameter is for one of multiple packs in an HVESS. If there is only one pack in the system, the HVESS parameters ...";
CM_ BO_ 2364760574 "High Voltage Energy Storage Pack 11 Data 13
Data set 13 (electrical data) for High Voltage Energy Storage Pack 11.";
CM_ SG_ 2364760574 NomChargeCurLmt "The nominal current flow limit into the High Voltage Energy Storage Pack instance. This limit is a preferred boundary for normal operation.  Operating within this limit reduces negative impacts on battery life or battery health, but should not ...";
CM_ SG_ 2364760574 NomDisCurLmt "The nominal current flow limit out of the High Voltage Energy Storage Pack instance. This limit is a preferred boundary for normal operation.  Operating within this limit reduces negative impacts on battery life or battery health, but should not ...";
CM_ SG_ 2364760574 MaxCurChargeCurLmt "The maximum instantaneous current flow limit into this High Voltage Energy Storage Pack instance. This parameter is defined from the high voltage energy storage pack's point of view and should reflect the instantaneous capability of the pack.  The ...";
CM_ SG_ 2364760574 MaxCurDisCurLmt "The maximum instantaneous current flow limit out of this High Voltage Energy Storage Pack instance. This parameter is defined from the high voltage energy storage pack's point of view and should reflect the instantaneous capability of the pack.  The ...";
CM_ BO_ 2364760318 "High Voltage Energy Storage Pack 11 Data 12
Data set 12 (electrical data) for High Voltage Energy Storage Pack 11.";
CM_ SG_ 2364760318 Cur "The current in or out of this High Voltage Energy Storage Pack instance. This parameter should be synchronized with SPN 22580 (HVESP11 Voltage Level (Extended Range)) such that a realized power value can be calculated. This parameter is defined from ...";
CM_ SG_ 2364760318 Lvl "The voltage level of this High Voltage Energy Storage Pack instance. This parameter should be synchronized with SPN 22581 (HVESP11 Current (Extended Range)) such that a realized power value can be calculated. If the HVES component physically ...";
CM_ SG_ 2364760318 AvailableChargePwr "The rate at which this High Voltage Energy Storage Pack instance can currently receive energy from a regenerative or recharging system.
This parameter is for one of multiple packs in an HVESS. If there is only one pack in the system, the HVESS ...";
CM_ SG_ 2364760318 AvailableDisPwr "The rate at which this High Voltage Energy Storage Pack instance can currently provide energy for propulsion or other uses.
This parameter is for one of multiple packs in an HVESS. If there is only one pack in the system, the HVESS parameters ...";
CM_ BO_ 2364760062 "High Voltage Energy Storage Pack 10 Data 13
Data set 13 (electrical data) for High Voltage Energy Storage Pack 10.";
CM_ SG_ 2364760062 NomChargeCurLmt "The nominal current flow limit into the High Voltage Energy Storage Pack instance. This limit is a preferred boundary for normal operation.  Operating within this limit reduces negative impacts on battery life or battery health, but should not ...";
CM_ SG_ 2364760062 NomDisCurLmt "The nominal current flow limit out of the High Voltage Energy Storage Pack instance. This limit is a preferred boundary for normal operation.  Operating within this limit reduces negative impacts on battery life or battery health, but should not ...";
CM_ SG_ 2364760062 MaxCurChargeCurLmt "The maximum instantaneous current flow limit into this High Voltage Energy Storage Pack instance. This parameter is defined from the high voltage energy storage pack's point of view and should reflect the instantaneous capability of the pack.  The ...";
CM_ SG_ 2364760062 MaxCurDisCurLmt "The maximum instantaneous current flow limit out of this High Voltage Energy Storage Pack instance. This parameter is defined from the high voltage energy storage pack's point of view and should reflect the instantaneous capability of the pack.  The ...";
CM_ BO_ 2364759806 "High Voltage Energy Storage Pack 10 Data 12
Data set 12 (electrical data) for High Voltage Energy Storage Pack 10.";
CM_ SG_ 2364759806 Cur "The current in or out of this High Voltage Energy Storage Pack instance. This parameter should be synchronized with SPN 22558 (HVESP10 Voltage Level (Extended Range)) such that a realized power value can be calculated. This parameter is defined from ...";
CM_ SG_ 2364759806 Lvl "The voltage level of this High Voltage Energy Storage Pack instance. This parameter should be synchronized with SPN 22559 (HVESP10 Current (Extended Range)) such that a realized power value can be calculated. If the HVES component physically ...";
CM_ SG_ 2364759806 AvailableChargePwr "The rate at which this High Voltage Energy Storage Pack instance can currently receive energy from a regenerative or recharging system.
This parameter is for one of multiple packs in an HVESS. If there is only one pack in the system, the HVESS ...";
CM_ SG_ 2364759806 AvailableDisPwr "The rate at which this High Voltage Energy Storage Pack instance can currently provide energy for propulsion or other uses.
This parameter is for one of multiple packs in an HVESS. If there is only one pack in the system, the HVESS parameters ...";
CM_ BO_ 2364759550 "High Voltage Energy Storage Pack 9 Data 13
Data set 13 (electrical data) for High Voltage Energy Storage Pack 9.";
CM_ SG_ 2364759550 NomChargeCurLmt "The nominal current flow limit into the High Voltage Energy Storage Pack instance. This limit is a preferred boundary for normal operation.  Operating within this limit reduces negative impacts on battery life or battery health, but should not ...";
CM_ SG_ 2364759550 NomDisCurLmt "The nominal current flow limit out of the High Voltage Energy Storage Pack instance. This limit is a preferred boundary for normal operation.  Operating within this limit reduces negative impacts on battery life or battery health, but should not ...";
CM_ SG_ 2364759550 MaxCurChargeCurLmt "The maximum instantaneous current flow limit into this High Voltage Energy Storage Pack instance. This parameter is defined from the high voltage energy storage pack's point of view and should reflect the instantaneous capability of the pack.  The ...";
CM_ SG_ 2364759550 MaxCurDisCurLmt "The maximum instantaneous current flow limit out of this High Voltage Energy Storage Pack instance. This parameter is defined from the high voltage energy storage pack's point of view and should reflect the instantaneous capability of the pack.  The ...";
CM_ BO_ 2364759294 "High Voltage Energy Storage Pack 9 Data 12
Data set 12 (electrical data) for High Voltage Energy Storage Pack 9.";
CM_ SG_ 2364759294 Cur "The current in or out of this High Voltage Energy Storage Pack instance. This parameter should be synchronized with SPN 22536 (HVESP9 Voltage Level (Extended Range)) such that a realized power value can be calculated. This parameter is defined from ...";
CM_ SG_ 2364759294 Lvl "The voltage level of this High Voltage Energy Storage Pack instance. This parameter should be synchronized with SPN 22537 (HVESP9 Current (Extended Range)) such that a realized power value can be calculated. If the HVES component physically contains ...";
CM_ SG_ 2364759294 AvailableChargePwr "The rate at which this High Voltage Energy Storage Pack instance can currently receive energy from a regenerative or recharging system.
This parameter is for one of multiple packs in an HVESS. If there is only one pack in the system, the HVESS ...";
CM_ SG_ 2364759294 AvailableDisPwr "The rate at which this High Voltage Energy Storage Pack instance can currently provide energy for propulsion or other uses.
This parameter is for one of multiple packs in an HVESS. If there is only one pack in the system, the HVESS parameters ...";
CM_ BO_ 2364759038 "High Voltage Energy Storage Pack 8 Data 13
Data set 13 (electrical data) for High Voltage Energy Storage Pack 8.";
CM_ SG_ 2364759038 NomChargeCurLmt "The nominal current flow limit into the High Voltage Energy Storage Pack instance. This limit is a preferred boundary for normal operation.  Operating within this limit reduces negative impacts on battery life or battery health, but should not ...";
CM_ SG_ 2364759038 NomDisCurLmt "The nominal current flow limit out of the High Voltage Energy Storage Pack instance. This limit is a preferred boundary for normal operation.  Operating within this limit reduces negative impacts on battery life or battery health, but should not ...";
CM_ SG_ 2364759038 MaxCurChargeCurLmt "The maximum instantaneous current flow limit into this High Voltage Energy Storage Pack instance. This parameter is defined from the high voltage energy storage pack's point of view and should reflect the instantaneous capability of the pack.  The ...";
CM_ SG_ 2364759038 MaxCurDisCurLmt "The maximum instantaneous current flow limit out of this High Voltage Energy Storage Pack instance. This parameter is defined from the high voltage energy storage pack's point of view and should reflect the instantaneous capability of the pack.  The ...";
CM_ BO_ 2364758782 "High Voltage Energy Storage Pack 8 Data 12
Data set 12 (electrical data) for High Voltage Energy Storage Pack 8.";
CM_ SG_ 2364758782 Cur "The current in or out of this High Voltage Energy Storage Pack instance. This parameter should be synchronized with SPN 22514 (HVESP8 Voltage Level (Extended Range)) such that a realized power value can be calculated. This parameter is defined from ...";
CM_ SG_ 2364758782 Lvl "The voltage level of this High Voltage Energy Storage Pack instance. This parameter should be synchronized with SPN 22515 (HVESP8 Current (Extended Range)) such that a realized power value can be calculated. If the HVES component physically contains ...";
CM_ SG_ 2364758782 AvailableChargePwr "The rate at which this High Voltage Energy Storage Pack instance can currently receive energy from a regenerative or recharging system.
This parameter is for one of multiple packs in an HVESS. If there is only one pack in the system, the HVESS ...";
CM_ SG_ 2364758782 AvailableDisPwr "The rate at which this High Voltage Energy Storage Pack instance can currently provide energy for propulsion or other uses.
This parameter is for one of multiple packs in an HVESS. If there is only one pack in the system, the HVESS parameters ...";
CM_ BO_ 2364758526 "High Voltage Energy Storage Pack 7 Data 13
Data set 13 (electrical data) for High Voltage Energy Storage Pack 7.";
CM_ SG_ 2364758526 NomChargeCurLmt "The nominal current flow limit into the High Voltage Energy Storage Pack instance. This limit is a preferred boundary for normal operation.  Operating within this limit reduces negative impacts on battery life or battery health, but should not ...";
CM_ SG_ 2364758526 NomDisCurLmt "The nominal current flow limit out of the High Voltage Energy Storage Pack instance. This limit is a preferred boundary for normal operation.  Operating within this limit reduces negative impacts on battery life or battery health, but should not ...";
CM_ SG_ 2364758526 MaxCurChargeCurLmt "The maximum instantaneous current flow limit into this High Voltage Energy Storage Pack instance. This parameter is defined from the high voltage energy storage pack's point of view and should reflect the instantaneous capability of the pack.  The ...";
CM_ SG_ 2364758526 MaxCurDisCurLmt "The maximum instantaneous current flow limit out of this High Voltage Energy Storage Pack instance. This parameter is defined from the high voltage energy storage pack's point of view and should reflect the instantaneous capability of the pack.  The ...";
BA_DEF_ SG_  "GenSigInactiveValue" INT 0 0;
BA_DEF_ SG_  "SigType" ENUM  "Default","Range","RangeSigned","ASCII","Discrete","Control","ReferencePGN","DTC","StringDelimiter","StringLength","StringLengthControl","MessageCounter","MessageChecksum";
BA_DEF_ SG_  "GenSigStartValue" INT 0 2147483647;
BA_DEF_ SG_  "GenSigSendType" ENUM  "Cyclic","OnWrite","OnWriteWithRepetition","OnChange","OnChangeWithRepetition","IfActive","IfActiveWithRepetition","NoSigSendType";
BA_DEF_ SG_  "GenSigILSupport" ENUM  "No","Yes";
BA_DEF_ SG_  "SPN" INT 0 524287;
BA_DEF_ BO_  "J1939CPgSendTimeout" INT -1 3600000;
BA_DEF_ BO_  "J1939CPgTOS" INT 0 7;
BA_DEF_ BO_  "J1939PgAppearanceOnBus" ENUM  "Default","CAN_Extended","CANFD_Extended";
BA_DEF_ BO_  "FsJ1939UseCrcAndCounter" STRING ;
BA_DEF_ BO_  "TpJ1939VarDlc" ENUM  "No","Yes";
BA_DEF_ BO_  "GenMsgNrOfRepetition" INT 0 1000000;
BA_DEF_ BO_  "GenMsgCycleTimeFast" INT 0 3600000;
BA_DEF_ BO_  "GenMsgFastOnStart" INT 0 100000;
BA_DEF_ BO_  "GenMsgStartDelayTime" INT 0 100000;
BA_DEF_ BO_  "GenMsgILSupport" ENUM  "No","Yes";
BA_DEF_ BO_  "GenMsgDelayTime" INT 0 1000;
BA_DEF_ BO_  "GenMsgRequestable" INT 0 1;
BA_DEF_ BO_  "GenMsgSendType" ENUM  "cyclic","NotUsed","NotUsed","NotUsed","NotUsed","NotUsed","NotUsed","IfActive","noMsgSendType";
BA_DEF_ BO_  "VFrameFormat" ENUM  "StandardCAN","ExtendedCAN","reserved","J1939PG","reserved","reserved","reserved","reserved","reserved","reserved","reserved","reserved","reserved","reserved","StandardCAN_FD","ExtendedCAN_FD";
BA_DEF_ BO_  "SingleFrame" INT 0 1;
BA_DEF_ BO_  "GenMsgCycleTime" INT 0 3600000;
BA_DEF_ SG_  "SystemSignalLongSymbol" STRING ;
BA_DEF_DEF_  "GenSigInactiveValue" 0;
BA_DEF_DEF_  "SigType" "Default";
BA_DEF_DEF_  "GenSigStartValue" 0;
BA_DEF_DEF_  "GenSigSendType" "NoSigSendType";
BA_DEF_DEF_  "GenSigILSupport" "Yes";
BA_DEF_DEF_  "SPN" 0;
BA_DEF_DEF_  "J1939CPgSendTimeout" -1;
BA_DEF_DEF_  "J1939CPgTOS" 2;
BA_DEF_DEF_  "J1939PgAppearanceOnBus" "Default";
BA_DEF_DEF_  "FsJ1939UseCrcAndCounter" "";
BA_DEF_DEF_  "TpJ1939VarDlc" "No";
BA_DEF_DEF_  "GenMsgNrOfRepetition" 0;
BA_DEF_DEF_  "GenMsgCycleTimeFast" 0;
BA_DEF_DEF_  "GenMsgFastOnStart" 0;
BA_DEF_DEF_  "GenMsgStartDelayTime" 0;
BA_DEF_DEF_  "GenMsgILSupport" "Yes";
BA_DEF_DEF_  "GenMsgDelayTime" 0;
BA_DEF_DEF_  "GenMsgRequestable" 1;
BA_DEF_DEF_  "GenMsgSendType" "noMsgSendType";
BA_DEF_DEF_  "VFrameFormat" "J1939PG";
BA_DEF_DEF_  "SingleFrame" 1;
BA_DEF_DEF_  "GenMsgCycleTime" 0;
BA_DEF_DEF_  "SystemSignalLongSymbol" "";
BA_ "GenMsgSendType" BO_ 2365205758 0;
BA_ "GenMsgCycleTime" BO_ 2365205758 100;
BA_ "GenMsgSendType" BO_ 2365205502 0;
BA_ "GenMsgCycleTime" BO_ 2365205502 100;
BA_ "GenMsgSendType" BO_ 2365205246 0;
BA_ "GenMsgCycleTime" BO_ 2365205246 100;
BA_ "GenMsgSendType" BO_ 2365204990 0;
BA_ "GenMsgCycleTime" BO_ 2365204990 100;
BA_ "GenMsgSendType" BO_ 2365204734 0;
BA_ "GenMsgCycleTime" BO_ 2365204734 100;
BA_ "GenMsgSendType" BO_ 2365204478 0;
BA_ "GenMsgCycleTime" BO_ 2365204478 100;
BA_ "GenMsgSendType" BO_ 2365204222 0;
BA_ "GenMsgCycleTime" BO_ 2365204222 100;
BA_ "GenMsgSendType" BO_ 2365203966 0;
BA_ "GenMsgCycleTime" BO_ 2365203966 100;
BA_ "GenMsgSendType" BO_ 2365203710 0;
BA_ "GenMsgCycleTime" BO_ 2365203710 100;
BA_ "TpJ1939VarDlc" BO_ 2566530046 1;
BA_ "GenMsgDelayTime" BO_ 2566530046 1000;
BA_ "GenMsgSendType" BO_ 2566530046 0;
BA_ "GenMsgCycleTime" BO_ 2566530046 10000;
BA_ "GenMsgSendType" BO_ 2566529790 0;
BA_ "GenMsgCycleTime" BO_ 2566529790 1000;
BA_ "GenMsgDelayTime" BO_ 2566529534 100;
BA_ "GenMsgSendType" BO_ 2566529534 0;
BA_ "GenMsgCycleTime" BO_ 2566529534 10000;
BA_ "FsJ1939UseCrcAndCounter" BO_ 2365202174 "Aa";
BA_ "GenMsgDelayTime" BO_ 2365202174 100;
BA_ "GenMsgSendType" BO_ 2365202174 0;
BA_ "GenMsgCycleTime" BO_ 2365202174 1000;
BA_ "FsJ1939UseCrcAndCounter" BO_ 2365201918 "Aa";
BA_ "GenMsgDelayTime" BO_ 2365201918 100;
BA_ "GenMsgSendType" BO_ 2365201918 0;
BA_ "GenMsgCycleTime" BO_ 2365201918 1000;
BA_ "GenMsgSendType" BO_ 2432310526 0;
BA_ "GenMsgCycleTime" BO_ 2432310526 100;
BA_ "GenMsgSendType" BO_ 2432310270 0;
BA_ "GenMsgCycleTime" BO_ 2432310270 100;
BA_ "GenMsgSendType" BO_ 2432310014 0;
BA_ "GenMsgCycleTime" BO_ 2432310014 100;
BA_ "GenMsgSendType" BO_ 2365200894 0;
BA_ "GenMsgCycleTime" BO_ 2365200894 100;
BA_ "GenMsgSendType" BO_ 2365200638 0;
BA_ "GenMsgCycleTime" BO_ 2365200638 100;
BA_ "GenMsgSendType" BO_ 2365200382 0;
BA_ "GenMsgCycleTime" BO_ 2365200382 100;
BA_ "GenMsgSendType" BO_ 2365200126 0;
BA_ "GenMsgCycleTime" BO_ 2365200126 100;
BA_ "GenMsgSendType" BO_ 2499417598 0;
BA_ "GenMsgCycleTime" BO_ 2499417598 100;
BA_ "TpJ1939VarDlc" BO_ 2566525694 1;
BA_ "GenMsgDelayTime" BO_ 2566525694 1000;
BA_ "GenMsgSendType" BO_ 2566525694 0;
BA_ "GenMsgCycleTime" BO_ 2566525694 10000;
BA_ "GenMsgSendType" BO_ 2566524926 0;
BA_ "GenMsgCycleTime" BO_ 2566524926 1000;
BA_ "GenMsgSendType" BO_ 2566524670 0;
BA_ "GenMsgCycleTime" BO_ 2566524670 1000;
BA_ "GenMsgSendType" BO_ 2566524414 0;
BA_ "GenMsgCycleTime" BO_ 2566524414 1000;
BA_ "GenMsgSendType" BO_ 2566524158 0;
BA_ "GenMsgCycleTime" BO_ 2566524158 1000;
BA_ "GenMsgSendType" BO_ 2566523902 0;
BA_ "GenMsgCycleTime" BO_ 2566523902 1000;
BA_ "GenMsgSendType" BO_ 2566523646 0;
BA_ "GenMsgCycleTime" BO_ 2566523646 1000;
BA_ "GenMsgSendType" BO_ 2566091006 0;
BA_ "GenMsgCycleTime" BO_ 2566091006 100;
BA_ "GenMsgSendType" BO_ 2566090750 0;
BA_ "GenMsgCycleTime" BO_ 2566090750 100;
BA_ "GenMsgSendType" BO_ 2566090494 0;
BA_ "GenMsgCycleTime" BO_ 2566090494 100;
BA_ "GenMsgSendType" BO_ 2566090238 0;
BA_ "GenMsgCycleTime" BO_ 2566090238 100;
BA_ "GenMsgSendType" BO_ 2566089982 0;
BA_ "GenMsgCycleTime" BO_ 2566089982 100;
BA_ "GenMsgSendType" BO_ 2566089726 0;
BA_ "GenMsgCycleTime" BO_ 2566089726 100;
BA_ "GenMsgSendType" BO_ 2566089470 0;
BA_ "GenMsgCycleTime" BO_ 2566089470 100;
BA_ "GenMsgSendType" BO_ 2566089214 0;
BA_ "GenMsgCycleTime" BO_ 2566089214 100;
BA_ "GenMsgSendType" BO_ 2566088958 0;
BA_ "GenMsgCycleTime" BO_ 2566088958 100;
BA_ "GenMsgSendType" BO_ 2566088702 0;
BA_ "GenMsgCycleTime" BO_ 2566088702 100;
BA_ "GenMsgSendType" BO_ 2566088446 0;
BA_ "GenMsgCycleTime" BO_ 2566088446 100;
BA_ "GenMsgSendType" BO_ 2566088190 0;
BA_ "GenMsgCycleTime" BO_ 2566088190 100;
BA_ "GenMsgSendType" BO_ 2364761342 0;
BA_ "GenMsgCycleTime" BO_ 2364761342 10;
BA_ "GenMsgSendType" BO_ 2364761086 0;
BA_ "GenMsgCycleTime" BO_ 2364761086 20;
BA_ "GenMsgSendType" BO_ 2364760830 0;
BA_ "GenMsgCycleTime" BO_ 2364760830 20;
BA_ "GenMsgSendType" BO_ 2364760574 0;
BA_ "GenMsgCycleTime" BO_ 2364760574 20;
BA_ "GenMsgSendType" BO_ 2364760318 0;
BA_ "GenMsgCycleTime" BO_ 2364760318 20;
BA_ "GenMsgSendType" BO_ 2364760062 0;
BA_ "GenMsgCycleTime" BO_ 2364760062 20;
BA_ "GenMsgSendType" BO_ 2364759806 0;
BA_ "GenMsgCycleTime" BO_ 2364759806 20;
BA_ "GenMsgSendType" BO_ 2364759550 0;
BA_ "GenMsgCycleTime" BO_ 2364759550 20;
BA_ "GenMsgSendType" BO_ 2364759294 0;
BA_ "GenMsgCycleTime" BO_ 2364759294 20;
BA_ "GenMsgSendType" BO_ 2364759038 0;
BA_ "GenMsgCycleTime" BO_ 2364759038 20;
BA_ "GenMsgSendType" BO_ 2364758782 0;
BA_ "GenMsgCycleTime" BO_ 2364758782 20;
BA_ "GenMsgSendType" BO_ 2364758526 0;
BA_ "GenMsgCycleTime" BO_ 2364758526 20;
BA_ "SigType" SG_ 2365205758 HVInternalContactor8St22489 4;
BA_ "SPN" SG_ 2365205758 HVInternalContactor8St22489 22489;
BA_ "SigType" SG_ 2365205758 HVInternalContactor7St22488 4;
BA_ "SPN" SG_ 2365205758 HVInternalContactor7St22488 22488;
BA_ "SigType" SG_ 2365205758 HVInternalContactor6St22487 4;
BA_ "SPN" SG_ 2365205758 HVInternalContactor6St22487 22487;
BA_ "SigType" SG_ 2365205758 HVInternalContactor5St22486 4;
BA_ "SPN" SG_ 2365205758 HVInternalContactor5St22486 22486;
BA_ "SigType" SG_ 2365205758 HVInternalContactor4St22485 4;
BA_ "SPN" SG_ 2365205758 HVInternalContactor4St22485 22485;
BA_ "SigType" SG_ 2365205758 HVInternalContactor3St22484 4;
BA_ "SPN" SG_ 2365205758 HVInternalContactor3St22484 22484;
BA_ "SigType" SG_ 2365205758 HVInternalContactor2St22483 4;
BA_ "SPN" SG_ 2365205758 HVInternalContactor2St22483 22483;
BA_ "SigType" SG_ 2365205758 HVInternalContactor1St22482 4;
BA_ "SPN" SG_ 2365205758 HVInternalContactor1St22482 22482;
BA_ "SigType" SG_ 2365205758 HVInternalContactor8St 4;
BA_ "SPN" SG_ 2365205758 HVInternalContactor8St 22481;
BA_ "SigType" SG_ 2365205758 HVInternalContactor7St 4;
BA_ "SPN" SG_ 2365205758 HVInternalContactor7St 22480;
BA_ "SigType" SG_ 2365205758 HVInternalContactor6St 4;
BA_ "SPN" SG_ 2365205758 HVInternalContactor6St 22479;
BA_ "SigType" SG_ 2365205758 HVInternalContactor5St 4;
BA_ "SPN" SG_ 2365205758 HVInternalContactor5St 22478;
BA_ "SigType" SG_ 2365205758 HVInternalContactor4St 4;
BA_ "SPN" SG_ 2365205758 HVInternalContactor4St 22477;
BA_ "SigType" SG_ 2365205758 HVInternalContactor3St 4;
BA_ "SPN" SG_ 2365205758 HVInternalContactor3St 22476;
BA_ "SigType" SG_ 2365205758 HVInternalContactor2St 4;
BA_ "SPN" SG_ 2365205758 HVInternalContactor2St 22475;
BA_ "SigType" SG_ 2365205758 HVInternalContactor1St 4;
BA_ "SPN" SG_ 2365205758 HVInternalContactor1St 22474;
BA_ "SigType" SG_ 2365205502 HVInternalContactor8St22467 4;
BA_ "SPN" SG_ 2365205502 HVInternalContactor8St22467 22467;
BA_ "SigType" SG_ 2365205502 HVInternalContactor7St22466 4;
BA_ "SPN" SG_ 2365205502 HVInternalContactor7St22466 22466;
BA_ "SigType" SG_ 2365205502 HVInternalContactor6St22465 4;
BA_ "SPN" SG_ 2365205502 HVInternalContactor6St22465 22465;
BA_ "SigType" SG_ 2365205502 HVInternalContactor5St22464 4;
BA_ "SPN" SG_ 2365205502 HVInternalContactor5St22464 22464;
BA_ "SigType" SG_ 2365205502 HVInternalContactor4St22463 4;
BA_ "SPN" SG_ 2365205502 HVInternalContactor4St22463 22463;
BA_ "SigType" SG_ 2365205502 HVInternalContactor3St22462 4;
BA_ "SPN" SG_ 2365205502 HVInternalContactor3St22462 22462;
BA_ "SigType" SG_ 2365205502 HVInternalContactor2St22461 4;
BA_ "SPN" SG_ 2365205502 HVInternalContactor2St22461 22461;
BA_ "SigType" SG_ 2365205502 HVInternalContactor1St22460 4;
BA_ "SPN" SG_ 2365205502 HVInternalContactor1St22460 22460;
BA_ "SigType" SG_ 2365205502 HVInternalContactor8St 4;
BA_ "SPN" SG_ 2365205502 HVInternalContactor8St 22459;
BA_ "SigType" SG_ 2365205502 HVInternalContactor7St 4;
BA_ "SPN" SG_ 2365205502 HVInternalContactor7St 22458;
BA_ "SigType" SG_ 2365205502 HVInternalContactor6St 4;
BA_ "SPN" SG_ 2365205502 HVInternalContactor6St 22457;
BA_ "SigType" SG_ 2365205502 HVInternalContactor5St 4;
BA_ "SPN" SG_ 2365205502 HVInternalContactor5St 22456;
BA_ "SigType" SG_ 2365205502 HVInternalContactor4St 4;
BA_ "SPN" SG_ 2365205502 HVInternalContactor4St 22455;
BA_ "SigType" SG_ 2365205502 HVInternalContactor3St 4;
BA_ "SPN" SG_ 2365205502 HVInternalContactor3St 22454;
BA_ "SigType" SG_ 2365205502 HVInternalContactor2St 4;
BA_ "SPN" SG_ 2365205502 HVInternalContactor2St 22453;
BA_ "SigType" SG_ 2365205502 HVInternalContactor1St 4;
BA_ "SPN" SG_ 2365205502 HVInternalContactor1St 22452;
BA_ "SigType" SG_ 2365205246 HVInternalContactor8St22445 4;
BA_ "SPN" SG_ 2365205246 HVInternalContactor8St22445 22445;
BA_ "SigType" SG_ 2365205246 HVInternalContactor7St22444 4;
BA_ "SPN" SG_ 2365205246 HVInternalContactor7St22444 22444;
BA_ "SigType" SG_ 2365205246 HVInternalContactor6St22443 4;
BA_ "SPN" SG_ 2365205246 HVInternalContactor6St22443 22443;
BA_ "SigType" SG_ 2365205246 HVInternalContactor5St22442 4;
BA_ "SPN" SG_ 2365205246 HVInternalContactor5St22442 22442;
BA_ "SigType" SG_ 2365205246 HVInternalContactor4St22441 4;
BA_ "SPN" SG_ 2365205246 HVInternalContactor4St22441 22441;
BA_ "SigType" SG_ 2365205246 HVInternalContactor3St22440 4;
BA_ "SPN" SG_ 2365205246 HVInternalContactor3St22440 22440;
BA_ "SigType" SG_ 2365205246 HVInternalContactor2St22439 4;
BA_ "SPN" SG_ 2365205246 HVInternalContactor2St22439 22439;
BA_ "SigType" SG_ 2365205246 HVInternalContactor1St22438 4;
BA_ "SPN" SG_ 2365205246 HVInternalContactor1St22438 22438;
BA_ "SigType" SG_ 2365205246 HVInternalContactor8St 4;
BA_ "SPN" SG_ 2365205246 HVInternalContactor8St 22437;
BA_ "SigType" SG_ 2365205246 HVInternalContactor7St 4;
BA_ "SPN" SG_ 2365205246 HVInternalContactor7St 22436;
BA_ "SigType" SG_ 2365205246 HVInternalContactor6St 4;
BA_ "SPN" SG_ 2365205246 HVInternalContactor6St 22435;
BA_ "SigType" SG_ 2365205246 HVInternalContactor5St 4;
BA_ "SPN" SG_ 2365205246 HVInternalContactor5St 22434;
BA_ "SigType" SG_ 2365205246 HVInternalContactor4St 4;
BA_ "SPN" SG_ 2365205246 HVInternalContactor4St 22433;
BA_ "SigType" SG_ 2365205246 HVInternalContactor3St 4;
BA_ "SPN" SG_ 2365205246 HVInternalContactor3St 22432;
BA_ "SigType" SG_ 2365205246 HVInternalContactor2St 4;
BA_ "SPN" SG_ 2365205246 HVInternalContactor2St 22431;
BA_ "SigType" SG_ 2365205246 HVInternalContactor1St 4;
BA_ "SPN" SG_ 2365205246 HVInternalContactor1St 22430;
BA_ "SigType" SG_ 2365204990 HVInternalContactor8St22423 4;
BA_ "SPN" SG_ 2365204990 HVInternalContactor8St22423 22423;
BA_ "SigType" SG_ 2365204990 HVInternalContactor7St22422 4;
BA_ "SPN" SG_ 2365204990 HVInternalContactor7St22422 22422;
BA_ "SigType" SG_ 2365204990 HVInternalContactor6St22421 4;
BA_ "SPN" SG_ 2365204990 HVInternalContactor6St22421 22421;
BA_ "SigType" SG_ 2365204990 HVInternalContactor5St22420 4;
BA_ "SPN" SG_ 2365204990 HVInternalContactor5St22420 22420;
BA_ "SigType" SG_ 2365204990 HVInternalContactor4St22419 4;
BA_ "SPN" SG_ 2365204990 HVInternalContactor4St22419 22419;
BA_ "SigType" SG_ 2365204990 HVInternalContactor3St22418 4;
BA_ "SPN" SG_ 2365204990 HVInternalContactor3St22418 22418;
BA_ "SigType" SG_ 2365204990 HVInternalContactor2St22417 4;
BA_ "SPN" SG_ 2365204990 HVInternalContactor2St22417 22417;
BA_ "SigType" SG_ 2365204990 HVInternalContactor1St22416 4;
BA_ "SPN" SG_ 2365204990 HVInternalContactor1St22416 22416;
BA_ "SigType" SG_ 2365204990 HVInternalContactor8St 4;
BA_ "SPN" SG_ 2365204990 HVInternalContactor8St 22415;
BA_ "SigType" SG_ 2365204990 HVInternalContactor7St 4;
BA_ "SPN" SG_ 2365204990 HVInternalContactor7St 22414;
BA_ "SigType" SG_ 2365204990 HVInternalContactor6St 4;
BA_ "SPN" SG_ 2365204990 HVInternalContactor6St 22413;
BA_ "SigType" SG_ 2365204990 HVInternalContactor5St 4;
BA_ "SPN" SG_ 2365204990 HVInternalContactor5St 22412;
BA_ "SigType" SG_ 2365204990 HVInternalContactor4St 4;
BA_ "SPN" SG_ 2365204990 HVInternalContactor4St 22411;
BA_ "SigType" SG_ 2365204990 HVInternalContactor3St 4;
BA_ "SPN" SG_ 2365204990 HVInternalContactor3St 22410;
BA_ "SigType" SG_ 2365204990 HVInternalContactor2St 4;
BA_ "SPN" SG_ 2365204990 HVInternalContactor2St 22409;
BA_ "SigType" SG_ 2365204990 HVInternalContactor1St 4;
BA_ "SPN" SG_ 2365204990 HVInternalContactor1St 22408;
BA_ "SigType" SG_ 2365204734 HVInternalContactor8St22401 4;
BA_ "SPN" SG_ 2365204734 HVInternalContactor8St22401 22401;
BA_ "SigType" SG_ 2365204734 HVInternalContactor7St22400 4;
BA_ "SPN" SG_ 2365204734 HVInternalContactor7St22400 22400;
BA_ "SigType" SG_ 2365204734 HVInternalContactor6St22399 4;
BA_ "SPN" SG_ 2365204734 HVInternalContactor6St22399 22399;
BA_ "SigType" SG_ 2365204734 HVInternalContactor5St22398 4;
BA_ "SPN" SG_ 2365204734 HVInternalContactor5St22398 22398;
BA_ "SigType" SG_ 2365204734 HVInternalContactor4St22397 4;
BA_ "SPN" SG_ 2365204734 HVInternalContactor4St22397 22397;
BA_ "SigType" SG_ 2365204734 HVInternalContactor3St22396 4;
BA_ "SPN" SG_ 2365204734 HVInternalContactor3St22396 22396;
BA_ "SigType" SG_ 2365204734 HVInternalContactor2St22395 4;
BA_ "SPN" SG_ 2365204734 HVInternalContactor2St22395 22395;
BA_ "SigType" SG_ 2365204734 HVInternalContactor1St22394 4;
BA_ "SPN" SG_ 2365204734 HVInternalContactor1St22394 22394;
BA_ "SigType" SG_ 2365204734 HVInternalContactor8St 4;
BA_ "SPN" SG_ 2365204734 HVInternalContactor8St 22393;
BA_ "SigType" SG_ 2365204734 HVInternalContactor7St 4;
BA_ "SPN" SG_ 2365204734 HVInternalContactor7St 22392;
BA_ "SigType" SG_ 2365204734 HVInternalContactor6St 4;
BA_ "SPN" SG_ 2365204734 HVInternalContactor6St 22391;
BA_ "SigType" SG_ 2365204734 HVInternalContactor5St 4;
BA_ "SPN" SG_ 2365204734 HVInternalContactor5St 22390;
BA_ "SigType" SG_ 2365204734 HVInternalContactor4St 4;
BA_ "SPN" SG_ 2365204734 HVInternalContactor4St 22389;
BA_ "SigType" SG_ 2365204734 HVInternalContactor3St 4;
BA_ "SPN" SG_ 2365204734 HVInternalContactor3St 22388;
BA_ "SigType" SG_ 2365204734 HVInternalContactor2St 4;
BA_ "SPN" SG_ 2365204734 HVInternalContactor2St 22387;
BA_ "SigType" SG_ 2365204734 HVInternalContactor1St 4;
BA_ "SPN" SG_ 2365204734 HVInternalContactor1St 22386;
BA_ "SigType" SG_ 2365204478 HVInternalContactor8St22379 4;
BA_ "SPN" SG_ 2365204478 HVInternalContactor8St22379 22379;
BA_ "SigType" SG_ 2365204478 HVInternalContactor7St22378 4;
BA_ "SPN" SG_ 2365204478 HVInternalContactor7St22378 22378;
BA_ "SigType" SG_ 2365204478 HVInternalContactor6St22377 4;
BA_ "SPN" SG_ 2365204478 HVInternalContactor6St22377 22377;
BA_ "SigType" SG_ 2365204478 HVInternalContactor5St22376 4;
BA_ "SPN" SG_ 2365204478 HVInternalContactor5St22376 22376;
BA_ "SigType" SG_ 2365204478 HVInternalContactor4St22375 4;
BA_ "SPN" SG_ 2365204478 HVInternalContactor4St22375 22375;
BA_ "SigType" SG_ 2365204478 HVInternalContactor3St22374 4;
BA_ "SPN" SG_ 2365204478 HVInternalContactor3St22374 22374;
BA_ "SigType" SG_ 2365204478 HVInternalContactor2St22373 4;
BA_ "SPN" SG_ 2365204478 HVInternalContactor2St22373 22373;
BA_ "SigType" SG_ 2365204478 HVInternalContactor1St22372 4;
BA_ "SPN" SG_ 2365204478 HVInternalContactor1St22372 22372;
BA_ "SigType" SG_ 2365204478 HVInternalContactor8St 4;
BA_ "SPN" SG_ 2365204478 HVInternalContactor8St 22371;
BA_ "SigType" SG_ 2365204478 HVInternalContactor7St 4;
BA_ "SPN" SG_ 2365204478 HVInternalContactor7St 22370;
BA_ "SigType" SG_ 2365204478 HVInternalContactor6St 4;
BA_ "SPN" SG_ 2365204478 HVInternalContactor6St 22369;
BA_ "SigType" SG_ 2365204478 HVInternalContactor5St 4;
BA_ "SPN" SG_ 2365204478 HVInternalContactor5St 22368;
BA_ "SigType" SG_ 2365204478 HVInternalContactor4St 4;
BA_ "SPN" SG_ 2365204478 HVInternalContactor4St 22367;
BA_ "SigType" SG_ 2365204478 HVInternalContactor3St 4;
BA_ "SPN" SG_ 2365204478 HVInternalContactor3St 22366;
BA_ "SigType" SG_ 2365204478 HVInternalContactor2St 4;
BA_ "SPN" SG_ 2365204478 HVInternalContactor2St 22365;
BA_ "SigType" SG_ 2365204478 HVInternalContactor1St 4;
BA_ "SPN" SG_ 2365204478 HVInternalContactor1St 22364;
BA_ "SigType" SG_ 2365204222 BusV 1;
BA_ "SPN" SG_ 2365204222 BusV 22357;
BA_ "SigType" SG_ 2365204222 MaxCurChargeCurLmt 1;
BA_ "GenSigStartValue" SG_ 2365204222 MaxCurChargeCurLmt 32000;
BA_ "SPN" SG_ 2365204222 MaxCurChargeCurLmt 22356;
BA_ "SigType" SG_ 2365204222 MaxCurDisCurLmt 1;
BA_ "SPN" SG_ 2365204222 MaxCurDisCurLmt 22355;
BA_ "SigType" SG_ 2365203966 Cur 1;
BA_ "SPN" SG_ 2365203966 Cur 22351;
BA_ "SigType" SG_ 2365203966 Lvl 1;
BA_ "SPN" SG_ 2365203966 Lvl 22352;
BA_ "SigType" SG_ 2365203966 AvailableChargePwr 1;
BA_ "SPN" SG_ 2365203966 AvailableChargePwr 22354;
BA_ "SigType" SG_ 2365203966 AvailableDisPwr 1;
BA_ "SPN" SG_ 2365203966 AvailableDisPwr 22353;
BA_ "SigType" SG_ 2365203710 HVBusNegPreChargeRelaySt 4;
BA_ "SPN" SG_ 2365203710 HVBusNegPreChargeRelaySt 22820;
BA_ "SigType" SG_ 2365203710 HVBusPosPreChargeRelaySt 4;
BA_ "SPN" SG_ 2365203710 HVBusPosPreChargeRelaySt 22819;
BA_ "SigType" SG_ 2365203710 PwrHoldRelaySt 4;
BA_ "SPN" SG_ 2365203710 PwrHoldRelaySt 22818;
BA_ "SigType" SG_ 2365203710 ExposureInd 4;
BA_ "SPN" SG_ 2365203710 ExposureInd 22817;
BA_ "SigType" SG_ 2365203710 EstChargeTimeRem 1;
BA_ "SPN" SG_ 2365203710 EstChargeTimeRem 22349;
BA_ "SigType" SG_ 2365203710 EstDisTimeRem 1;
BA_ "SPN" SG_ 2365203710 EstDisTimeRem 22348;
BA_ "SigType" SG_ 2365203710 InCoolantPress 1;
BA_ "SPN" SG_ 2365203710 InCoolantPress 22350;
BA_ "SPN" SG_ 2566530046 TlrType 22633;
BA_ "SPN" SG_ 2566530046 VehSegment 22632;
BA_ "SPN" SG_ 2566530046 Rotation 22631;
BA_ "SPN" SG_ 2566530046 Id 22630;
BA_ "SPN" SG_ 2566530046 SPN22255 22629;
BA_ "SPN" SG_ 2566530046 AxleInstance 22628;
BA_ "SPN" SG_ 2566530046 NumOfAxleInstancesBeingReported 22627;
BA_ "SigType" SG_ 2566529790 EngInAirSnsr 1;
BA_ "SPN" SG_ 2566529790 EngInAirSnsr 22640;
BA_ "SigType" SG_ 2566529790 DPFPressSnsr 1;
BA_ "SPN" SG_ 2566529790 DPFPressSnsr 22639;
BA_ "SigType" SG_ 2566529790 EngOilSnsr 1;
BA_ "SPN" SG_ 2566529790 EngOilSnsr 22638;
BA_ "SigType" SG_ 2566529790 EngFilteredFuelSnsr 1;
BA_ "SPN" SG_ 2566529790 EngFilteredFuelSnsr 22637;
BA_ "SigType" SG_ 2566529790 EngEGRInPressSnsr 1;
BA_ "SPN" SG_ 2566529790 EngEGRInPressSnsr 22636;
BA_ "SigType" SG_ 2566529790 EngFuelDelPressSnsr 1;
BA_ "SPN" SG_ 2566529790 EngFuelDelPressSnsr 22635;
BA_ "SigType" SG_ 2566529790 EngCrankcasePressSnsr 1;
BA_ "SPN" SG_ 2566529790 EngCrankcasePressSnsr 22634;
BA_ "SigType" SG_ 2566529534 DepTime 1;
BA_ "SPN" SG_ 2566529534 DepTime 22706;
BA_ "SigType" SG_ 2566529534 FullChargeTimeRem 1;
BA_ "SPN" SG_ 2566529534 FullChargeTimeRem 22705;
BA_ "SigType" SG_ 2566529534 BulkChargeTimeRem 1;
BA_ "SPN" SG_ 2566529534 BulkChargeTimeRem 22704;
BA_ "SigType" SG_ 2566529534 FullChargingComplete 4;
BA_ "SPN" SG_ 2566529534 FullChargingComplete 22703;
BA_ "SigType" SG_ 2566529534 BulkChargingComplete 4;
BA_ "SPN" SG_ 2566529534 BulkChargingComplete 22702;
BA_ "SPN" SG_ 2566529534 ExID 22701;
BA_ "SigType" SG_ 2566529278 EnergyReq 1;
BA_ "SPN" SG_ 2566529278 EnergyReq 22700;
BA_ "SigType" SG_ 2566529278 EnergyCapacity 1;
BA_ "SPN" SG_ 2566529278 EnergyCapacity 22699;
BA_ "SigType" SG_ 2566529278 FullStOfCharge 1;
BA_ "SPN" SG_ 2566529278 FullStOfCharge 22698;
BA_ "SigType" SG_ 2566529278 BulkStOfCharge 1;
BA_ "SPN" SG_ 2566529278 BulkStOfCharge 22697;
BA_ "SPN" SG_ 2566529278 ExID 22696;
BA_ "SigType" SG_ 2633637886 TwoDEFDosingMode 1;
BA_ "SPN" SG_ 2633637886 TwoDEFDosingMode 22719;
BA_ "SigType" SG_ 2365202174 CRC 12;
BA_ "SPN" SG_ 2365202174 CRC 22788;
BA_ "SigType" SG_ 2365202174 Counter 11;
BA_ "SPN" SG_ 2365202174 Counter 22787;
BA_ "SigType" SG_ 2365202174 EmbeddedIntegritySupport 5;
BA_ "SPN" SG_ 2365202174 EmbeddedIntegritySupport 22786;
BA_ "SigType" SG_ 2365202174 HVBusInterface8NegContactorSt 4;
BA_ "SPN" SG_ 2365202174 HVBusInterface8NegContactorSt 21581;
BA_ "SigType" SG_ 2365202174 HVBusInterface8PosContactorSt 4;
BA_ "SPN" SG_ 2365202174 HVBusInterface8PosContactorSt 21580;
BA_ "SigType" SG_ 2365202174 HVBusInterface7NegContactorSt 4;
BA_ "SPN" SG_ 2365202174 HVBusInterface7NegContactorSt 21574;
BA_ "SigType" SG_ 2365202174 HVBusInterface7PosContactorSt 4;
BA_ "SPN" SG_ 2365202174 HVBusInterface7PosContactorSt 21573;
BA_ "SigType" SG_ 2365202174 HVBusInterface6NegContactorSt 4;
BA_ "SPN" SG_ 2365202174 HVBusInterface6NegContactorSt 21567;
BA_ "SigType" SG_ 2365202174 HVBusInterface6PosContactorSt 4;
BA_ "SPN" SG_ 2365202174 HVBusInterface6PosContactorSt 21566;
BA_ "SigType" SG_ 2365202174 HVBusInterface5NegContactorSt 4;
BA_ "SPN" SG_ 2365202174 HVBusInterface5NegContactorSt 21560;
BA_ "SigType" SG_ 2365202174 HVBusInterface5PosContactorSt 4;
BA_ "SPN" SG_ 2365202174 HVBusInterface5PosContactorSt 21559;
BA_ "SigType" SG_ 2365202174 HVBusInterface4NegContactorSt 4;
BA_ "SPN" SG_ 2365202174 HVBusInterface4NegContactorSt 21553;
BA_ "SigType" SG_ 2365202174 HVBusInterface4PosContactorSt 4;
BA_ "SPN" SG_ 2365202174 HVBusInterface4PosContactorSt 21552;
BA_ "SigType" SG_ 2365202174 HVBusInterface3NegContactorSt 4;
BA_ "SPN" SG_ 2365202174 HVBusInterface3NegContactorSt 21546;
BA_ "SigType" SG_ 2365202174 HVBusInterface3PosContactorSt 4;
BA_ "SPN" SG_ 2365202174 HVBusInterface3PosContactorSt 21545;
BA_ "SigType" SG_ 2365202174 HVBusInterface2NegContactorSt 4;
BA_ "SPN" SG_ 2365202174 HVBusInterface2NegContactorSt 21539;
BA_ "SigType" SG_ 2365202174 HVBusInterface2PosContactorSt 4;
BA_ "SPN" SG_ 2365202174 HVBusInterface2PosContactorSt 21538;
BA_ "SigType" SG_ 2365202174 HVBusInterface1NegContactorSt 4;
BA_ "SPN" SG_ 2365202174 HVBusInterface1NegContactorSt 21532;
BA_ "SigType" SG_ 2365202174 HVBusInterface1PosContactorSt 4;
BA_ "SPN" SG_ 2365202174 HVBusInterface1PosContactorSt 21531;
BA_ "SigType" SG_ 2365201918 CRC 12;
BA_ "SPN" SG_ 2365201918 CRC 22785;
BA_ "SigType" SG_ 2365201918 Counter 11;
BA_ "SPN" SG_ 2365201918 Counter 22784;
BA_ "SigType" SG_ 2365201918 EmbeddedIntegritySupport 5;
BA_ "SPN" SG_ 2365201918 EmbeddedIntegritySupport 22783;
BA_ "SigType" SG_ 2365201918 HVBusInterface8ConnectCmd 5;
BA_ "SPN" SG_ 2365201918 HVBusInterface8ConnectCmd 22782;
BA_ "SigType" SG_ 2365201918 HVBusInterface7ConnectCmd 5;
BA_ "SPN" SG_ 2365201918 HVBusInterface7ConnectCmd 22781;
BA_ "SigType" SG_ 2365201918 HVBusInterface6ConnectCmd 5;
BA_ "SPN" SG_ 2365201918 HVBusInterface6ConnectCmd 22780;
BA_ "SigType" SG_ 2365201918 HVBusInterface5ConnectCmd 5;
BA_ "SPN" SG_ 2365201918 HVBusInterface5ConnectCmd 22779;
BA_ "SigType" SG_ 2365201918 HVBusInterface4ConnectCmd 5;
BA_ "SPN" SG_ 2365201918 HVBusInterface4ConnectCmd 22778;
BA_ "SigType" SG_ 2365201918 HVBusInterface3ConnectCmd 5;
BA_ "SPN" SG_ 2365201918 HVBusInterface3ConnectCmd 22777;
BA_ "SigType" SG_ 2365201918 HVBusInterface2ConnectCmd 5;
BA_ "SPN" SG_ 2365201918 HVBusInterface2ConnectCmd 22776;
BA_ "SigType" SG_ 2365201918 HVBusInterface1ConnectCmd 5;
BA_ "SPN" SG_ 2365201918 HVBusInterface1ConnectCmd 22775;
BA_ "SPN" SG_ 2432310526 OpSt 22803;
BA_ "SPN" SG_ 2432310526 TempSt 22802;
BA_ "SPN" SG_ 2432310526 PreliminaryFMI 22801;
BA_ "SigType" SG_ 2432310526 DesPos 1;
BA_ "SPN" SG_ 2432310526 DesPos 22800;
BA_ "SigType" SG_ 2432310526 Pos 1;
BA_ "SPN" SG_ 2432310526 Pos 22799;
BA_ "SigType" SG_ 2432310526 Temp 1;
BA_ "SPN" SG_ 2432310526 Temp 22798;
BA_ "SPN" SG_ 2432310270 OpSt 22796;
BA_ "SPN" SG_ 2432310270 TempSt 22795;
BA_ "SPN" SG_ 2432310270 PreliminaryFMI 22794;
BA_ "SigType" SG_ 2432310270 DesPos 1;
BA_ "SPN" SG_ 2432310270 DesPos 22793;
BA_ "SigType" SG_ 2432310270 Pos 1;
BA_ "SPN" SG_ 2432310270 Pos 22792;
BA_ "SigType" SG_ 2432310270 Temp 1;
BA_ "SPN" SG_ 2432310270 Temp 22791;
BA_ "SigType" SG_ 2432310014 Cmd2 1;
BA_ "SPN" SG_ 2432310014 Cmd2 22790;
BA_ "SigType" SG_ 2432310014 Cmd1 1;
BA_ "SPN" SG_ 2432310014 Cmd1 22789;
BA_ "SigType" SG_ 2365200894 HVInternalCur8 1;
BA_ "SPN" SG_ 2365200894 HVInternalCur8 22930;
BA_ "SigType" SG_ 2365200894 HVInternalVLvl8 1;
BA_ "SPN" SG_ 2365200894 HVInternalVLvl8 22929;
BA_ "SigType" SG_ 2365200894 HVInternalCur7 1;
BA_ "SPN" SG_ 2365200894 HVInternalCur7 22928;
BA_ "SigType" SG_ 2365200894 HVInternalVLvl7 1;
BA_ "SPN" SG_ 2365200894 HVInternalVLvl7 22927;
BA_ "SigType" SG_ 2365200638 HVInternalCur6 1;
BA_ "SPN" SG_ 2365200638 HVInternalCur6 22926;
BA_ "SigType" SG_ 2365200638 HVInternalVLvl6 1;
BA_ "SPN" SG_ 2365200638 HVInternalVLvl6 22925;
BA_ "SigType" SG_ 2365200638 HVInternalCur5 1;
BA_ "SPN" SG_ 2365200638 HVInternalCur5 22924;
BA_ "SigType" SG_ 2365200638 HVInternalVLvl5 1;
BA_ "SPN" SG_ 2365200638 HVInternalVLvl5 22923;
BA_ "SigType" SG_ 2365200382 HVInternalCur4 1;
BA_ "SPN" SG_ 2365200382 HVInternalCur4 22922;
BA_ "SigType" SG_ 2365200382 HVInternalVLvl4 1;
BA_ "SPN" SG_ 2365200382 HVInternalVLvl4 22921;
BA_ "SigType" SG_ 2365200382 HVInternalCur3 1;
BA_ "SPN" SG_ 2365200382 HVInternalCur3 22920;
BA_ "SigType" SG_ 2365200382 HVInternalVLvl3 1;
BA_ "SPN" SG_ 2365200382 HVInternalVLvl3 22919;
BA_ "SigType" SG_ 2365200126 HVInternalCur2 1;
BA_ "SPN" SG_ 2365200126 HVInternalCur2 22918;
BA_ "SigType" SG_ 2365200126 HVInternalVLvl2 1;
BA_ "SPN" SG_ 2365200126 HVInternalVLvl2 22917;
BA_ "SigType" SG_ 2365200126 HVInternalCur1 1;
BA_ "SPN" SG_ 2365200126 HVInternalCur1 22916;
BA_ "SigType" SG_ 2365200126 HVInternalVLvl1 1;
BA_ "SPN" SG_ 2365200126 HVInternalVLvl1 22915;
BA_ "SigType" SG_ 2499417598 GenSimulatedUtilFreqDeactTimer 1;
BA_ "SPN" SG_ 2499417598 GenSimulatedUtilFreqDeactTimer 22224;
BA_ "SigType" SG_ 2499417598 GenSimulatedUtilFreqResult 1;
BA_ "SPN" SG_ 2499417598 GenSimulatedUtilFreqResult 22223;
BA_ "SigType" SG_ 2566526206 AvgTimeUntilCatColdStartTrkTemp 1;
BA_ "SPN" SG_ 2566526206 AvgTimeUntilCatColdStartTrkTemp 22246;
BA_ "SigType" SG_ 2566526206 AvgTimeUntilEngOutput 1;
BA_ "SPN" SG_ 2566526206 AvgTimeUntilEngOutput 22245;
BA_ "SigType" SG_ 2566526206 AvgEGRMassUntilFtpTemp 1;
BA_ "SPN" SG_ 2566526206 AvgEGRMassUntilFtpTemp 22244;
BA_ "SigType" SG_ 2566526206 AvgEGRMassAtEngOutput 1;
BA_ "SPN" SG_ 2566526206 AvgEGRMassAtEngOutput 22243;
BA_ "SigType" SG_ 2566526206 AvgEGRMassAtColdStart 1;
BA_ "SPN" SG_ 2566526206 AvgEGRMassAtColdStart 22242;
BA_ "SigType" SG_ 2566526206 EngEtilCatTempThld 1;
BA_ "SPN" SG_ 2566526206 EngEtilCatTempThld 22241;
BA_ "SigType" SG_ 2566526206 EngEtilColdStart 1;
BA_ "SPN" SG_ 2566526206 EngEtilColdStart 22240;
BA_ "SigType" SG_ 2566526206 CatEtilCatTempThld 1;
BA_ "SPN" SG_ 2566526206 CatEtilCatTempThld 22239;
BA_ "SigType" SG_ 2566526206 CatEtilEngOutput 1;
BA_ "SPN" SG_ 2566526206 CatEtilEngOutput 22238;
BA_ "SigType" SG_ 2566526206 CatEtilColdStart 1;
BA_ "SPN" SG_ 2566526206 CatEtilColdStart 22237;
BA_ "SigType" SG_ 2566525950 TimeUntilCatTempThld 1;
BA_ "SPN" SG_ 2566525950 TimeUntilCatTempThld 22236;
BA_ "SigType" SG_ 2566525950 TimeUntilEngOutput 1;
BA_ "SPN" SG_ 2566525950 TimeUntilEngOutput 22235;
BA_ "SigType" SG_ 2566525950 EgrMassUntilCatTempThld 1;
BA_ "SPN" SG_ 2566525950 EgrMassUntilCatTempThld 22234;
BA_ "SigType" SG_ 2566525950 EgrMassUntilEngOutput 1;
BA_ "SPN" SG_ 2566525950 EgrMassUntilEngOutput 22233;
BA_ "SigType" SG_ 2566525950 EgrMassUntilColdStart 1;
BA_ "SPN" SG_ 2566525950 EgrMassUntilColdStart 22232;
BA_ "SigType" SG_ 2566525950 EngOutEnergyUntilCatTempThld 1;
BA_ "SPN" SG_ 2566525950 EngOutEnergyUntilCatTempThld 22231;
BA_ "SigType" SG_ 2566525950 EngOutEnergyUntilColdStart 1;
BA_ "SPN" SG_ 2566525950 EngOutEnergyUntilColdStart 22230;
BA_ "SigType" SG_ 2566525950 CatHeatEnergyUntilCatTempThld 1;
BA_ "SPN" SG_ 2566525950 CatHeatEnergyUntilCatTempThld 22229;
BA_ "SigType" SG_ 2566525950 CatHeatEnergyUntilEngOutput 1;
BA_ "SPN" SG_ 2566525950 CatHeatEnergyUntilEngOutput 22228;
BA_ "SigType" SG_ 2566525950 CatHeatEnergyUntilColdStart 1;
BA_ "SPN" SG_ 2566525950 CatHeatEnergyUntilColdStart 22227;
BA_ "SPN" SG_ 2566525694 SA_1 22260;
BA_ "SPN" SG_ 2566525694 TrailerType_1 22259;
BA_ "SPN" SG_ 2566525694 VehSegment_1 22258;
BA_ "SPN" SG_ 2566525694 MotGenRotation_1 22257;
BA_ "SPN" SG_ 2566525694 MotGenIdentification_1 22256;
BA_ "SPN" SG_ 2566525694 MotGenLocation_1 22255;
BA_ "SPN" SG_ 2566525694 AxleInstance_1 22254;
BA_ "SPN" SG_ 2566525694 NumOfAxleInstancesBeingReported 22253;
BA_ "SigType" SG_ 2566525438 TripLightOffSCRDEF 1;
BA_ "SPN" SG_ 2566525438 TripLightOffSCRDEF 22269;
BA_ "SigType" SG_ 2566525438 TotalLightOffSCRDEFUsed 1;
BA_ "SPN" SG_ 2566525438 TotalLightOffSCRDEFUsed 22268;
BA_ "SigType" SG_ 2566525182 OBPEventLocalHourOffset 1;
BA_ "GenSigStartValue" SG_ 2566525182 OBPEventLocalHourOffset 102;
BA_ "SPN" SG_ 2566525182 OBPEventLocalHourOffset 22942;
BA_ "SigType" SG_ 2566525182 OBPEventLocalMinuteOffset 1;
BA_ "GenSigStartValue" SG_ 2566525182 OBPEventLocalMinuteOffset 66;
BA_ "SPN" SG_ 2566525182 OBPEventLocalMinuteOffset 22941;
BA_ "SigType" SG_ 2566525182 OBPEventYear 1;
BA_ "SPN" SG_ 2566525182 OBPEventYear 22940;
BA_ "SigType" SG_ 2566525182 OBPEventDay 1;
BA_ "GenSigStartValue" SG_ 2566525182 OBPEventDay 1;
BA_ "SPN" SG_ 2566525182 OBPEventDay 22939;
BA_ "SigType" SG_ 2566525182 OBPEventMonth 1;
BA_ "GenSigStartValue" SG_ 2566525182 OBPEventMonth 1;
BA_ "SPN" SG_ 2566525182 OBPEventMonth 22938;
BA_ "SigType" SG_ 2566525182 OBPEventHours 1;
BA_ "SPN" SG_ 2566525182 OBPEventHours 22937;
BA_ "SigType" SG_ 2566525182 OBPEventMinutes 1;
BA_ "SPN" SG_ 2566525182 OBPEventMinutes 22936;
BA_ "SigType" SG_ 2566525182 OBPEventSeconds 1;
BA_ "SPN" SG_ 2566525182 OBPEventSeconds 22935;
BA_ "SigType" SG_ 2566524926 CapLmt 1;
BA_ "SPN" SG_ 2566524926 CapLmt 22964;
BA_ "SigType" SG_ 2566524926 CapUsed 1;
BA_ "SPN" SG_ 2566524926 CapUsed 22963;
BA_ "SigType" SG_ 2566524670 CapLmt 1;
BA_ "SPN" SG_ 2566524670 CapLmt 22960;
BA_ "SigType" SG_ 2566524670 CapUsed 1;
BA_ "SPN" SG_ 2566524670 CapUsed 22959;
BA_ "SigType" SG_ 2566524414 CapLmt 1;
BA_ "SPN" SG_ 2566524414 CapLmt 22956;
BA_ "SigType" SG_ 2566524414 CapUsed 1;
BA_ "SPN" SG_ 2566524414 CapUsed 22955;
BA_ "SigType" SG_ 2566524158 CapLmt 1;
BA_ "SPN" SG_ 2566524158 CapLmt 22952;
BA_ "SigType" SG_ 2566524158 CapUsed 1;
BA_ "SPN" SG_ 2566524158 CapUsed 22951;
BA_ "SigType" SG_ 2566523902 CapLmt 1;
BA_ "SPN" SG_ 2566523902 CapLmt 22948;
BA_ "SigType" SG_ 2566523902 CapUsed 1;
BA_ "SPN" SG_ 2566523902 CapUsed 22947;
BA_ "SigType" SG_ 2566523646 CapLmt 1;
BA_ "SPN" SG_ 2566523646 CapLmt 22944;
BA_ "SigType" SG_ 2566523646 CapUsed 1;
BA_ "SPN" SG_ 2566523646 CapUsed 22943;
BA_ "SPN" SG_ 2566091006 InstanceOfStDataSet2 22677;
BA_ "SigType" SG_ 2566091006 HVILSt 4;
BA_ "SPN" SG_ 2566091006 HVILSt 22676;
BA_ "SigType" SG_ 2566091006 Cur 1;
BA_ "SPN" SG_ 2566091006 Cur 22675;
BA_ "SigType" SG_ 2566091006 V 1;
BA_ "SPN" SG_ 2566091006 V 22674;
BA_ "SigType" SG_ 2566090750 HVILSt 4;
BA_ "SPN" SG_ 2566090750 HVILSt 22673;
BA_ "SigType" SG_ 2566090750 Cur 1;
BA_ "SPN" SG_ 2566090750 Cur 22672;
BA_ "SigType" SG_ 2566090750 V 1;
BA_ "SPN" SG_ 2566090750 V 22671;
BA_ "SigType" SG_ 2566090494 HVILSt 4;
BA_ "SPN" SG_ 2566090494 HVILSt 22670;
BA_ "SigType" SG_ 2566090494 Cur 1;
BA_ "SPN" SG_ 2566090494 Cur 22669;
BA_ "SigType" SG_ 2566090494 V 1;
BA_ "SPN" SG_ 2566090494 V 22668;
BA_ "SigType" SG_ 2566090238 HVILSt 4;
BA_ "SPN" SG_ 2566090238 HVILSt 22667;
BA_ "SigType" SG_ 2566090238 Cur 1;
BA_ "SPN" SG_ 2566090238 Cur 22666;
BA_ "SigType" SG_ 2566090238 V 1;
BA_ "SPN" SG_ 2566090238 V 22665;
BA_ "SigType" SG_ 2566089982 HVILSt 4;
BA_ "SPN" SG_ 2566089982 HVILSt 22664;
BA_ "SigType" SG_ 2566089982 Cur 1;
BA_ "SPN" SG_ 2566089982 Cur 22663;
BA_ "SigType" SG_ 2566089982 V 1;
BA_ "SPN" SG_ 2566089982 V 22662;
BA_ "SigType" SG_ 2566089726 HVILSt 4;
BA_ "SPN" SG_ 2566089726 HVILSt 22661;
BA_ "SigType" SG_ 2566089726 Cur 1;
BA_ "SPN" SG_ 2566089726 Cur 22660;
BA_ "SigType" SG_ 2566089726 V 1;
BA_ "SPN" SG_ 2566089726 V 22659;
BA_ "SigType" SG_ 2566089470 HVILSt 4;
BA_ "SPN" SG_ 2566089470 HVILSt 22658;
BA_ "SigType" SG_ 2566089470 Cur 1;
BA_ "SPN" SG_ 2566089470 Cur 22657;
BA_ "SigType" SG_ 2566089470 V 1;
BA_ "SPN" SG_ 2566089470 V 22656;
BA_ "SigType" SG_ 2566089214 HVILSt 4;
BA_ "SPN" SG_ 2566089214 HVILSt 22655;
BA_ "SigType" SG_ 2566089214 Cur 1;
BA_ "SPN" SG_ 2566089214 Cur 22654;
BA_ "SigType" SG_ 2566089214 V 1;
BA_ "SPN" SG_ 2566089214 V 22653;
BA_ "SigType" SG_ 2566088958 HVILSt 4;
BA_ "SPN" SG_ 2566088958 HVILSt 22652;
BA_ "SigType" SG_ 2566088958 Cur 1;
BA_ "SPN" SG_ 2566088958 Cur 22651;
BA_ "SigType" SG_ 2566088958 V 1;
BA_ "SPN" SG_ 2566088958 V 22650;
BA_ "SigType" SG_ 2566088702 HVILSt 4;
BA_ "SPN" SG_ 2566088702 HVILSt 22649;
BA_ "SigType" SG_ 2566088702 Cur 1;
BA_ "SPN" SG_ 2566088702 Cur 22648;
BA_ "SigType" SG_ 2566088702 V 1;
BA_ "SPN" SG_ 2566088702 V 22647;
BA_ "SigType" SG_ 2566088446 HVILSt 4;
BA_ "SPN" SG_ 2566088446 HVILSt 22646;
BA_ "SigType" SG_ 2566088446 Cur 1;
BA_ "SPN" SG_ 2566088446 Cur 22645;
BA_ "SigType" SG_ 2566088446 V 1;
BA_ "SPN" SG_ 2566088446 V 22644;
BA_ "SigType" SG_ 2566088190 HVILSt 4;
BA_ "SPN" SG_ 2566088190 HVILSt 22643;
BA_ "SigType" SG_ 2566088190 Cur 1;
BA_ "SPN" SG_ 2566088190 Cur 22642;
BA_ "SigType" SG_ 2566088190 V 1;
BA_ "SPN" SG_ 2566088190 V 22641;
BA_ "SigType" SG_ 2364761342 RightTransOutShaftDirSpd 1;
BA_ "SPN" SG_ 2364761342 RightTransOutShaftDirSpd 22626;
BA_ "SigType" SG_ 2364761342 LeftTransOutShaftDirSpd 1;
BA_ "SPN" SG_ 2364761342 LeftTransOutShaftDirSpd 22625;
BA_ "SigType" SG_ 2364761086 NomChargeCurLmt 1;
BA_ "GenSigStartValue" SG_ 2364761086 NomChargeCurLmt 32000;
BA_ "SPN" SG_ 2364761086 NomChargeCurLmt 22848;
BA_ "SigType" SG_ 2364761086 NomDisCurLmt 1;
BA_ "SPN" SG_ 2364761086 NomDisCurLmt 22847;
BA_ "SigType" SG_ 2364761086 MaxCurChargeCurLmt 1;
BA_ "GenSigStartValue" SG_ 2364761086 MaxCurChargeCurLmt 32000;
BA_ "SPN" SG_ 2364761086 MaxCurChargeCurLmt 22605;
BA_ "SigType" SG_ 2364761086 MaxCurDisCurLmt 1;
BA_ "SPN" SG_ 2364761086 MaxCurDisCurLmt 22604;
BA_ "SigType" SG_ 2364760830 Cur 1;
BA_ "SPN" SG_ 2364760830 Cur 22603;
BA_ "SigType" SG_ 2364760830 Lvl 1;
BA_ "SPN" SG_ 2364760830 Lvl 22602;
BA_ "SigType" SG_ 2364760830 AvailableChargePwr 1;
BA_ "SPN" SG_ 2364760830 AvailableChargePwr 22601;
BA_ "SigType" SG_ 2364760830 AvailableDisPwr 1;
BA_ "SPN" SG_ 2364760830 AvailableDisPwr 22600;
BA_ "SigType" SG_ 2364760574 NomChargeCurLmt 1;
BA_ "GenSigStartValue" SG_ 2364760574 NomChargeCurLmt 32000;
BA_ "SPN" SG_ 2364760574 NomChargeCurLmt 22846;
BA_ "SigType" SG_ 2364760574 NomDisCurLmt 1;
BA_ "SPN" SG_ 2364760574 NomDisCurLmt 22845;
BA_ "SigType" SG_ 2364760574 MaxCurChargeCurLmt 1;
BA_ "GenSigStartValue" SG_ 2364760574 MaxCurChargeCurLmt 32000;
BA_ "SPN" SG_ 2364760574 MaxCurChargeCurLmt 22583;
BA_ "SigType" SG_ 2364760574 MaxCurDisCurLmt 1;
BA_ "SPN" SG_ 2364760574 MaxCurDisCurLmt 22582;
BA_ "SigType" SG_ 2364760318 Cur 1;
BA_ "SPN" SG_ 2364760318 Cur 22581;
BA_ "SigType" SG_ 2364760318 Lvl 1;
BA_ "SPN" SG_ 2364760318 Lvl 22580;
BA_ "SigType" SG_ 2364760318 AvailableChargePwr 1;
BA_ "SPN" SG_ 2364760318 AvailableChargePwr 22579;
BA_ "SigType" SG_ 2364760318 AvailableDisPwr 1;
BA_ "SPN" SG_ 2364760318 AvailableDisPwr 22578;
BA_ "SigType" SG_ 2364760062 NomChargeCurLmt 1;
BA_ "GenSigStartValue" SG_ 2364760062 NomChargeCurLmt 32000;
BA_ "SPN" SG_ 2364760062 NomChargeCurLmt 22844;
BA_ "SigType" SG_ 2364760062 NomDisCurLmt 1;
BA_ "SPN" SG_ 2364760062 NomDisCurLmt 22843;
BA_ "SigType" SG_ 2364760062 MaxCurChargeCurLmt 1;
BA_ "GenSigStartValue" SG_ 2364760062 MaxCurChargeCurLmt 32000;
BA_ "SPN" SG_ 2364760062 MaxCurChargeCurLmt 22561;
BA_ "SigType" SG_ 2364760062 MaxCurDisCurLmt 1;
BA_ "SPN" SG_ 2364760062 MaxCurDisCurLmt 22560;
BA_ "SigType" SG_ 2364759806 Cur 1;
BA_ "SPN" SG_ 2364759806 Cur 22559;
BA_ "SigType" SG_ 2364759806 Lvl 1;
BA_ "SPN" SG_ 2364759806 Lvl 22558;
BA_ "SigType" SG_ 2364759806 AvailableChargePwr 1;
BA_ "SPN" SG_ 2364759806 AvailableChargePwr 22557;
BA_ "SigType" SG_ 2364759806 AvailableDisPwr 1;
BA_ "SPN" SG_ 2364759806 AvailableDisPwr 22556;
BA_ "SigType" SG_ 2364759550 NomChargeCurLmt 1;
BA_ "GenSigStartValue" SG_ 2364759550 NomChargeCurLmt 32000;
BA_ "SPN" SG_ 2364759550 NomChargeCurLmt 22842;
BA_ "SigType" SG_ 2364759550 NomDisCurLmt 1;
BA_ "SPN" SG_ 2364759550 NomDisCurLmt 22841;
BA_ "SigType" SG_ 2364759550 MaxCurChargeCurLmt 1;
BA_ "GenSigStartValue" SG_ 2364759550 MaxCurChargeCurLmt 32000;
BA_ "SPN" SG_ 2364759550 MaxCurChargeCurLmt 22539;
BA_ "SigType" SG_ 2364759550 MaxCurDisCurLmt 1;
BA_ "SPN" SG_ 2364759550 MaxCurDisCurLmt 22538;
BA_ "SigType" SG_ 2364759294 Cur 1;
BA_ "SPN" SG_ 2364759294 Cur 22537;
BA_ "SigType" SG_ 2364759294 Lvl 1;
BA_ "SPN" SG_ 2364759294 Lvl 22536;
BA_ "SigType" SG_ 2364759294 AvailableChargePwr 1;
BA_ "SPN" SG_ 2364759294 AvailableChargePwr 22535;
BA_ "SigType" SG_ 2364759294 AvailableDisPwr 1;
BA_ "SPN" SG_ 2364759294 AvailableDisPwr 22534;
BA_ "SigType" SG_ 2364759038 NomChargeCurLmt 1;
BA_ "GenSigStartValue" SG_ 2364759038 NomChargeCurLmt 32000;
BA_ "SPN" SG_ 2364759038 NomChargeCurLmt 22840;
BA_ "SigType" SG_ 2364759038 NomDisCurLmt 1;
BA_ "SPN" SG_ 2364759038 NomDisCurLmt 22839;
BA_ "SigType" SG_ 2364759038 MaxCurChargeCurLmt 1;
BA_ "GenSigStartValue" SG_ 2364759038 MaxCurChargeCurLmt 32000;
BA_ "SPN" SG_ 2364759038 MaxCurChargeCurLmt 22517;
BA_ "SigType" SG_ 2364759038 MaxCurDisCurLmt 1;
BA_ "SPN" SG_ 2364759038 MaxCurDisCurLmt 22516;
BA_ "SigType" SG_ 2364758782 Cur 1;
BA_ "SPN" SG_ 2364758782 Cur 22515;
BA_ "SigType" SG_ 2364758782 Lvl 1;
BA_ "SPN" SG_ 2364758782 Lvl 22514;
BA_ "SigType" SG_ 2364758782 AvailableChargePwr 1;
BA_ "SPN" SG_ 2364758782 AvailableChargePwr 22513;
BA_ "SigType" SG_ 2364758782 AvailableDisPwr 1;
BA_ "SPN" SG_ 2364758782 AvailableDisPwr 22512;
BA_ "SigType" SG_ 2364758526 NomChargeCurLmt 1;
BA_ "GenSigStartValue" SG_ 2364758526 NomChargeCurLmt 32000;
BA_ "SPN" SG_ 2364758526 NomChargeCurLmt 22838;
BA_ "SigType" SG_ 2364758526 NomDisCurLmt 1;
BA_ "SPN" SG_ 2364758526 NomDisCurLmt 22837;
BA_ "SigType" SG_ 2364758526 MaxCurChargeCurLmt 1;
BA_ "GenSigStartValue" SG_ 2364758526 MaxCurChargeCurLmt 32000;
BA_ "SPN" SG_ 2364758526 MaxCurChargeCurLmt 22495;
BA_ "SigType" SG_ 2364758526 MaxCurDisCurLmt 1;
BA_ "SPN" SG_ 2364758526 MaxCurDisCurLmt 22494;
VAL_ 2365205758 HVInternalContactor8St22489 3 "Not Available" 2 "Error" 1 "Contactor Closed" 0 "Contactor Open" ;
VAL_ 2365205758 HVInternalContactor7St22488 3 "Not Available" 2 "Error" 1 "Contactor Closed" 0 "Contactor Open" ;
VAL_ 2365205758 HVInternalContactor6St22487 3 "Not Available" 2 "Error" 1 "Contactor Closed" 0 "Contactor Open" ;
VAL_ 2365205758 HVInternalContactor5St22486 3 "Not Available" 2 "Error" 1 "Contactor Closed" 0 "Contactor Open" ;
VAL_ 2365205758 HVInternalContactor4St22485 3 "Not Available" 2 "Error" 1 "Contactor Closed" 0 "Contactor Open" ;
VAL_ 2365205758 HVInternalContactor3St22484 3 "Not Available" 2 "Error" 1 "Contactor Closed" 0 "Contactor Open" ;
VAL_ 2365205758 HVInternalContactor2St22483 3 "Not Available" 2 "Error" 1 "Contactor Closed" 0 "Contactor Open" ;
VAL_ 2365205758 HVInternalContactor1St22482 3 "Not Available" 2 "Error" 1 "Contactor Closed" 0 "Contactor Open" ;
VAL_ 2365205758 HVInternalContactor8St 3 "Not Available" 2 "Error" 1 "Contactor Closed" 0 "Contactor Open" ;
VAL_ 2365205758 HVInternalContactor7St 3 "Not Available" 2 "Error" 1 "Contactor Closed" 0 "Contactor Open" ;
VAL_ 2365205758 HVInternalContactor6St 3 "Not Available" 2 "Error" 1 "Contactor Closed" 0 "Contactor Open" ;
VAL_ 2365205758 HVInternalContactor5St 3 "Not Available" 2 "Error" 1 "Contactor Closed" 0 "Contactor Open" ;
VAL_ 2365205758 HVInternalContactor4St 3 "Not Available" 2 "Error" 1 "Contactor Closed" 0 "Contactor Open" ;
VAL_ 2365205758 HVInternalContactor3St 3 "Not Available" 2 "Error" 1 "Contactor Closed" 0 "Contactor Open" ;
VAL_ 2365205758 HVInternalContactor2St 3 "Not Available" 2 "Error" 1 "Contactor Closed" 0 "Contactor Open" ;
VAL_ 2365205758 HVInternalContactor1St 3 "Not Available" 2 "Error" 1 "Contactor Closed" 0 "Contactor Open" ;
VAL_ 2365205502 HVInternalContactor8St22467 3 "Not Available" 2 "Error" 1 "Contactor Closed" 0 "Contactor Open" ;
VAL_ 2365205502 HVInternalContactor7St22466 3 "Not Available" 2 "Error" 1 "Contactor Closed" 0 "Contactor Open" ;
VAL_ 2365205502 HVInternalContactor6St22465 3 "Not Available" 2 "Error" 1 "Contactor Closed" 0 "Contactor Open" ;
VAL_ 2365205502 HVInternalContactor5St22464 3 "Not Available" 2 "Error" 1 "Contactor Closed" 0 "Contactor Open" ;
VAL_ 2365205502 HVInternalContactor4St22463 3 "Not Available" 2 "Error" 1 "Contactor Closed" 0 "Contactor Open" ;
VAL_ 2365205502 HVInternalContactor3St22462 3 "Not Available" 2 "Error" 1 "Contactor Closed" 0 "Contactor Open" ;
VAL_ 2365205502 HVInternalContactor2St22461 3 "Not Available" 2 "Error" 1 "Contactor Closed" 0 "Contactor Open" ;
VAL_ 2365205502 HVInternalContactor1St22460 3 "Not Available" 2 "Error" 1 "Contactor Closed" 0 "Contactor Open" ;
VAL_ 2365205502 HVInternalContactor8St 3 "Not Available" 2 "Error" 1 "Contactor Closed" 0 "Contactor Open" ;
VAL_ 2365205502 HVInternalContactor7St 3 "Not Available" 2 "Error" 1 "Contactor Closed" 0 "Contactor Open" ;
VAL_ 2365205502 HVInternalContactor6St 3 "Not Available" 2 "Error" 1 "Contactor Closed" 0 "Contactor Open" ;
VAL_ 2365205502 HVInternalContactor5St 3 "Not Available" 2 "Error" 1 "Contactor Closed" 0 "Contactor Open" ;
VAL_ 2365205502 HVInternalContactor4St 3 "Not Available" 2 "Error" 1 "Contactor Closed" 0 "Contactor Open" ;
VAL_ 2365205502 HVInternalContactor3St 3 "Not Available" 2 "Error" 1 "Contactor Closed" 0 "Contactor Open" ;
VAL_ 2365205502 HVInternalContactor2St 3 "Not Available" 2 "Error" 1 "Contactor Closed" 0 "Contactor Open" ;
VAL_ 2365205502 HVInternalContactor1St 3 "Not Available" 2 "Error" 1 "Contactor Closed" 0 "Contactor Open" ;
VAL_ 2365205246 HVInternalContactor8St22445 3 "Not Available" 2 "Error" 1 "Contactor Closed" 0 "Contactor Open" ;
VAL_ 2365205246 HVInternalContactor7St22444 3 "Not Available" 2 "Error" 1 "Contactor Closed" 0 "Contactor Open" ;
VAL_ 2365205246 HVInternalContactor6St22443 3 "Not Available" 2 "Error" 1 "Contactor Closed" 0 "Contactor Open" ;
VAL_ 2365205246 HVInternalContactor5St22442 3 "Not Available" 2 "Error" 1 "Contactor Closed" 0 "Contactor Open" ;
VAL_ 2365205246 HVInternalContactor4St22441 3 "Not Available" 2 "Error" 1 "Contactor Closed" 0 "Contactor Open" ;
VAL_ 2365205246 HVInternalContactor3St22440 3 "Not Available" 2 "Error" 1 "Contactor Closed" 0 "Contactor Open" ;
VAL_ 2365205246 HVInternalContactor2St22439 3 "Not Available" 2 "Error" 1 "Contactor Closed" 0 "Contactor Open" ;
VAL_ 2365205246 HVInternalContactor1St22438 3 "Not Available" 2 "Error" 1 "Contactor Closed" 0 "Contactor Open" ;
VAL_ 2365205246 HVInternalContactor8St 3 "Not Available" 2 "Error" 1 "Contactor Closed" 0 "Contactor Open" ;
VAL_ 2365205246 HVInternalContactor7St 3 "Not Available" 2 "Error" 1 "Contactor Closed" 0 "Contactor Open" ;
VAL_ 2365205246 HVInternalContactor6St 3 "Not Available" 2 "Error" 1 "Contactor Closed" 0 "Contactor Open" ;
VAL_ 2365205246 HVInternalContactor5St 3 "Not Available" 2 "Error" 1 "Contactor Closed" 0 "Contactor Open" ;
VAL_ 2365205246 HVInternalContactor4St 3 "Not Available" 2 "Error" 1 "Contactor Closed" 0 "Contactor Open" ;
VAL_ 2365205246 HVInternalContactor3St 3 "Not Available" 2 "Error" 1 "Contactor Closed" 0 "Contactor Open" ;
VAL_ 2365205246 HVInternalContactor2St 3 "Not Available" 2 "Error" 1 "Contactor Closed" 0 "Contactor Open" ;
VAL_ 2365205246 HVInternalContactor1St 3 "Not Available" 2 "Error" 1 "Contactor Closed" 0 "Contactor Open" ;
VAL_ 2365204990 HVInternalContactor8St22423 3 "Not Available" 2 "Error" 1 "Contactor Closed" 0 "Contactor Open" ;
VAL_ 2365204990 HVInternalContactor7St22422 3 "Not Available" 2 "Error" 1 "Contactor Closed" 0 "Contactor Open" ;
VAL_ 2365204990 HVInternalContactor6St22421 3 "Not Available" 2 "Error" 1 "Contactor Closed" 0 "Contactor Open" ;
VAL_ 2365204990 HVInternalContactor5St22420 3 "Not Available" 2 "Error" 1 "Contactor Closed" 0 "Contactor Open" ;
VAL_ 2365204990 HVInternalContactor4St22419 3 "Not Available" 2 "Error" 1 "Contactor Closed" 0 "Contactor Open" ;
VAL_ 2365204990 HVInternalContactor3St22418 3 "Not Available" 2 "Error" 1 "Contactor Closed" 0 "Contactor Open" ;
VAL_ 2365204990 HVInternalContactor2St22417 3 "Not Available" 2 "Error" 1 "Contactor Closed" 0 "Contactor Open" ;
VAL_ 2365204990 HVInternalContactor1St22416 3 "Not Available" 2 "Error" 1 "Contactor Closed" 0 "Contactor Open" ;
VAL_ 2365204990 HVInternalContactor8St 3 "Not Available" 2 "Error" 1 "Contactor Closed" 0 "Contactor Open" ;
VAL_ 2365204990 HVInternalContactor7St 3 "Not Available" 2 "Error" 1 "Contactor Closed" 0 "Contactor Open" ;
VAL_ 2365204990 HVInternalContactor6St 3 "Not Available" 2 "Error" 1 "Contactor Closed" 0 "Contactor Open" ;
VAL_ 2365204990 HVInternalContactor5St 3 "Not Available" 2 "Error" 1 "Contactor Closed" 0 "Contactor Open" ;
VAL_ 2365204990 HVInternalContactor4St 3 "Not Available" 2 "Error" 1 "Contactor Closed" 0 "Contactor Open" ;
VAL_ 2365204990 HVInternalContactor3St 3 "Not Available" 2 "Error" 1 "Contactor Closed" 0 "Contactor Open" ;
VAL_ 2365204990 HVInternalContactor2St 3 "Not Available" 2 "Error" 1 "Contactor Closed" 0 "Contactor Open" ;
VAL_ 2365204990 HVInternalContactor1St 3 "Not Available" 2 "Error" 1 "Contactor Closed" 0 "Contactor Open" ;
VAL_ 2365204734 HVInternalContactor8St22401 3 "Not Available" 2 "Error" 1 "Contactor Closed" 0 "Contactor Open" ;
VAL_ 2365204734 HVInternalContactor7St22400 3 "Not Available" 2 "Error" 1 "Contactor Closed" 0 "Contactor Open" ;
VAL_ 2365204734 HVInternalContactor6St22399 3 "Not Available" 2 "Error" 1 "Contactor Closed" 0 "Contactor Open" ;
VAL_ 2365204734 HVInternalContactor5St22398 3 "Not Available" 2 "Error" 1 "Contactor Closed" 0 "Contactor Open" ;
VAL_ 2365204734 HVInternalContactor4St22397 3 "Not Available" 2 "Error" 1 "Contactor Closed" 0 "Contactor Open" ;
VAL_ 2365204734 HVInternalContactor3St22396 3 "Not Available" 2 "Error" 1 "Contactor Closed" 0 "Contactor Open" ;
VAL_ 2365204734 HVInternalContactor2St22395 3 "Not Available" 2 "Error" 1 "Contactor Closed" 0 "Contactor Open" ;
VAL_ 2365204734 HVInternalContactor1St22394 3 "Not Available" 2 "Error" 1 "Contactor Closed" 0 "Contactor Open" ;
VAL_ 2365204734 HVInternalContactor8St 3 "Not Available" 2 "Error" 1 "Contactor Closed" 0 "Contactor Open" ;
VAL_ 2365204734 HVInternalContactor7St 3 "Not Available" 2 "Error" 1 "Contactor Closed" 0 "Contactor Open" ;
VAL_ 2365204734 HVInternalContactor6St 3 "Not Available" 2 "Error" 1 "Contactor Closed" 0 "Contactor Open" ;
VAL_ 2365204734 HVInternalContactor5St 3 "Not Available" 2 "Error" 1 "Contactor Closed" 0 "Contactor Open" ;
VAL_ 2365204734 HVInternalContactor4St 3 "Not Available" 2 "Error" 1 "Contactor Closed" 0 "Contactor Open" ;
VAL_ 2365204734 HVInternalContactor3St 3 "Not Available" 2 "Error" 1 "Contactor Closed" 0 "Contactor Open" ;
VAL_ 2365204734 HVInternalContactor2St 3 "Not Available" 2 "Error" 1 "Contactor Closed" 0 "Contactor Open" ;
VAL_ 2365204734 HVInternalContactor1St 3 "Not Available" 2 "Error" 1 "Contactor Closed" 0 "Contactor Open" ;
VAL_ 2365204478 HVInternalContactor8St22379 3 "Not Available" 2 "Error" 1 "Contactor Closed" 0 "Contactor Open" ;
VAL_ 2365204478 HVInternalContactor7St22378 3 "Not Available" 2 "Error" 1 "Contactor Closed" 0 "Contactor Open" ;
VAL_ 2365204478 HVInternalContactor6St22377 3 "Not Available" 2 "Error" 1 "Contactor Closed" 0 "Contactor Open" ;
VAL_ 2365204478 HVInternalContactor5St22376 3 "Not Available" 2 "Error" 1 "Contactor Closed" 0 "Contactor Open" ;
VAL_ 2365204478 HVInternalContactor4St22375 3 "Not Available" 2 "Error" 1 "Contactor Closed" 0 "Contactor Open" ;
VAL_ 2365204478 HVInternalContactor3St22374 3 "Not Available" 2 "Error" 1 "Contactor Closed" 0 "Contactor Open" ;
VAL_ 2365204478 HVInternalContactor2St22373 3 "Not Available" 2 "Error" 1 "Contactor Closed" 0 "Contactor Open" ;
VAL_ 2365204478 HVInternalContactor1St22372 3 "Not Available" 2 "Error" 1 "Contactor Closed" 0 "Contactor Open" ;
VAL_ 2365204478 HVInternalContactor8St 3 "Not Available" 2 "Error" 1 "Contactor Closed" 0 "Contactor Open" ;
VAL_ 2365204478 HVInternalContactor7St 3 "Not Available" 2 "Error" 1 "Contactor Closed" 0 "Contactor Open" ;
VAL_ 2365204478 HVInternalContactor6St 3 "Not Available" 2 "Error" 1 "Contactor Closed" 0 "Contactor Open" ;
VAL_ 2365204478 HVInternalContactor5St 3 "Not Available" 2 "Error" 1 "Contactor Closed" 0 "Contactor Open" ;
VAL_ 2365204478 HVInternalContactor4St 3 "Not Available" 2 "Error" 1 "Contactor Closed" 0 "Contactor Open" ;
VAL_ 2365204478 HVInternalContactor3St 3 "Not Available" 2 "Error" 1 "Contactor Closed" 0 "Contactor Open" ;
VAL_ 2365204478 HVInternalContactor2St 3 "Not Available" 2 "Error" 1 "Contactor Closed" 0 "Contactor Open" ;
VAL_ 2365204478 HVInternalContactor1St 3 "Not Available" 2 "Error" 1 "Contactor Closed" 0 "Contactor Open" ;
VAL_ 2365203710 HVBusNegPreChargeRelaySt 3 "Not Available" 2 "Error" 1 "Relay Closed" 0 "Relay Open" ;
VAL_ 2365203710 HVBusPosPreChargeRelaySt 3 "Not Available" 2 "Error" 1 "Relay Closed" 0 "Relay Open" ;
VAL_ 2365203710 PwrHoldRelaySt 3 "Not Available" 2 "Error" 1 "On" 0 "Off" ;
VAL_ 2365203710 ExposureInd 3 "Not Available" 2 "Error" 1 "High voltage exposure may exist in the HVESS" 0 "No high voltage exposure has been detected in the HVESS" ;
VAL_ 2566530046 TlrType 15 "Not Available" 14 "Error" 13 "Data is not ready" 12 "Reserved" 11 "Reserved" 10 "Reserved" 9 "Reserved" 8 "Reserved" 7 "Reserved" 6 "Reserved" 5 "Unknown" 4 "Center Axle Trailer" 3 "Dolly" 2 "Full or Drawbar" 1 "Semi" 0 "Not applicable" ;
VAL_ 2566530046 VehSegment 15 "Not Available" 14 "Error" 13 "Data is not ready" 12 "Reserved" 11 "Reserved" 10 "Reserved" 9 "Reserved" 8 "Reserved" 7 "Reserved" 6 "Reserved" 5 "Trailer 5" 4 "Trailer 4" 3 "Trailer 3" 2 "Trailer 2" 1 "Trailer 1" 0 "Tractor" ;
VAL_ 2566530046 Rotation 15 "Not Available" 14 "Error" 13 "Data is not ready" 12 "Reserved" 11 "Reserved" 10 "Reserved" 9 "Reserved" 8 "Reserved" 7 "Reserved" 6 "Reserved" 5 "Reserved" 4 "Reserved" 3 "Negative Speed is used for all vehicle motion" 2 "Positive Speed is used for all vehicle motion" 1 "Negative Speed propels the vehicle forward" 0 "Positive Speed propels the vehicle forward" ;
VAL_ 2566530046 Id 15 "Not Availabla" 14 "Error" 13 "Data is not ready" 12 "Reserved" 11 "Reserved" 10 "Reserved" 9 "Reserved" 8 "Reserved" 7 "Reserved" 6 "Motor/Generator 6" 5 "Motor/Generator 5" 4 "Motor/Generator 4" 3 "Motor/Generator 3" 2 "Motor/Generator 2" 1 "Motor/Generator 1" 0 "No Motor/Generator" ;
VAL_ 2566530046 SPN22255 15 "Not Available" 14 "Error" 13 "Data is not ready" 12 "Reserved" 11 "Reserved" 10 "Reserved" 9 "Reserved" 8 "Reserved" 7 "Reserved" 6 "Reserved" 5 "Reserved" 4 "Electric Retarder" 3 "Left and Right Sides" 2 "Right Side- MG located on the right side of the axle when facing forward in the driver's seat" 1 "Left Side" 0 "Not Driven" ;
VAL_ 2566530046 AxleInstance 15 "Not available" 14 "Error" 13 "Data is not ready" 12 "Axle 12" 11 "Axle 11" 10 "Axle 10" 9 "Axle 9" 8 "Axle 8" 7 "Axle 7" 6 "Axle 6" 5 "Axle 5" 4 "Axle 4" 3 "Axle 3" 2 "Axle 2" 1 "Axle 1" 0 "No Axle" ;
VAL_ 2566529534 FullChargingComplete 3 "Not available" 2 "Error" 1 "Full charging complete" 0 "Full charging not complete" ;
VAL_ 2566529534 BulkChargingComplete 3 "Not available" 2 "Error" 1 "Bulk charging complete" 0 "Bulk charging not complete" ;
VAL_ 2633637886 TwoDEFDosingMode 255 "Not available" 254 "Error" 253 "Reserved" 252 "Reserved" 251 "Reserved" 0 "Off" ;
VAL_ 2365202174 EmbeddedIntegritySupport 3 "HVBCS CRC and Counter are not supported by the sender" 2 "Reserved" 1 "HVBCS protection is supported using J1939-76 SHM" 0 "HVBCS embedded CRC and Counter are supported by the sender" ;
VAL_ 2365202174 HVBusInterface8NegContactorSt 3 "Not Available" 2 "Error" 1 "Contactor Closed" 0 "Contactor Open" ;
VAL_ 2365202174 HVBusInterface8PosContactorSt 3 "Not Available" 2 "Error" 1 "Contactor Closed" 0 "Contactor Open" ;
VAL_ 2365202174 HVBusInterface7NegContactorSt 3 "Not Available" 2 "Error" 1 "Contactor Closed" 0 "Contactor Open" ;
VAL_ 2365202174 HVBusInterface7PosContactorSt 3 "Not Available" 2 "Error" 1 "Contactor Closed" 0 "Contactor Open" ;
VAL_ 2365202174 HVBusInterface6NegContactorSt 3 "Not Available" 2 "Error" 1 "Contactor Closed" 0 "Contactor Open" ;
VAL_ 2365202174 HVBusInterface6PosContactorSt 3 "Not Available" 2 "Error" 1 "Contactor Closed" 0 "Contactor Open" ;
VAL_ 2365202174 HVBusInterface5NegContactorSt 3 "Not Available" 2 "Error" 1 "Contactor Closed" 0 "Contactor Open" ;
VAL_ 2365202174 HVBusInterface5PosContactorSt 3 "Not Available" 2 "Error" 1 "Contactor Closed" 0 "Contactor Open" ;
VAL_ 2365202174 HVBusInterface4NegContactorSt 3 "Not Available" 2 "Error" 1 "Contactor Closed" 0 "Contactor Open" ;
VAL_ 2365202174 HVBusInterface4PosContactorSt 3 "Not Available" 2 "Error" 1 "Contactor Closed" 0 "Contactor Open" ;
VAL_ 2365202174 HVBusInterface3NegContactorSt 3 "Not Available" 2 "Error" 1 "Contactor Closed" 0 "Contactor Open" ;
VAL_ 2365202174 HVBusInterface3PosContactorSt 3 "Not Available" 2 "Error" 1 "Contactor Closed" 0 "Contactor Open" ;
VAL_ 2365202174 HVBusInterface2NegContactorSt 3 "Not Available" 2 "Error" 1 "Contactor Closed" 0 "Contactor Open" ;
VAL_ 2365202174 HVBusInterface2PosContactorSt 3 "Not Available" 2 "Error" 1 "Contactor Closed" 0 "Contactor Open" ;
VAL_ 2365202174 HVBusInterface1NegContactorSt 3 "Not Available" 2 "Error" 1 "Contactor Closed" 0 "Contactor Open" ;
VAL_ 2365202174 HVBusInterface1PosContactorSt 3 "Not Available" 2 "Error" 1 "Contactor Closed" 0 "Contactor Open" ;
VAL_ 2365201918 EmbeddedIntegritySupport 3 "HVBCC CRC and Counter are not supported by the sender" 2 "Reserved" 1 "HVBCC protection is supported using J1939-76 SHM" 0 "HVBCC embedded CRC and Counter are supported by the sender" ;
VAL_ 2365201918 HVBusInterface8ConnectCmd 3 "Don't care / Take no action" 2 "Reserved" 1 "Close Contactor" 0 "Open Contactor" ;
VAL_ 2365201918 HVBusInterface7ConnectCmd 3 "Don't care / Take no action" 2 "Reserved" 1 "Close Contactor" 0 "Open Contactor" ;
VAL_ 2365201918 HVBusInterface6ConnectCmd 3 "Don't care / Take no action" 2 "Reserved" 1 "Close Contactor" 0 "Open Contactor" ;
VAL_ 2365201918 HVBusInterface5ConnectCmd 3 "Don't care / Take no action" 2 "Reserved" 1 "Close Contactor" 0 "Open Contactor" ;
VAL_ 2365201918 HVBusInterface4ConnectCmd 3 "Don't care / Take no action" 2 "Reserved" 1 "Close Contactor" 0 "Open Contactor" ;
VAL_ 2365201918 HVBusInterface3ConnectCmd 3 "Don't care / Take no action" 2 "Reserved" 1 "Close Contactor" 0 "Open Contactor" ;
VAL_ 2365201918 HVBusInterface2ConnectCmd 3 "Don't care / Take no action" 2 "Reserved" 1 "Close Contactor" 0 "Open Contactor" ;
VAL_ 2365201918 HVBusInterface1ConnectCmd 3 "Don't care / Take no action" 2 "Reserved" 1 "Close Contactor" 0 "Open Contactor" ;
VAL_ 2432310526 OpSt 15 "Not Available" 14 "Error" 13 "Reserved for future assignment" 12 "Reserved for future assignment" 11 "Reserved for future assignment" 10 "Reserved for future assignment" 9 "Reserved for future assignment" 8 "Reserved for future assignment" 7 "Reserved for future assignment" 6 "Commanded Motor Current Disabled" 5 "Uncontrolled Shutdown Active" 4 "Controlled Shutdown Active" 3 "Derate Active" 2 "Alarm High Severity" 1 "Alarm" 0 "Normal" ;
VAL_ 2432310526 TempSt 7 "Not available" 6 "Error" 5 "Not Defined" 4 "Low Most severe" 3 "Low Least severe" 2 "In Range" 1 "High Least severe" 0 "High Most severe" ;
VAL_ 2432310270 OpSt 15 "Not Available" 14 "Error" 13 "Reserved for future assignment" 12 "Reserved for future assignment" 11 "Reserved for future assignment" 10 "Reserved for future assignment" 9 "Reserved for future assignment" 8 "Reserved for future assignment" 7 "Reserved for future assignment" 6 "Commanded Motor Current Disabled" 5 "Uncontrolled Shutdown Active" 4 "Controlled Shutdown Active" 3 "Derate Active" 2 "Alarm High Severity" 1 "Alarm" 0 "Normal" ;
VAL_ 2432310270 TempSt 7 "Not available" 6 "Error" 5 "Not Defined" 4 "Low Most severe" 3 "Low Least severe" 2 "In Range" 1 "High Least severe" 0 "High Most severe" ;
VAL_ 2566525694 VehSegment_4 15 "Not Available" 14 "Error" 13 "Data is not ready" 12 "Reserved" 11 "Reserved" 10 "Reserved" 9 "Reserved" 8 "Reserved" 7 "Reserved" 6 "Reserved" 5 "Trailer 5" 4 "Trailer 4" 3 "Trailer 3" 2 "Trailer 2" 1 "Trailer 1" 0 "Tractor" ;
VAL_ 2566525694 TrailerType_4 15 "Not Available" 14 "Error" 13 "Data is not ready" 12 "Reserved" 11 "Reserved" 10 "Reserved" 9 "Reserved" 8 "Reserved" 7 "Reserved" 6 "Reserved" 5 "Unknown" 4 "Center Axle Trailer" 3 "Dolly" 2 "Full or Drawbar" 1 "Semi" 0 "Not applicable" ;
VAL_ 2566525694 MotGenRotation_4 15 "Not Available" 14 "Error" 13 "Data is not ready" 12 "Reserved" 11 "Reserved" 10 "Reserved" 9 "Reserved" 8 "Reserved" 7 "Reserved" 6 "Reserved" 5 "Reserved" 4 "Reserved" 3 "Negative Speed is used for all vehicle motion" 2 "Positive Speed is used for all vehicle motion" 1 "Negative Speed propels the vehicle forward" 0 "Positive Speed propels the vehicle forward" ;
VAL_ 2566525694 MotGenLocation_4 15 "Not Available" 14 "Error" 13 "Data is not ready" 12 "Reserved" 11 "Reserved" 10 "Reserved" 9 "Reserved" 8 "Reserved" 7 "Reserved" 6 "Reserved" 5 "Reserved" 4 "Reserved" 3 "Left and Right Sides" 2 "Right Side- MG located on the right side of the axle when facing forward in the driver's seat" 1 "Left Side" 0 "Not Driven" ;
VAL_ 2566525694 MotGenIdentification_4 15 "Not Available" 14 "Error" 13 "Data is not ready" 12 "Reserved" 11 "Reserved" 10 "Reserved" 9 "Reserved" 8 "Reserved" 7 "Reserved" 6 "Motor/Generator 6" 5 "Motor/Generator 5" 4 "Motor/Generator 4" 3 "Motor/Generator 3" 2 "Motor/Generator 2" 1 "Motor/Generator 1" 0 "No Motor/Generator" ;
VAL_ 2566525694 AxleInstance_4 15 "Not available" 14 "Error" 13 "Data is not ready" 12 "Axle 12" 11 "Axle 11" 10 "Axle 10" 9 "Axle 9" 8 "Axle 8" 7 "Axle 7" 6 "Axle 6" 5 "Axle 5" 4 "Axle 4" 3 "Axle 3" 2 "Axle 2" 1 "Axle 1" 0 "No Axle" ;
VAL_ 2566525694 VehSegment_3 15 "Not Available" 14 "Error" 13 "Data is not ready" 12 "Reserved" 11 "Reserved" 10 "Reserved" 9 "Reserved" 8 "Reserved" 7 "Reserved" 6 "Reserved" 5 "Trailer 5" 4 "Trailer 4" 3 "Trailer 3" 2 "Trailer 2" 1 "Trailer 1" 0 "Tractor" ;
VAL_ 2566525694 TrailerType_3 15 "Not Available" 14 "Error" 13 "Data is not ready" 12 "Reserved" 11 "Reserved" 10 "Reserved" 9 "Reserved" 8 "Reserved" 7 "Reserved" 6 "Reserved" 5 "Unknown" 4 "Center Axle Trailer" 3 "Dolly" 2 "Full or Drawbar" 1 "Semi" 0 "Not applicable" ;
VAL_ 2566525694 MotGenRotation_3 15 "Not Available" 14 "Error" 13 "Data is not ready" 12 "Reserved" 11 "Reserved" 10 "Reserved" 9 "Reserved" 8 "Reserved" 7 "Reserved" 6 "Reserved" 5 "Reserved" 4 "Reserved" 3 "Negative Speed is used for all vehicle motion" 2 "Positive Speed is used for all vehicle motion" 1 "Negative Speed propels the vehicle forward" 0 "Positive Speed propels the vehicle forward" ;
VAL_ 2566525694 MotGenLocation_3 15 "Not Available" 14 "Error" 13 "Data is not ready" 12 "Reserved" 11 "Reserved" 10 "Reserved" 9 "Reserved" 8 "Reserved" 7 "Reserved" 6 "Reserved" 5 "Reserved" 4 "Reserved" 3 "Left and Right Sides" 2 "Right Side- MG located on the right side of the axle when facing forward in the driver's seat" 1 "Left Side" 0 "Not Driven" ;
VAL_ 2566525694 MotGenIdentification_3 15 "Not Available" 14 "Error" 13 "Data is not ready" 12 "Reserved" 11 "Reserved" 10 "Reserved" 9 "Reserved" 8 "Reserved" 7 "Reserved" 6 "Motor/Generator 6" 5 "Motor/Generator 5" 4 "Motor/Generator 4" 3 "Motor/Generator 3" 2 "Motor/Generator 2" 1 "Motor/Generator 1" 0 "No Motor/Generator" ;
VAL_ 2566525694 AxleInstance_3 15 "Not available" 14 "Error" 13 "Data is not ready" 12 "Axle 12" 11 "Axle 11" 10 "Axle 10" 9 "Axle 9" 8 "Axle 8" 7 "Axle 7" 6 "Axle 6" 5 "Axle 5" 4 "Axle 4" 3 "Axle 3" 2 "Axle 2" 1 "Axle 1" 0 "No Axle" ;
VAL_ 2566525694 VehSegment_2 15 "Not Available" 14 "Error" 13 "Data is not ready" 12 "Reserved" 11 "Reserved" 10 "Reserved" 9 "Reserved" 8 "Reserved" 7 "Reserved" 6 "Reserved" 5 "Trailer 5" 4 "Trailer 4" 3 "Trailer 3" 2 "Trailer 2" 1 "Trailer 1" 0 "Tractor" ;
VAL_ 2566525694 TrailerType_2 15 "Not Available" 14 "Error" 13 "Data is not ready" 12 "Reserved" 11 "Reserved" 10 "Reserved" 9 "Reserved" 8 "Reserved" 7 "Reserved" 6 "Reserved" 5 "Unknown" 4 "Center Axle Trailer" 3 "Dolly" 2 "Full or Drawbar" 1 "Semi" 0 "Not applicable" ;
VAL_ 2566525694 MotGenRotation_2 15 "Not Available" 14 "Error" 13 "Data is not ready" 12 "Reserved" 11 "Reserved" 10 "Reserved" 9 "Reserved" 8 "Reserved" 7 "Reserved" 6 "Reserved" 5 "Reserved" 4 "Reserved" 3 "Negative Speed is used for all vehicle motion" 2 "Positive Speed is used for all vehicle motion" 1 "Negative Speed propels the vehicle forward" 0 "Positive Speed propels the vehicle forward" ;
VAL_ 2566525694 MotGenLocation_2 15 "Not Available" 14 "Error" 13 "Data is not ready" 12 "Reserved" 11 "Reserved" 10 "Reserved" 9 "Reserved" 8 "Reserved" 7 "Reserved" 6 "Reserved" 5 "Reserved" 4 "Reserved" 3 "Left and Right Sides" 2 "Right Side- MG located on the right side of the axle when facing forward in the driver's seat" 1 "Left Side" 0 "Not Driven" ;
VAL_ 2566525694 MotGenIdentification_2 15 "Not Available" 14 "Error" 13 "Data is not ready" 12 "Reserved" 11 "Reserved" 10 "Reserved" 9 "Reserved" 8 "Reserved" 7 "Reserved" 6 "Motor/Generator 6" 5 "Motor/Generator 5" 4 "Motor/Generator 4" 3 "Motor/Generator 3" 2 "Motor/Generator 2" 1 "Motor/Generator 1" 0 "No Motor/Generator" ;
VAL_ 2566525694 AxleInstance_2 15 "Not available" 14 "Error" 13 "Data is not ready" 12 "Axle 12" 11 "Axle 11" 10 "Axle 10" 9 "Axle 9" 8 "Axle 8" 7 "Axle 7" 6 "Axle 6" 5 "Axle 5" 4 "Axle 4" 3 "Axle 3" 2 "Axle 2" 1 "Axle 1" 0 "No Axle" ;
VAL_ 2566525694 TrailerType_1 15 "Not Available" 14 "Error" 13 "Data is not ready" 12 "Reserved" 11 "Reserved" 10 "Reserved" 9 "Reserved" 8 "Reserved" 7 "Reserved" 6 "Reserved" 5 "Unknown" 4 "Center Axle Trailer" 3 "Dolly" 2 "Full or Drawbar" 1 "Semi" 0 "Not applicable" ;
VAL_ 2566525694 VehSegment_1 15 "Not Available" 14 "Error" 13 "Data is not ready" 12 "Reserved" 11 "Reserved" 10 "Reserved" 9 "Reserved" 8 "Reserved" 7 "Reserved" 6 "Reserved" 5 "Trailer 5" 4 "Trailer 4" 3 "Trailer 3" 2 "Trailer 2" 1 "Trailer 1" 0 "Tractor" ;
VAL_ 2566525694 MotGenRotation_1 15 "Not Available" 14 "Error" 13 "Data is not ready" 12 "Reserved" 11 "Reserved" 10 "Reserved" 9 "Reserved" 8 "Reserved" 7 "Reserved" 6 "Reserved" 5 "Reserved" 4 "Reserved" 3 "Negative Speed is used for all vehicle motion" 2 "Positive Speed is used for all vehicle motion" 1 "Negative Speed propels the vehicle forward" 0 "Positive Speed propels the vehicle forward" ;
VAL_ 2566525694 MotGenIdentification_1 15 "Not Available" 14 "Error" 13 "Data is not ready" 12 "Reserved" 11 "Reserved" 10 "Reserved" 9 "Reserved" 8 "Reserved" 7 "Reserved" 6 "Motor/Generator 6" 5 "Motor/Generator 5" 4 "Motor/Generator 4" 3 "Motor/Generator 3" 2 "Motor/Generator 2" 1 "Motor/Generator 1" 0 "No Motor/Generator" ;
VAL_ 2566525694 MotGenLocation_1 15 "Not Available" 14 "Error" 13 "Data is not ready" 12 "Reserved" 11 "Reserved" 10 "Reserved" 9 "Reserved" 8 "Reserved" 7 "Reserved" 6 "Reserved" 5 "Reserved" 4 "Reserved" 3 "Left and Right Sides" 2 "Right Side- MG located on the right side of the axle when facing forward in the driver's seat" 1 "Left Side" 0 "Not Driven" ;
VAL_ 2566525694 AxleInstance_1 15 "Not available" 14 "Error" 13 "Data is not ready" 12 "Axle 12" 11 "Axle 11" 10 "Axle 10" 9 "Axle 9" 8 "Axle 8" 7 "Axle 7" 6 "Axle 6" 5 "Axle 5" 4 "Axle 4" 3 "Axle 3" 2 "Axle 2" 1 "Axle 1" 0 "No Axle" ;
VAL_ 2566091006 InstanceOfStDataSet2 15 "Not available / Instance not specified" 14 "Instance 15" 13 "Instance 14" 12 "Instance 13" 11 "Instance 12" 10 "Instance 11" 9 "Instance 10" 8 "Instance 9" 7 "Instance 8" 6 "Instance 7" 5 "Instance 6" 4 "Instance 5" 3 "Instance 4" 2 "Instance 3" 1 "Instance 2" 0 "Instance 1" ;
VAL_ 2566091006 HVILSt 3 "Not Available" 2 "Error" 1 "HVIL Open" 0 "HVIL Closed" ;
VAL_ 2566090750 HVILSt 3 "Not Available" 2 "Error" 1 "HVIL Open" 0 "HVIL Closed" ;
VAL_ 2566090494 HVILSt 3 "Not Available" 2 "Error" 1 "HVIL Open" 0 "HVIL Closed" ;
VAL_ 2566090238 HVILSt 3 "Not Available" 2 "Error" 1 "HVIL Open" 0 "HVIL Closed" ;
VAL_ 2566089982 HVILSt 3 "Not Available" 2 "Error" 1 "HVIL Open" 0 "HVIL Closed" ;
VAL_ 2566089726 HVILSt 3 "Not Available" 2 "Error" 1 "HVIL Open" 0 "HVIL Closed" ;
VAL_ 2566089470 HVILSt 3 "Not Available" 2 "Error" 1 "HVIL Open" 0 "HVIL Closed" ;
VAL_ 2566089214 HVILSt 3 "Not Available" 2 "Error" 1 "HVIL Open" 0 "HVIL Closed" ;
VAL_ 2566088958 HVILSt 3 "Not Available" 2 "Error" 1 "HVIL Open" 0 "HVIL Closed" ;
VAL_ 2566088702 HVILSt 3 "Not Available" 2 "Error" 1 "HVIL Open" 0 "HVIL Closed" ;
VAL_ 2566088446 HVILSt 3 "Not Available" 2 "Error" 1 "HVIL Open" 0 "HVIL Closed" ;
VAL_ 2566088190 HVILSt 3 "Not Available" 2 "Error" 1 "HVIL Open" 0 "HVIL Closed" ;
